VERSION ""

NS_ :

BS_:

BU_: OLDC EWP2 iBAU PSB EWP ESC EVP2 Dummy EVP1 SCU AAF eCALL H_U AEB IBOX LCA MCU SPAS CGW OBC TMU EPB SMK BCF MDPS CPD vDCM ACU vBDM AAF_2 CCM AAF_3 CLU ICSC LVR LDC CDM VCMS FCA IBU SCC PLC VCRM TCU EMS TPMS BMS NEMS LDW_LKA AAF_Tester DATC eCall VESS VCU ODS

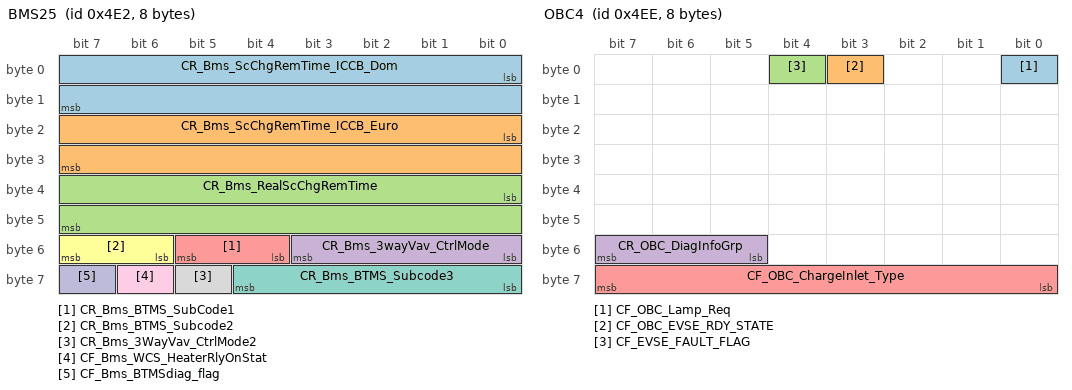
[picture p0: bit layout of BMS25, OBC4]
BO_ 1250 BMS25: 8 BMS
 SG_ CR_Bms_ScChgRemTime_ICCB_Dom : 0|16@1+ (1,0) [0|65535] "minute"  CGW,TMU
 SG_ CR_Bms_ScChgRemTime_ICCB_Euro : 16|16@1+ (1,0) [0|65535] "min"  CGW,TMU
 SG_ CR_Bms_RealScChgRemTime : 32|16@1+ (1,0) [0|65535] "minute"  CGW,TMU
 SG_ CR_Bms_3wayVav_CtrlMode : 48|4@1+ (1,0) [0|1] ""  TMU,vBDM
 SG_ CR_Bms_BTMS_SubCode1 : 52|2@1+ (1,0) [0|3] ""  TMU
 SG_ CR_Bms_BTMS_Subcode2 : 54|2@1+ (1,0) [0|3] ""  TMU
 SG_ CR_Bms_BTMS_Subcode3 : 56|5@1+ (1,0) [0|31] ""  TMU
 SG_ CR_Bms_3WayVav_CtrlMode2 : 61|1@1+ (1,0) [0|1] ""  TMU
 SG_ CF_Bms_WCS_HeaterRlyOnStat : 62|1@1+ (1,0) [0|1] ""  TMU
 SG_ CF_Bms_BTMSdiag_flag : 63|1@1+ (1,0) [0|1] "flag"  TMU

BO_ 1532 ODS13: 5 ODS
 SG_ CR_Ods_ID : 0|8@1+ (1,0) [0|255] ""  ACU
 SG_ ODS_Crc2Val : 8|8@1+ (1,0) [0|0] ""  ACU,Dummy
 SG_ ODS_AlvCnt2Val : 16|4@1+ (1,0) [0|15] ""  ACU,Dummy

BO_ 1262 OBC4: 8 OBC
 SG_ CF_OBC_Lamp_Req : 0|1@1+ (1,0) [0|1] ""  CGW,TMU,vBDM
 SG_ CF_OBC_EVSE_RDY_STATE : 3|1@1+ (1,0) [0|1] ""  BMS,TMU,VCU
 SG_ CF_EVSE_FAULT_FLAG : 4|1@1+ (1,0) [0|1] ""  CCM,CGW,TMU
 SG_ CR_OBC_DiagInfoGrp : 53|3@1+ (1,0) [0|7] ""  Dummy
 SG_ CF_OBC_ChargeInlet_Type : 56|8@1+ (1,0) [0|127] ""  CGW,TMU

BO_ 916 TCS13: 8 iBAU
 SG_ aBasis : 0|11@1+ (0.01,-10.23) [-10.23|10.24] "m/s^2"  Dummy
 SG_ BrakeLight : 11|1@1+ (1,0) [0|1] ""  Dummy
 SG_ DCEnable : 12|1@1+ (1,0) [0|1] ""  Dummy
 SG_ AliveCounterTCS : 13|3@1+ (1,0) [0|7] ""  CGW,vBDM
 SG_ Pre_TCS_CTL : 16|1@1+ (1,0) [0|1] ""  Dummy
 SG_ EBA_ACK : 17|1@1+ (1,0) [0|1] ""  AEB,SCC
 SG_ FCA_ACK : 18|1@1+ (1,0) [0|1] ""  Dummy
 SG_ DF_BF_STAT : 19|2@1+ (1,0) [0|3] ""  CGW
 SG_ SCCReqLim : 21|2@1+ (1,0) [0|3] ""  Dummy
 SG_ TQI_SCC : 23|9@1+ (0.390625,0) [0|199.609375] "%"  VCU
 SG_ ACCEL_REF_SCC : 32|11@1+ (0.01,-10.23) [-10.23|10.24] "m/s^2"  Dummy
 SG_ SCCEnable : 43|2@1+ (1,0) [0|3] ""  Dummy
 SG_ DriverOverride : 45|2@1+ (1,0) [0|3] ""  Dummy
 SG_ StandStill : 47|1@1+ (1,0) [0|1] ""  Dummy
 SG_ CheckSum_TCS3 : 48|4@1+ (1,0) [0|15] ""  Dummy
 SG_ SCC_EQUIP : 52|1@1+ (1,0) [0|1] ""  VCU
 SG_ PBRAKE_ACT : 53|1@1+ (1,0) [0|1] ""  CGW,H_U,TMU
 SG_ SCC_REQ : 54|1@1+ (1,0) [0|1] ""  VCU
 SG_ DriverBraking : 55|1@1+ (1,0) [0|1] ""  VESS
 SG_ DBS_ACK : 56|1@1+ (1,0) [0|1] ""  FCA,LDW_LKA
 SG_ CF_VSM_Avail : 57|2@1+ (1,0) [0|3] ""  Dummy
 SG_ FCA_CODED_STAT : 59|1@1+ (1,0) [0|0] ""  Dummy
 SG_ SCC_CODED_STAT : 60|1@1+ (1,0) [0|0] ""  VCU
 SG_ ESC_BcaRPlusSta : 61|2@1+ (1,0) [0|0] ""  Dummy
 SG_ FCA_EQUIP : 63|1@1+ (1,0) [0|1] ""  Dummy

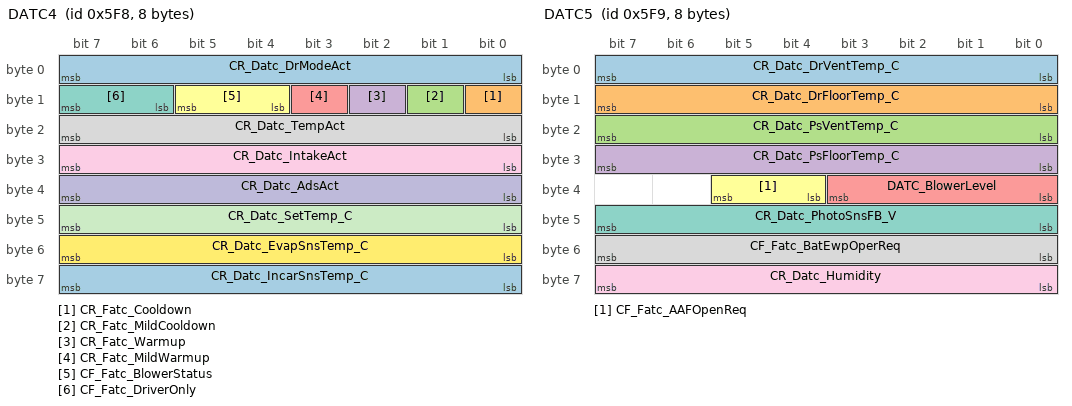
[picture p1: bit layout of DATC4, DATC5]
BO_ 1528 DATC4: 8 DATC
 SG_ CR_Datc_DrModeAct : 0|8@1+ (0.02,0) [0|5] "V"  VCU
 SG_ CR_Fatc_Cooldown : 8|1@1+ (1,0) [0|1] ""  LDC,VCU
 SG_ CR_Fatc_MildCooldown : 9|1@1+ (1,0) [0|1] ""  LDC,VCU
 SG_ CR_Fatc_Warmup : 10|1@1+ (1,0) [0|1] ""  LDC,VCU
 SG_ CR_Fatc_MildWarmup : 11|1@1+ (1,0) [0|1] ""  LDC,VCU
 SG_ CF_Fatc_BlowerStatus : 12|2@1+ (1,0) [0|3] ""  VCU
 SG_ CF_Fatc_DriverOnly : 14|2@1+ (1,0) [0|3] ""  CGW,VCU
 SG_ CR_Datc_TempAct : 16|8@1+ (0.02,0) [0|5] "V"  VCU
 SG_ CR_Datc_IntakeAct : 24|8@1+ (0.02,0) [0|5] "V"  VCU
 SG_ CR_Datc_AdsAct : 32|8@1+ (0.02,0) [0|5] "V"  VCU
 SG_ CR_Datc_SetTemp_C : 40|8@1+ (0.5,-40) [-40|60] "¡É"  TMU,VCU
 SG_ CR_Datc_EvapSnsTemp_C : 48|8@1+ (0.5,-40) [-40|60] "¡É"  VCU
 SG_ CR_Datc_IncarSnsTemp_C : 56|8@1+ (0.5,-40) [-40|60] "¡É"  BMS,TMU,VCU

BO_ 1529 DATC5: 8 DATC
 SG_ CR_Datc_DrVentTemp_C : 0|8@1+ (0.5,-40) [-40|60] "¡É"  CGW,VCU,vBDM
 SG_ CR_Datc_DrFloorTemp_C : 8|8@1+ (0.5,-40) [-40|60] "¡É"  VCU
 SG_ CR_Datc_PsVentTemp_C : 16|8@1+ (0.5,-40) [-40|60] "¡É"  VCU
 SG_ CR_Datc_PsFloorTemp_C : 24|8@1+ (0.5,-40) [-40|60] "¡É"  VCU
 SG_ DATC_BlowerLevel : 32|4@1+ (1,0) [0|15] "flag"  TMU,VCU
 SG_ CF_Fatc_AAFOpenReq : 36|2@1+ (1,0) [0|3] ""  AAF
 SG_ CR_Datc_PhotoSnsFB_V : 40|8@1+ (0.02,0) [0|5] "V"  VCU
 SG_ CF_Fatc_BatEwpOperReq : 48|8@1+ (30,0) [0|7620] "rpm"  BMS,MCU
 SG_ CR_Datc_Humidity : 56|8@1+ (0.5,0) [0|100] "%"  VCU

BO_ 2015 GST1: 8 CGW
 SG_ FRM_FORMAT : 0|8@1+ (1,0) [0|31] ""  AAF,ACU,BMS,DATC,EWP,LDC,MCU,ODS,VCU,VESS,iBAU
 SG_ SID : 8|8@1+ (1,0) [0|255] ""  AAF,ACU,BMS,DATC,EWP,LDC,MCU,ODS,VCU,VESS,iBAU
 SG_ REQ_RESPONSE : 16|8@1+ (1,0) [0|2] ""  AAF,ACU,BMS,DATC,EWP,LDC,MCU,ODS,VCU,VESS,iBAU

BO_ 1530 ODS11: 8 ODS
 SG_ ODS_Crc1Val : 0|8@1+ (1,0) [0|0] ""  ACU,Dummy
 SG_ ODS_AlvCnt1Val : 8|4@1+ (1,0) [0|15] ""  ACU,Dummy
 SG_ CR_Wcs_ErrStat : 32|8@1+ (1,0) [0|63] ""  ACU
 SG_ CR_Wcs_ClassStat : 40|8@1+ (1,0) [0|4] ""  ACU,CGW,H_U,TMU,VCU

BO_ 911 WHL_SPD13_FS: 5 iBAU
 SG_ CRC : 0|8@1+ (1,0) [0|0] ""  Dummy,ODS
 SG_ WHL_SPD13_AliveCounter : 8|4@1+ (1,0) [0|15] ""  Dummy,ODS
 SG_ WHL_SPD_RL : 12|14@1+ (0.03125,0) [0|511.96875] "km/h"  Dummy,ODS
 SG_ WHL_SPD_RR : 26|14@1+ (0.03125,0) [0|511.96875] "km/h"  Dummy,ODS

BO_ 1509 CCM1: 8 CCM
 SG_ CR_Ccm_MaxVolt_V : 0|16@1+ (0.1,0) [0|6553.5] "V"  BMS
 SG_ CR_Ccm_MaxCurr_A : 16|16@1+ (0.1,0) [0|6553.5] "A"  BMS,CGW,vBDM
 SG_ CR_Ccm_OutVolt : 32|16@1+ (0.1,0) [0|6553.5] "V"  BMS
 SG_ CR_Ccm_OutCurr : 48|16@1+ (0.1,0) [0|6553.5] "A"  BMS

BO_ 910 WHL_SPD12_FS: 5 iBAU
 SG_ CRC : 0|8@1+ (1,0) [0|0] ""  Dummy,ODS
 SG_ WHL_SPD12_AliveCounter : 8|4@1+ (1,0) [0|15] ""  Dummy,ODS
 SG_ WHL_SPD_FL : 12|14@1+ (0.03125,0) [0|511.96875] "km/h"  Dummy,ODS
 SG_ WHL_SPD_FR : 26|14@1+ (0.03125,0) [0|511.96875] "km/h"  Dummy,ODS

BO_ 1511 CCM3: 8 CCM
 SG_ CR_Ccm_EvseSAID : 0|16@1+ (1,0) [0|65535] ""  Dummy
 SG_ CR_Ccm_EvsePmaxID : 16|16@1+ (1,0) [0|65535] ""  Dummy
 SG_ CR_Ccm_EvsePmaxEntry : 32|16@1+ (1,0) [0|65535] ""  Dummy
 SG_ CR_Ccm_EvsePmax : 48|16@1+ (10,0) [0|655350] "W"  CGW,Dummy,vBDM

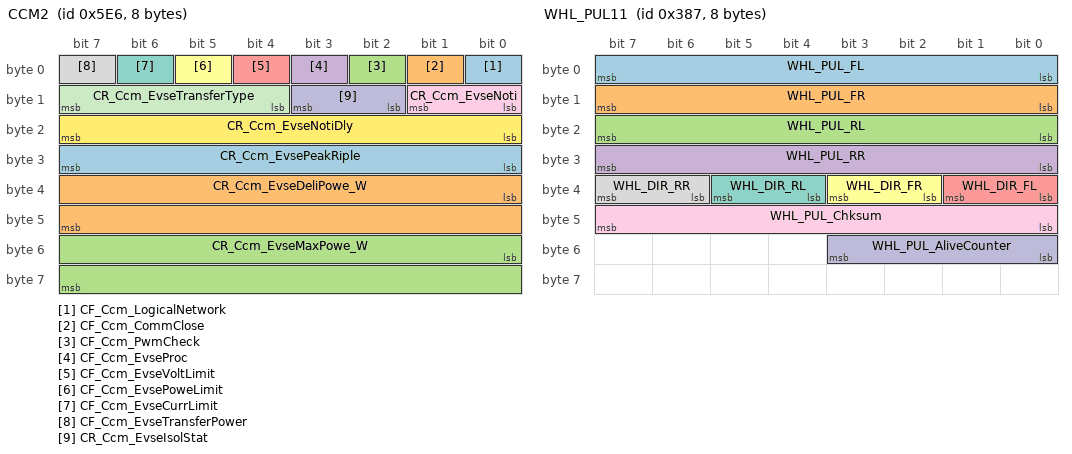
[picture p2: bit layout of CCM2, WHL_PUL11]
BO_ 1510 CCM2: 8 CCM
 SG_ CF_Ccm_LogicalNetwork : 0|1@1+ (1,0) [0|1] ""  BMS
 SG_ CF_Ccm_CommClose : 1|1@1+ (1,0) [0|1] ""  BMS
 SG_ CF_Ccm_PwmCheck : 2|1@1+ (1,0) [0|1] ""  BMS
 SG_ CF_Ccm_EvseProc : 3|1@1+ (1,0) [0|1] ""  BMS
 SG_ CF_Ccm_EvseVoltLimit : 4|1@1+ (1,0) [0|1] ""  BMS
 SG_ CF_Ccm_EvsePoweLimit : 5|1@1+ (1,0) [0|1] ""  BMS
 SG_ CF_Ccm_EvseCurrLimit : 6|1@1+ (1,0) [0|1] ""  BMS
 SG_ CF_Ccm_EvseTransferPower : 7|1@1+ (1,0) [0|1] ""  BMS
 SG_ CR_Ccm_EvseNoti : 8|2@1+ (1,0) [0|3] ""  BMS
 SG_ CR_Ccm_EvseIsolStat : 10|2@1+ (1,0) [0|3] ""  BMS,CGW,vBDM
 SG_ CR_Ccm_EvseTransferType : 12|4@1+ (1,0) [0|15] ""  BMS
 SG_ CR_Ccm_EvseNotiDly : 16|8@1+ (1,0) [0|255] "Sec"  BMS
 SG_ CR_Ccm_EvsePeakRiple : 24|8@1+ (1,0) [0|255] "A"  BMS
 SG_ CR_Ccm_EvseDeliPowe_W : 32|16@1+ (10,0) [0|655350] "Wh"  BMS
 SG_ CR_Ccm_EvseMaxPowe_W : 48|16@1+ (10,0) [0|655350] "W"  BMS

BO_ 1507 VESS1: 8 VESS
 SG_ CR_VCU_EcoLvl : 0|1@1+ (1,0) [0|1] ""  CGW,TMU,vBDM

BO_ 903 WHL_PUL11: 8 iBAU
 SG_ WHL_PUL_FL : 0|8@1+ (0.5,0) [0|127.5] "pulse count"  CGW,IBU,TMU,eCall
 SG_ WHL_PUL_FR : 8|8@1+ (0.5,0) [0|127.5] "pulse count"  CGW,IBU,TMU,eCall
 SG_ WHL_PUL_RL : 16|8@1+ (0.5,0) [0|127.5] "pulse count"  CGW,IBU,TMU,eCall
 SG_ WHL_PUL_RR : 24|8@1+ (0.5,0) [0|127.5] "pulse count"  CGW,IBU,TMU,eCall
 SG_ WHL_DIR_FL : 32|2@1+ (1,0) [0|3] ""  IBU,TMU
 SG_ WHL_DIR_FR : 34|2@1+ (1,0) [0|3] ""  IBU,TMU
 SG_ WHL_DIR_RL : 36|2@1+ (1,0) [0|3] ""  IBU,TMU
 SG_ WHL_DIR_RR : 38|2@1+ (1,0) [0|3] ""  IBU,TMU
 SG_ WHL_PUL_Chksum : 40|8@1+ (1,0) [0|255] ""  IBOX,IBU
 SG_ WHL_PUL_AliveCounter : 48|4@1+ (1,0) [0|14] ""  AEB,SCC

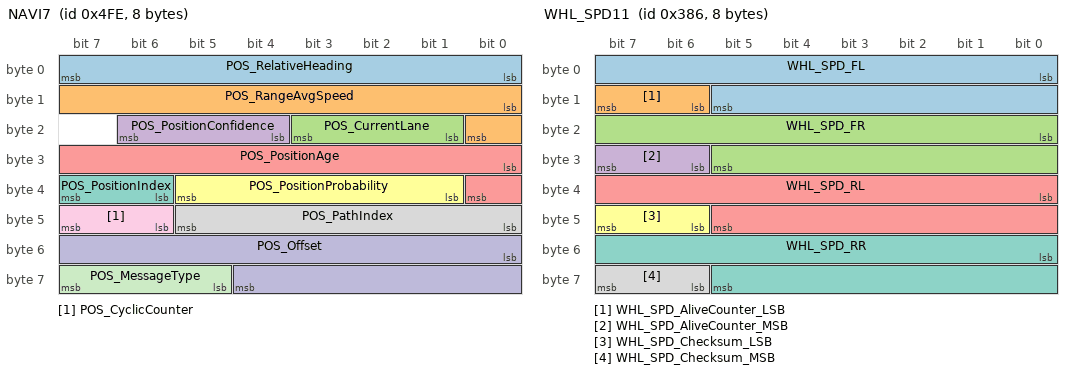
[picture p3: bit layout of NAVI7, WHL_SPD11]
BO_ 1278 NAVI7: 8 CGW
 SG_ POS_RelativeHeading : 0|8@1+ (1.417,0) [0|255] ""  VCU
 SG_ POS_RangeAvgSpeed : 8|9@1+ (1,0) [0|511] ""  VCU
 SG_ POS_CurrentLane : 17|3@1+ (1,0) [0|7] ""  VCU
 SG_ POS_PositionConfidence : 20|3@1+ (1,0) [0|7] ""  VCU
 SG_ POS_PositionAge : 24|9@1+ (5,0) [0|511] ""  VCU
 SG_ POS_PositionProbability : 33|5@1+ (3.333,0) [0|31] ""  VCU
 SG_ POS_PositionIndex : 38|2@1+ (1,0) [0|3] ""  VCU
 SG_ POS_PathIndex : 40|6@1+ (1,0) [0|63] ""  VCU
 SG_ POS_CyclicCounter : 46|2@1+ (1,0) [0|3] ""  VCU
 SG_ POS_Offset : 48|13@1+ (1,0) [0|8191] ""  VCU
 SG_ POS_MessageType : 61|3@1+ (1,0) [0|7] ""  VCU

BO_ 902 WHL_SPD11: 8 iBAU
 SG_ WHL_SPD_FL : 0|14@1+ (0.03125,0) [0|511.96875] "km/h"  ACU,CGW,DATC,EVP1,EVP2,IBU,MCU,ODS,VCU,VESS,vBDM
 SG_ WHL_SPD_AliveCounter_LSB : 14|2@1+ (1,0) [0|3] ""  CGW,ODS,TMU
 SG_ WHL_SPD_FR : 16|14@1+ (0.03125,0) [0|511.96875] "km/h"  ACU,DATC,EVP1,EVP2,IBU,MCU,ODS,VCU,VESS
 SG_ WHL_SPD_AliveCounter_MSB : 30|2@1+ (1,0) [0|3] ""  CGW,ODS,TMU
 SG_ WHL_SPD_RL : 32|14@1+ (0.03125,0) [0|511.96875] "km/h"  ACU,CDM,DATC,EVP1,EVP2,IBU,MCU,OBC,ODS,VCU,VESS
 SG_ WHL_SPD_Checksum_LSB : 46|2@1+ (1,0) [0|3] ""  CGW,ODS,TMU
 SG_ WHL_SPD_RR : 48|14@1+ (0.03125,0) [0|511.96875] "km/h"  ACU,CDM,DATC,EVP1,EVP2,IBU,MCU,OBC,ODS,VCU,VESS
 SG_ WHL_SPD_Checksum_MSB : 62|2@1+ (1,0) [0|3] ""  CGW,ODS,TMU

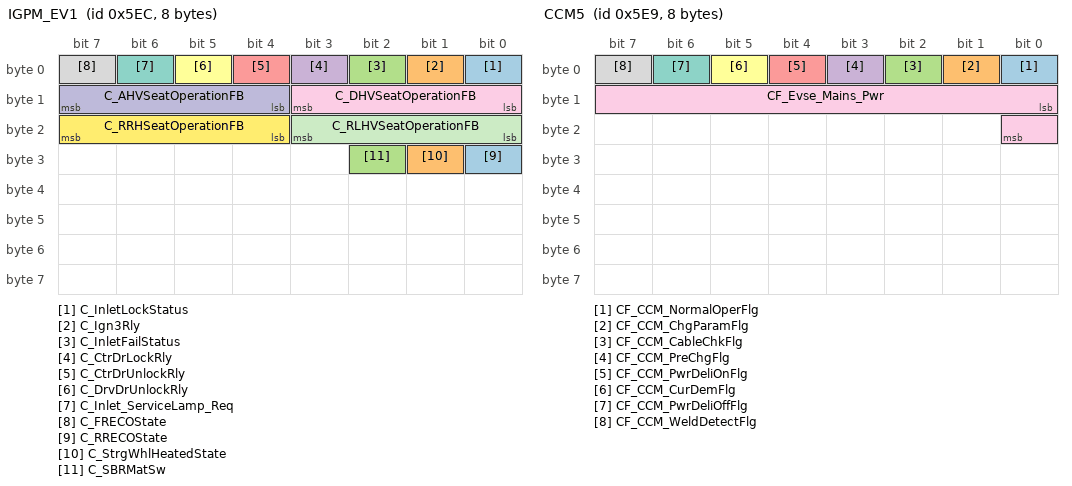
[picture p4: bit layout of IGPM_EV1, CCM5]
BO_ 1516 IGPM_EV1: 8 CGW
 SG_ C_InletLockStatus : 0|1@1+ (1,0) [0|1] ""  OBC
 SG_ C_Ign3Rly : 1|1@1+ (1,0) [0|1] ""  CDM,OBC
 SG_ C_InletFailStatus : 2|1@1+ (1,0) [0|1] ""  OBC
 SG_ C_CtrDrLockRly : 3|1@1+ (1,0) [0|0] ""  CDM,OBC
 SG_ C_CtrDrUnlockRly : 4|1@1+ (1,0) [0|0] ""  CDM,OBC
 SG_ C_DrvDrUnlockRly : 5|1@1+ (1,0) [0|0] ""  CDM,OBC
 SG_ C_Inlet_ServiceLamp_Req : 6|1@1+ (1,0) [0|0] ""  OBC
 SG_ C_FRECOState : 7|1@1+ (1,0) [0|1] ""  VCU
 SG_ C_DHVSeatOperationFB : 8|4@1+ (1,0) [0|15] ""  VCU
 SG_ C_AHVSeatOperationFB : 12|4@1+ (1,0) [0|15] ""  VCU
 SG_ C_RLHVSeatOperationFB : 16|4@1+ (1,0) [0|15] ""  VCU
 SG_ C_RRHSeatOperationFB : 20|4@1+ (1,0) [0|15] ""  VCU
 SG_ C_RRECOState : 24|1@1+ (1,0) [0|1] ""  VCU
 SG_ C_StrgWhlHeatedState : 25|1@1+ (1,0) [0|0] ""  VCU
 SG_ C_SBRMatSw : 26|1@1+ (1,0) [0|1] ""  VCU

BO_ 1276 AAF31: 8 AAF_3
 SG_ CF_Aaf31_ActFlapStatus : 0|2@1+ (1,0) [0|3] ""  AAF
 SG_ CF_Aaf31_ErrStatus : 6|10@1+ (1,0) [0|1023] ""  AAF
 SG_ CF_Aaf31_PStatus : 24|8@1+ (1,0) [0|100] "%"  AAF
 SG_ CF_Aaf31_PStatusSub : 32|8@1+ (1,0) [0|100] "%"  AAF

BO_ 1277 AAF21: 8 AAF_2
 SG_ CF_Aaf21_ActFlapStatus : 0|2@1+ (1,0) [0|3] ""  AAF
 SG_ CF_Aaf21_ErrStatus : 6|10@1+ (1,0) [0|1023] ""  AAF
 SG_ CF_Aaf21_PStatus : 24|8@1+ (1,0) [0|100] "%"  AAF
 SG_ CF_Aaf21_PStatusSub : 32|8@1+ (1,0) [0|100] "%"  AAF

BO_ 1513 CCM5: 8 CCM
 SG_ CF_CCM_NormalOperFlg : 0|1@1+ (1,0) [0|1] ""  BMS
 SG_ CF_CCM_ChgParamFlg : 1|1@1+ (1,0) [0|1] ""  BMS
 SG_ CF_CCM_CableChkFlg : 2|1@1+ (1,0) [0|1] ""  BMS,CGW,vBDM
 SG_ CF_CCM_PreChgFlg : 3|1@1+ (1,0) [0|1] ""  BMS
 SG_ CF_CCM_PwrDeliOnFlg : 4|1@1+ (1,0) [0|1] ""  BMS
 SG_ CF_CCM_CurDemFlg : 5|1@1+ (1,0) [0|1] ""  BMS
 SG_ CF_CCM_PwrDeliOffFlg : 6|1@1+ (1,0) [0|1] ""  BMS,OBC
 SG_ CF_CCM_WeldDetectFlg : 7|1@1+ (1,0) [0|1] ""  BMS
 SG_ CF_Evse_Mains_Pwr : 8|9@1+ (1,0) [0|400] "kW"  BMS,CGW,OBC

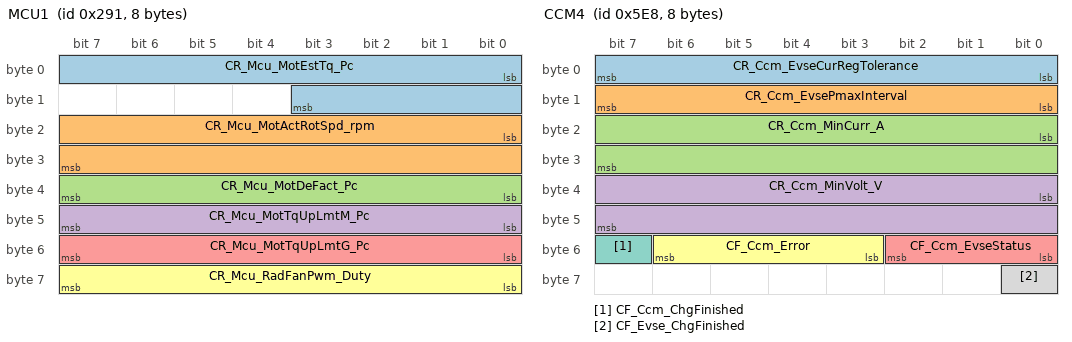
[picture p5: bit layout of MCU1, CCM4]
BO_ 657 MCU1: 8 MCU
 SG_ CR_Mcu_MotEstTq_Pc : 0|12@1- (0.048828125,0) [-100|99.951171875] "%"  BMS,CGW,LDC,NEMS,TMU,VCU,VESS,iBAU
 SG_ CR_Mcu_MotActRotSpd_rpm : 16|16@1- (1,0) [-32768|32767] "rpm"  AAF,ACU,BMS,CGW,LDC,NEMS,VCU,VESS,iBAU,vBDM
 SG_ CR_Mcu_MotDeFact_Pc : 32|8@1+ (0.3906,0) [0|99.61] "%"  VCU,iBAU
 SG_ CR_Mcu_MotTqUpLmtM_Pc : 40|8@1+ (0.3906,0) [0|99.61] "%"  VCU
 SG_ CR_Mcu_MotTqUpLmtG_Pc : 48|8@1+ (0.3906,0) [0|99.61] "%"  VCU
 SG_ CR_Mcu_RadFanPwm_Duty : 56|8@1+ (1,0) [0|100] "%"  AAF,BMS,VCU

BO_ 1512 CCM4: 8 CCM
 SG_ CR_Ccm_EvseCurRegTolerance : 0|8@1+ (1,0) [0|255] "A"  BMS
 SG_ CR_Ccm_EvsePmaxInterval : 8|8@1+ (1,0) [0|255] "Sec"  BMS
 SG_ CR_Ccm_MinCurr_A : 16|16@1+ (0.1,0) [0|6553.5] "A"  BMS
 SG_ CR_Ccm_MinVolt_V : 32|16@1+ (0.1,0) [0|6553.5] "V"  BMS
 SG_ CF_Ccm_EvseStatus : 48|3@1+ (1,0) [0|7] ""  BMS,OBC
 SG_ CF_Ccm_Error : 51|4@1+ (1,0) [0|15] ""  BMS
 SG_ CF_Ccm_ChgFinished : 55|1@1+ (1,0) [0|1] ""  BMS,CGW,OBC,vBDM
 SG_ CF_Evse_ChgFinished : 56|1@1+ (1,0) [0|1] ""  BMS,OBC

BO_ 1426 VCU5: 8 VCU
 SG_ CF_Vcu_DefrostCtr : 0|1@1+ (1,0) [0|1] ""  DATC,TMU
 SG_ CF_Vcu_LowSocLp : 1|1@1+ (1,0) [0|1] ""  CGW,TMU
 SG_ CF_Vcu_DteOff : 2|1@1+ (1,0) [0|1] ""  CGW,TMU
 SG_ CF_Vcu_SerLamp : 3|1@1+ (1,0) [0|1] ""  CGW,TMU
 SG_ CF_Vcu_EcoSco : 4|4@1+ (1,0) [0|15] ""  CGW,TMU
 SG_ CR_Vcu_ClimatePerm_W : 8|8@1+ (50,0) [0|12700] "W"  DATC,TMU
 SG_ CR_Vcu_FuelEco_KP100km : 16|8@1+ (0.5,0) [0|126.5] ""  CGW,TMU
 SG_ CR_Vcu_FatcCst : 24|8@1+ (10,0) [0|2550] "W"  CGW
 SG_ CF_Vcu_ChrgAlert : 32|1@1+ (1,0) [0|1] ""  CGW,TMU
 SG_ CF_Vcu_PwrDnMode : 33|1@1+ (1,0) [0|1] ""  CGW,TMU,vBDM
 SG_ CF_Vcu_CruOnLamp : 34|1@1+ (1,0) [0|1] ""  CGW,TMU
 SG_ CF_Vcu_CruSetLamp : 35|1@1+ (1,0) [0|1] ""  CGW,TMU
 SG_ CF_Vcu_ThiBatTir : 36|1@1+ (1,0) [0|1] ""  CGW,TMU
 SG_ CF_Vcu_LdcMod : 37|2@1+ (1,0) [0|2] ""  CGW,LDC,TMU
 SG_ CF_Vcu_ACnChr : 39|1@1+ (1,0) [0|1] ""  CGW,TMU
 SG_ CR_Vcu_TqMotClu_Pc : 40|8@1- (1,0) [-100|100] "%"  CGW,TMU
 SG_ CR_Vcu_FuelEco_KPK : 48|8@1+ (0.1,0) [0|25.5] "km/kWh"  CGW,LDC,TMU
 SG_ CF_Vcu_LdcInh : 56|1@1+ (1,0) [0|1] ""  CGW,LDC,TMU
 SG_ CF_Vcu_BrkLpReq : 57|1@1+ (1,0) [0|1] ""  CGW,TMU,iBAU
 SG_ CF_Vcu_EvMod : 58|4@1+ (1,0) [0|9] ""  CGW,DATC,NEMS,TMU,VESS,iBAU
 SG_ CF_Vcu_PgmRun5 : 62|2@1+ (1,0) [0|3] ""  CGW,TMU

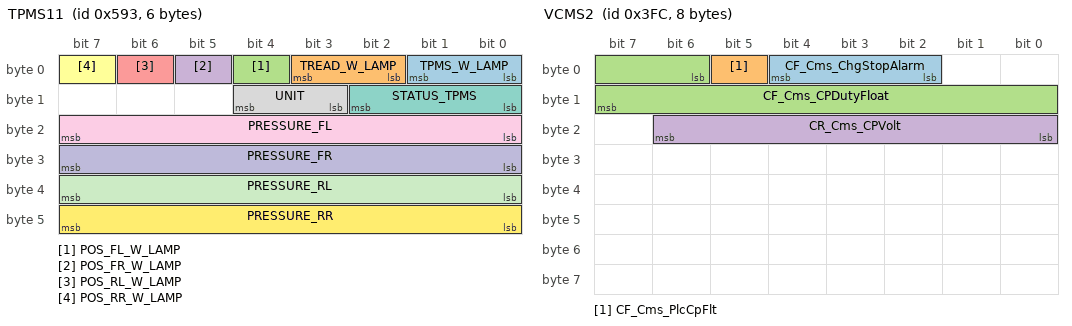
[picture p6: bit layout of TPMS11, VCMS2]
BO_ 1427 TPMS11: 6 IBU
 SG_ TPMS_W_LAMP : 0|2@1+ (1,0) [0|3] ""  CGW,H_U,TMU,vBDM
 SG_ TREAD_W_LAMP : 2|2@1+ (1,0) [0|3] ""  CGW,H_U,TMU
 SG_ POS_FL_W_LAMP : 4|1@1+ (1,0) [0|1] ""  CGW,H_U,TMU
 SG_ POS_FR_W_LAMP : 5|1@1+ (1,0) [0|1] ""  CGW,H_U,TMU
 SG_ POS_RL_W_LAMP : 6|1@1+ (1,0) [0|1] ""  CGW,H_U,TMU
 SG_ POS_RR_W_LAMP : 7|1@1+ (1,0) [0|1] ""  CGW,H_U,TMU
 SG_ STATUS_TPMS : 8|3@1+ (1,0) [0|0] ""  ESC,IBOX,ICSC,CGW
 SG_ UNIT : 11|2@1+ (1,0) [0|3] ""  IBOX,CGW
 SG_ PRESSURE_FL : 16|8@1+ (1,0) [0|255] "PSI"  IBOX,CGW
 SG_ PRESSURE_FR : 24|8@1+ (1,0) [0|255] "PSI"  IBOX,CGW
 SG_ PRESSURE_RL : 32|8@1+ (1,0) [0|255] "PSI"  IBOX,CGW
 SG_ PRESSURE_RR : 40|8@1+ (1,0) [0|255] "PSI"  IBOX,CGW

BO_ 1424 LDC1: 8 LDC
 SG_ CF_Ldc_Rdy : 0|1@1+ (1,0) [0|1] ""  TMU,VCU
 SG_ CF_Ldc_Controllable : 1|1@1+ (1,0) [0|1] ""  TMU,VCU
 SG_ CF_Ldc_12VCharge : 2|1@1+ (1,0) [0|1] ""  CGW,NEMS,TMU,VCU
 SG_ CF_Ldc_Pd_Stat : 3|1@1+ (1,0) [0|1] ""  CGW,MCU,NEMS,TMU,VCU
 SG_ CF_Ldc_AuxBatWrnLamp : 4|1@1+ (1,0) [0|1] ""  CGW,TMU
 SG_ CF_Ldc_AuxBatWrnAlarm : 5|1@1+ (1,0) [0|1] ""  CGW,TMU
 SG_ CF_Ldc_AuxBatCharge_Rqst : 6|1@1+ (1,0) [0|1] ""  TMU,VCU
 SG_ CF_Ldc_AuxBatCharge_Reset : 7|1@1+ (1,0) [0|1] ""  TMU,VCU
 SG_ CF_Ldc_Srvlamp_Rqst : 8|1@1+ (1,0) [0|1] ""  CGW,H_U,TMU,vBDM
 SG_ CF_Ldc_Flt : 9|1@1+ (1,0) [0|1] ""  AAF,BMS,CGW,H_U,MCU,NEMS,OBC,TMU,VCU
 SG_ CF_Ldc_AuxBatChg_State : 12|2@1+ (1,0) [0|3] ""  BMS,CGW
 SG_ CF_Ldc_RadFanCnt : 14|1@1+ (1,0) [0|1] ""  EMS,MCU,TMU
 SG_ CF_Ldc_Bat_dischrg : 15|1@1+ (1,0) [0|1] ""  CGW
 SG_ CR_Ldc_ActCur_LS_A : 16|8@1+ (1,0) [0|255] "A"  MCU,TMU
 SG_ CR_Ldc_RadFanReq_Duty : 24|8@1+ (1,0) [0|100] "%"  MCU,TMU,VCU
 SG_ CR_Ldc_ActVol_LS_V : 32|8@1+ (0.1,0) [0|25.5] "V"  CGW,MCU,OBC,TMU
 SG_ CR_Ldc_EWPRpmCnt : 40|8@1+ (20,0) [0|5000] "rpm"  MCU,TMU,VCU
 SG_ CR_Ldc_PwrMon_W : 48|8@1+ (10,0) [0|2550] "W"  CGW,TMU,VCU
 SG_ CR_Ldc_Tmp : 56|8@1+ (1,-100) [-100|155] "¡É"  AAF,TMU,VCU

BO_ 1019 VCMS1: 8 VCMS
 SG_ CF_Cms_PDStatus : 1|2@1+ (1,0) [0|3] ""  BMS,CCM,OBC
 SG_ CF_Cms_ChgFinished : 3|1@1+ (1,0) [0|1] "flag"  BMS,CCM,OBC
 SG_ CF_Cms_EvseRdyState : 4|1@1+ (1,0) [0|1] "flag"  BMS,CCM,OBC
 SG_ CF_Cms_Wrn : 5|1@1+ (1,0) [0|1] "flag"  BMS,CCM,OBC
 SG_ CF_Cms_Flt : 6|1@1+ (1,0) [0|1] ""  BMS,CCM,OBC
 SG_ CF_Cms_Rdy : 7|1@1+ (1,0) [0|1] ""  BMS,CCM,OBC
 SG_ CF_Cms_IG3DrvStat : 32|1@1+ (1,0) [0|1] "flag"  BMS,CCM,OBC
 SG_ CF_Cms_PlugConnect : 33|1@1+ (1,0) [0|1] "flag"  BMS,CCM,OBC
 SG_ CF_Cms_S2SWOnStat : 34|1@1+ (1,0) [0|1] "flag"  BMS,CCM,OBC
 SG_ CF_Cms_ForcedDischReq : 35|1@1+ (1,0) [0|1] "flag"  MCU
 SG_ CF_Cms_MILReq : 37|1@1+ (1,0) [0|1] "flag"  BMS,CCM,OBC
 SG_ CF_Cms_VCRM_Req : 38|2@1+ (1,0) [0|3] "flag"  CGW,H_U,vBDM
 SG_ CF_Cms_ServiceLampReq : 42|1@1+ (1,0) [0|1] "flag"  CGW,H_U
 SG_ CF_Cms_EvseFltStat : 44|1@1+ (1,0) [0|1] "flag"  CCM
 SG_ CF_Cms_DCChargingStat : 45|1@1+ (1,0) [0|1] "flag"  BMS,CCM,OBC
 SG_ CF_Cms_ACChargingStat : 46|1@1+ (1,0) [0|1] "flag"  BMS,CCM,OBC
 SG_ CF_Cms_ImmeChgSwState : 47|1@1+ (1,0) [0|1] "flag"  VCU
 SG_ CF_Cms_ChargeInit : 56|1@1+ (1,0) [0|1] "flag"  BMS,CCM,OBC
 SG_ CF_Cms_ChargingCycle : 57|1@1+ (1,0) [0|1] "flag"  BMS,CCM,OBC

BO_ 1020 VCMS2: 8 VCMS
 SG_ CF_Cms_ChgStopAlarm : 2|3@1+ (1,0) [0|7] "flag"  BMS,CCM,OBC
 SG_ CF_Cms_PlcCpFlt : 5|1@1+ (1,0) [0|1] "flag"  CCM,OBC
 SG_ CF_Cms_CPDutyFloat : 6|10@1+ (0.1,0) [0|102.3] ""  BMS,CCM,OBC
 SG_ CR_Cms_CPVolt : 16|7@1+ (0.1,0) [0|12.7] "V"  BMS,CCM,OBC

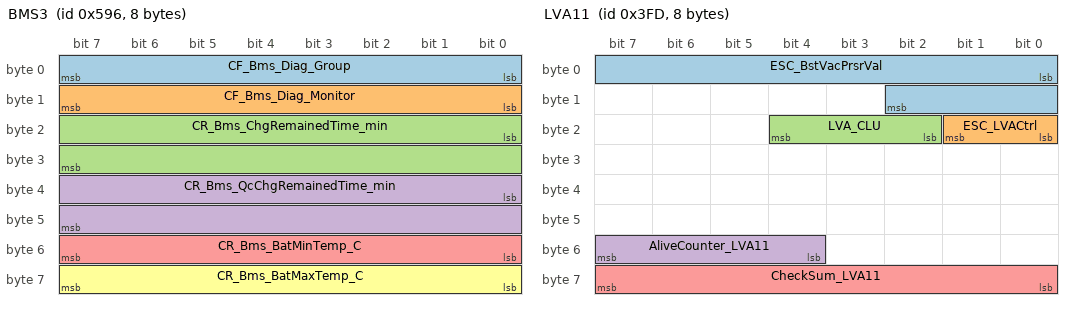
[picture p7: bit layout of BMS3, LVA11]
BO_ 1430 BMS3: 8 BMS
 SG_ CF_Bms_Diag_Group : 0|8@1+ (1,0) [0|255] ""  CGW,DATC,TMU,VCU,vBDM
 SG_ CF_Bms_Diag_Monitor : 8|8@1+ (1,0) [0|255] ""  CGW,TMU,VCU
 SG_ CR_Bms_ChgRemainedTime_min : 16|16@1+ (1,0) [0|65535] "min"  CGW,TMU
 SG_ CR_Bms_QcChgRemainedTime_min : 32|16@1+ (1,0) [0|65535] "min"  CGW,TMU
 SG_ CR_Bms_BatMinTemp_C : 48|8@1- (1,0) [-128|126] "¡É"  CGW,TMU,VCU
 SG_ CR_Bms_BatMaxTemp_C : 56|8@1- (1,0) [-128|126] "¡É"  AAF,CGW,TMU,VCU

BO_ 1021 LVA11: 8 iBAU
 SG_ ESC_BstVacPrsrVal : 0|11@1+ (1,0) [0|2046] "hPa"  EVP1,EVP2
 SG_ ESC_LVACtrl : 16|2@1+ (1,0) [0|3] ""  Dummy
 SG_ LVA_CLU : 18|3@1+ (1,0) [0|7] ""  CGW
 SG_ AliveCounter_LVA11 : 52|4@1+ (1,0) [0|15] ""  Dummy
 SG_ CheckSum_LVA11 : 56|8@1+ (1,0) [0|255] ""  Dummy

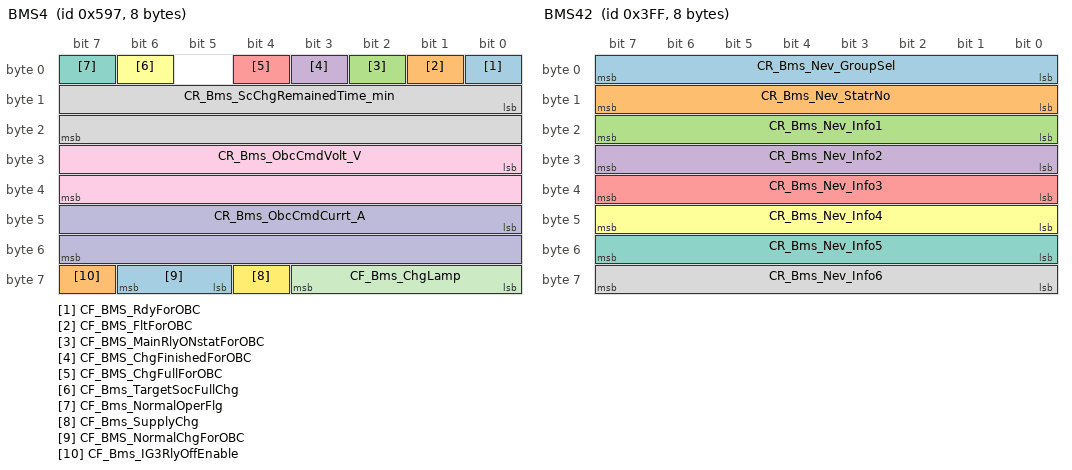
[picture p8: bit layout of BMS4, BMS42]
BO_ 1431 BMS4: 8 BMS
 SG_ CF_BMS_RdyForOBC : 0|1@1+ (1,0) [0|1] ""  OBC
 SG_ CF_BMS_FltForOBC : 1|1@1+ (1,0) [0|1] ""  OBC
 SG_ CF_BMS_MainRlyONstatForOBC : 2|1@1+ (1,0) [0|1] ""  OBC
 SG_ CF_BMS_ChgFinishedForOBC : 3|1@1+ (1,0) [0|1] ""  CGW,OBC,TMU,vBDM
 SG_ CF_BMS_ChgFullForOBC : 4|1@1+ (1,0) [0|1] ""  OBC
 SG_ CF_Bms_TargetSocFullChg : 6|1@1+ (1,0) [0|1] ""  OBC,VCU
 SG_ CF_Bms_NormalOperFlg : 7|1@1+ (1,0) [0|1] "flag"  CCM,OBC
 SG_ CR_Bms_ScChgRemainedTime_min : 8|16@1+ (1,0) [0|65535] "min"  CGW,TMU
 SG_ CR_Bms_ObcCmdVolt_V : 24|16@1+ (0.1,0) [0|1000] "V"  OBC
 SG_ CR_Bms_ObcCmdCurrt_A : 40|16@1+ (0.1,0) [0|150] "A"  OBC
 SG_ CF_Bms_ChgLamp : 56|4@1+ (1,0) [0|7] ""  CDM,Dummy
 SG_ CF_Bms_SupplyChg : 60|1@1+ (1,0) [0|1] ""  OBC
 SG_ CF_BMS_NormalChgForOBC : 61|2@1+ (1,0) [0|3] ""  CGW,OBC,TMU,VCU
 SG_ CF_Bms_IG3RlyOffEnable : 63|1@1+ (1,0) [0|1] "flag"  CDM,OBC

BO_ 1022 VCMS4: 8 VCMS
 SG_ CR_Cms_ObcCmdOutVolt : 0|16@1+ (0.1,0) [0|1000] "V"  OBC
 SG_ CR_Cms_ObcCmdOutCur : 16|16@1+ (0.1,0) [0|150] "A"  OBC
 SG_ CR_Cms_ObcCmdInCur : 32|16@1+ (0.1,0) [0|150] "A"  OBC
 SG_ CR_Cms_CpFltStat : 48|2@1+ (1,0) [0|3] ""  CCM,OBC

BO_ 1428 BMS1: 8 BMS
 SG_ CR_Bms_BatChaLmt_W : 0|16@1+ (10,0) [0|655350] "W"  CGW,MCU,TMU,VCU
 SG_ CR_Bms_BatDchLmt_W : 16|16@1+ (10,0) [0|655350] "W"  CGW,MCU,TMU,VCU
 SG_ CF_Bms_LowtempStatus : 32|1@1+ (1,0) [0|1] ""  CGW,TMU
 SG_ CF_Bms_ServiceLamp : 33|1@1+ (1,0) [0|1] ""  CGW,TMU,VCU
 SG_ CF_Bms_MainRlyOnStat : 34|1@1+ (1,0) [0|1] ""  CGW,DATC,LDC,MCU,TMU,VCU
 SG_ CF_Bms_Rly_Off_Req : 35|1@1+ (1,0) [0|1] ""  CGW,TMU,VCU
 SG_ CF_Bms_Flt : 36|1@1+ (1,0) [0|1] ""  CGW,DATC,LDC,MCU,TMU,VCU,iBAU
 SG_ CF_Bms_Wrn : 37|1@1+ (1,0) [0|1] ""  CGW,MCU,TMU,VCU,iBAU
 SG_ CF_Bms_Ctrb : 38|1@1+ (1,0) [0|1] ""  CGW,LDC,TMU,VCU
 SG_ CF_Bms_Rdy : 39|1@1+ (1,0) [0|1] ""  CGW,MCU,TMU,VCU
 SG_ CR_Bms_Soc_Pc : 40|8@1+ (0.5,0) [0|100] "%"  CGW,H_U,LDC,MCU,OBC,TMU,VCU,iBAU,vBDM
 SG_ CR_Bms_SocDec_Pc : 48|3@1+ (1,0) [0|4] "%"  CGW,TMU,VCU
 SG_ CF_Bms_SupplyChgStat : 51|2@1+ (1,0) [0|3] ""  CGW,TMU,VCU
 SG_ CR_Bms_WinterMode : 53|2@1+ (1,0) [0|0] ""  CGW,TMU,VCU
 SG_ CF_Bms_CshActFromAcu : 55|1@1+ (1,0) [0|1] ""  CGW,LDC,MCU,TMU,VCU
 SG_ CF_Bms_HighTempStatus : 56|1@1+ (1,0) [0|1] "flag"  CGW,TMU
 SG_ CF_Bms_HvIntlockReq : 58|1@1+ (1,0) [0|1] ""  CGW,DATC,LDC,MCU,OBC,TMU,VCU
 SG_ CF_Bms_RlyWeld : 59|1@1+ (1,0) [0|1] ""  CGW,LDC,MCU,TMU,VCU
 SG_ CF_Bms_ForcedDischgReq : 60|1@1+ (1,0) [0|0] ""  MCU
 SG_ CF_Bms_LdcInh : 61|1@1+ (1,0) [0|1] ""  CGW,LDC,TMU
 SG_ CF_Bms_FulChgSts : 62|1@1+ (1,0) [0|1] ""  CGW,TMU
 SG_ CF_Bms_ChgSts : 63|1@1+ (1,0) [0|1] ""  AAF,CGW,DATC,LDC,TMU,VCU

BO_ 1023 BMS42: 8 BMS
 SG_ CR_Bms_Nev_GroupSel : 0|8@1+ (1,0) [0|0] ""  CGW,NEMS
 SG_ CR_Bms_Nev_StatrNo : 8|8@1+ (1,0) [0|0] ""  CGW,NEMS
 SG_ CR_Bms_Nev_Info1 : 16|8@1+ (0.02,0) [0|0] ""  CGW,NEMS
 SG_ CR_Bms_Nev_Info2 : 24|8@1+ (0.02,0) [0|0] ""  CGW,NEMS
 SG_ CR_Bms_Nev_Info3 : 32|8@1+ (0.02,0) [0|0] ""  CGW,NEMS
 SG_ CR_Bms_Nev_Info4 : 40|8@1+ (0.02,0) [0|0] ""  CGW,NEMS
 SG_ CR_Bms_Nev_Info5 : 48|8@1+ (0.02,0) [0|0] ""  CGW,NEMS
 SG_ CR_Bms_Nev_Info6 : 56|8@1+ (0.02,0) [0|0] ""  CGW,NEMS

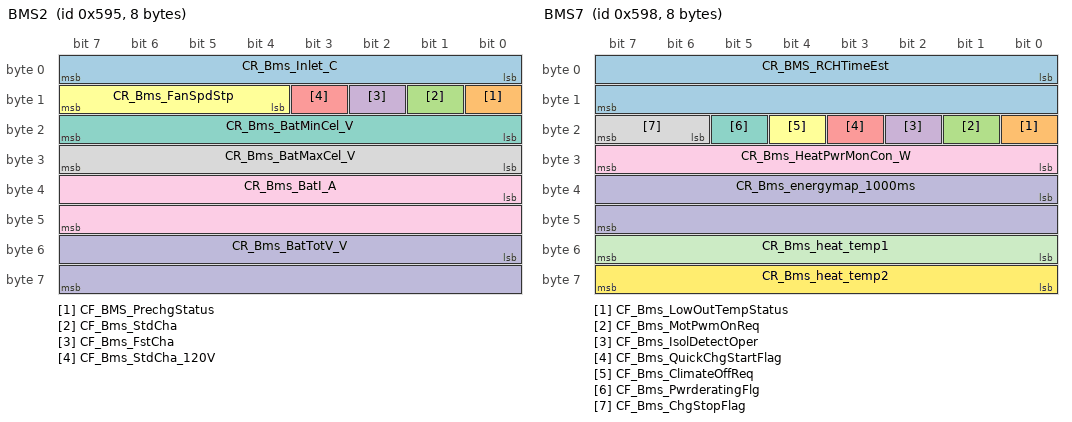
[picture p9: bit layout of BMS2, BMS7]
BO_ 1429 BMS2: 8 BMS
 SG_ CR_Bms_Inlet_C : 0|8@1- (1,0) [-128|127] "¡É"  CGW,TMU,VCU
 SG_ CF_BMS_PrechgStatus : 8|1@1+ (1,0) [0|1] ""  CGW,DATC,MCU,OBC,TMU,VCU
 SG_ CF_Bms_StdCha : 9|1@1+ (1,0) [0|1] ""  CDM,CGW,DATC,LDC,MCU,TMU,VCU
 SG_ CF_Bms_FstCha : 10|1@1+ (1,0) [0|1] ""  CDM,CGW,DATC,LDC,MCU,SMK,TMU,VCU
 SG_ CF_Bms_StdCha_120V : 11|1@1+ (1,0) [0|1] "flag"  CGW,TMU,VCU
 SG_ CR_Bms_FanSpdStp : 12|4@1+ (1,0) [0|9] "Step"  CGW,TMU,VCU
 SG_ CR_Bms_BatMinCel_V : 16|8@1+ (0.02,0) [0|5] "V"  CGW,TMU,VCU
 SG_ CR_Bms_BatMaxCel_V : 24|8@1+ (0.02,0) [0|5] "V"  CGW,TMU,VCU
 SG_ CR_Bms_BatI_A : 32|16@1- (0.1,0) [-500|500] "A"  CGW,TMU,VCU,vBDM
 SG_ CR_Bms_BatTotV_V : 48|16@1+ (0.1,0) [0|500] "V"  CGW,MCU,OBC,TMU,VCU

BO_ 1432 BMS7: 8 BMS
 SG_ CR_BMS_RCHTimeEst : 0|16@1+ (1,0) [0|65535] "min"  VCU
 SG_ CF_Bms_LowOutTempStatus : 16|1@1+ (1,0) [0|1] ""  CGW
 SG_ CF_Bms_MotPwmOnReq : 17|1@1+ (1,0) [0|1] "flag"  MCU
 SG_ CF_Bms_IsolDetectOper : 18|1@1+ (1,0) [0|1] "flag"  MCU,VCU
 SG_ CF_Bms_QuickChgStartFlag : 19|1@1+ (1,0) [0|1] ""  VCU
 SG_ CF_Bms_ClimateOffReq : 20|1@1+ (1,0) [0|1] ""  VCU
 SG_ CF_Bms_PwrderatingFlg : 21|1@1+ (1,0) [0|1] ""  VCU
 SG_ CF_Bms_ChgStopFlag : 22|2@1+ (1,0) [0|3] ""  CGW,OBC
 SG_ CR_Bms_HeatPwrMonCon_W : 24|8@1+ (10,0) [0|2550] "W"  CGW,TMU
 SG_ CR_Bms_energymap_1000ms : 32|16@1+ (2,0) [0|65535] "Wh"  CGW,TMU,VCU,vBDM
 SG_ CR_Bms_heat_temp1 : 48|8@1- (1,0) [-128|127] "¡É"  TMU,VCU
 SG_ CR_Bms_heat_temp2 : 56|8@1- (1,0) [-128|127] "¡É"  TMU,VCU

BO_ 1433 BMS9: 8 BMS
 SG_ cf_bms_chgrdy : 59|1@1+ (1,0) [0|1] "" Vector__XXX
 SG_ CF_Bms_EvReady : 0|1@1+ (1,0) [0|1] "flag"  CCM,OBC
 SG_ CF_Bms_CabinConditioning : 1|1@1+ (1,0) [0|1] "flag"  CCM
 SG_ CF_Bms_BatHeatStat : 2|1@1+ (1,0) [0|1] "flag"  CCM
 SG_ CF_Bms_NoError : 3|1@1+ (1,0) [0|1] "flag"  CCM
 SG_ CF_Bms_Fail_Temp : 4|1@1+ (1,0) [0|1] "flag"  CCM
 SG_ CF_Bms_FAILED_EVShiftPosition : 5|1@1+ (1,0) [0|1] "flag"  CCM
 SG_ CF_Bms_Fail_Conlock : 6|1@1+ (1,0) [0|1] "flag"  CCM
 SG_ CF_Bms_Fail_Evmalf : 7|1@1+ (1,0) [0|1] "flag"  CCM
 SG_ CF_Bms_Fail_CurrDiff : 8|1@1+ (1,0) [0|1] "flag"  CCM
 SG_ CF_Bms_Fail_VoltRange : 9|1@1+ (1,0) [0|1] "flag"  CCM
 SG_ CF_Bms_Fail_ChgSysIncom : 10|1@1+ (1,0) [0|1] "flag"  CCM
 SG_ CF_Bms_NoData : 11|1@1+ (1,0) [0|1] "flag"  CCM
 SG_ CF_Bms_ReadyToCharge : 12|1@1+ (1,0) [0|1] "flag"  CCM
 SG_ CF_Bms_BulkChgComplete : 13|1@1+ (1,0) [0|1] "flag"  CCM,OBC
 SG_ CF_Bms_ChgComplete : 14|1@1+ (1,0) [0|1] "flag"  CCM,OBC
 SG_ CF_Bms_ChgFinished : 15|1@1+ (1,0) [0|1] "flag"  CCM,CGW,OBC,vBDM
 SG_ CR_BMS_DisplaySOC : 16|8@1+ (0.5,0) [0|100] "%"  CCM
 SG_ CR_Bms_EVmaxCurrent : 24|16@1+ (0.1,0) [0|6553.5] "A"  CCM
 SG_ CR_Bms_EVmaxVolt : 40|16@1+ (0.1,0) [0|6553.5] "V"  CCM
 SG_ CF_Bms_PreparationStatusForPLC : 56|1@1+ (1,0) [0|1] "flag"  CCM,OBC
 SG_ CF_Bms_ReadyForCurDem : 57|1@1+ (1,0) [0|1] "flag"  CCM,OBC
 SG_ CF_Bms_RlyWeldDetectionReq : 58|1@1+ (1,0) [0|1] "flag"  CCM
 SG_ CF_Bms_ChgInfoCode : 60|4@1+ (1,0) [0|15] ""  Dummy,VCMS

BO_ 1438 BMS11: 8 BMS
 SG_ CR_Bms_FullSOCRemainedTime : 0|16@1+ (1,0) [0|65535] "Sec"  CCM,CGW,vBDM
 SG_ CF_Bms_BulkRemTime_ChgOnly : 16|16@1+ (1,0) [0|65535] "Sec"  CCM,CGW,vBDM
 SG_ CR_Bms_BatTotV_V : 32|16@1+ (0.1,0) [0|500] "V"  CCM
 SG_ CR_Bms_EVmaxPower : 48|16@1+ (10,0) [0|655350] "W"  CCM

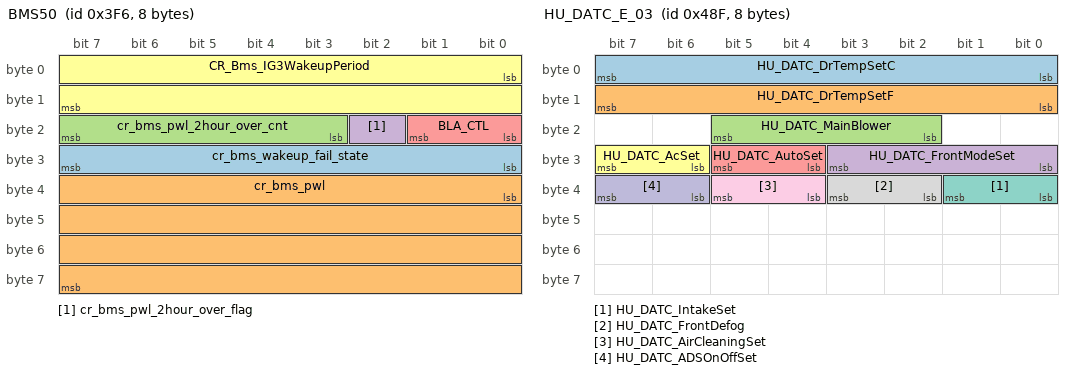
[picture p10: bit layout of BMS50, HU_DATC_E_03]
BO_ 1014 BMS50: 8 BMS
 SG_ cr_bms_wakeup_fail_state : 24|8@1+ (1,0) [0|255] "" Vector__XXX
 SG_ cr_bms_pwl : 32|32@1+ (1,0) [0|0] "" Vector__XXX
 SG_ cr_bms_pwl_2hour_over_cnt : 19|5@1+ (1,0) [0|31] "" Vector__XXX
 SG_ cr_bms_pwl_2hour_over_flag : 18|1@1+ (1,0) [0|0] "" Vector__XXX
 SG_ BLA_CTL : 16|2@1+ (1,0) [0|3] "" Vector__XXX
 SG_ CR_Bms_IG3WakeupPeriod : 0|16@1+ (1,0) [0|24] "Hr"  CGW,LDC,VCU

BO_ 1436 BMS10: 8 BMS
 SG_ CR_Bms_FullSOC : 0|8@1+ (0.5,0) [0|100] "%"  CCM
 SG_ CR_Bms_BulkSOC : 8|8@1+ (0.5,0) [0|100] "%"  CCM
 SG_ CR_Bms_EVTargetVolt : 16|16@1+ (0.1,0) [0|6553.5] "V"  CCM,OBC
 SG_ CR_Bms_EVTargetCurrent : 32|16@1+ (0.1,0) [0|6553.5] "A"  CCM,CGW,OBC,vBDM
 SG_ CR_Bms_EvEnergyCapa : 48|16@1+ (1,0) [0|65530] "Wh"  CCM,CGW

BO_ 1167 HU_DATC_E_03: 8 CGW
 SG_ HU_DATC_DrTempSetC : 0|8@1+ (0.5,14) [15|32] "¡É"  DATC
 SG_ HU_DATC_DrTempSetF : 8|8@1+ (1,56) [58|90] "¢µ"  DATC
 SG_ HU_DATC_MainBlower : 18|4@1+ (1,0) [0|0] ""  DATC
 SG_ HU_DATC_FrontModeSet : 24|4@1+ (1,0) [0|0] ""  DATC
 SG_ HU_DATC_AutoSet : 28|2@1+ (1,0) [0|0] ""  DATC
 SG_ HU_DATC_AcSet : 30|2@1+ (1,0) [0|0] ""  DATC
 SG_ HU_DATC_IntakeSet : 32|2@1+ (1,0) [0|0] ""  DATC
 SG_ HU_DATC_FrontDefog : 34|2@1+ (1,0) [0|0] ""  DATC
 SG_ HU_DATC_AirCleaningSet : 36|2@1+ (1,0) [0|0] ""  DATC
 SG_ HU_DATC_ADSOnOffSet : 38|2@1+ (1,0) [0|3] ""  DATC

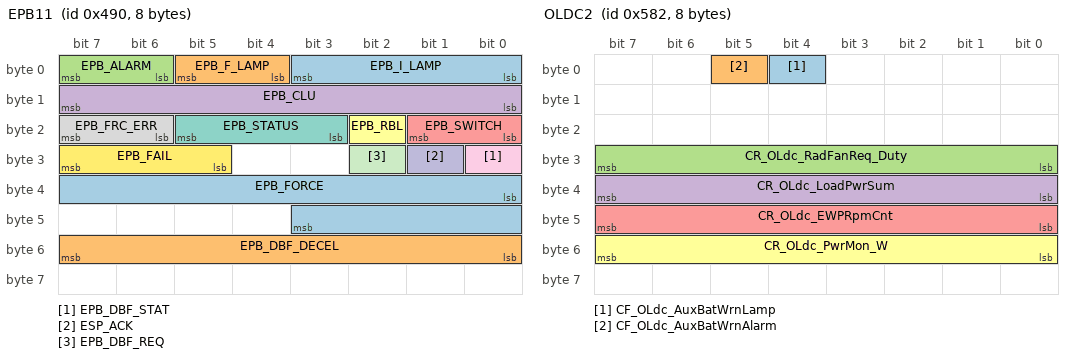
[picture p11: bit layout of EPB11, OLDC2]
BO_ 1168 EPB11: 8 CGW
 SG_ EPB_I_LAMP : 0|4@1+ (1,0) [0|15] ""  Dummy,H_U,TMU
 SG_ EPB_F_LAMP : 4|2@1+ (1,0) [0|3] ""  Dummy,H_U,TMU,vBDM
 SG_ EPB_ALARM : 6|2@1+ (1,0) [0|3] ""  Dummy
 SG_ EPB_CLU : 8|8@1+ (1,0) [0|255] ""  Dummy
 SG_ EPB_SWITCH : 16|2@1+ (1,0) [0|3] ""  Dummy
 SG_ EPB_RBL : 18|1@1+ (1,0) [0|1] ""  Dummy
 SG_ EPB_STATUS : 19|3@1+ (1,0) [0|7] ""  VCU
 SG_ EPB_FRC_ERR : 22|2@1+ (1,0) [0|3] ""  Dummy
 SG_ EPB_DBF_STAT : 24|1@1+ (1,0) [0|1] ""  Dummy
 SG_ ESP_ACK : 25|1@1+ (1,0) [0|1] ""  Dummy
 SG_ EPB_DBF_REQ : 26|1@1+ (1,0) [0|1] ""  Dummy
 SG_ EPB_FAIL : 29|3@1+ (1,0) [0|7] ""  Dummy
 SG_ EPB_FORCE : 32|12@1+ (1,-1000) [-1000|3000] ""  Dummy
 SG_ EPB_DBF_DECEL : 48|8@1+ (0.01,0) [0|2.54] "g"  Dummy

BO_ 1410 OLDC2: 8 OLDC
 SG_ CF_OLdc_AuxBatWrnLamp : 4|1@1+ (1,0) [0|1] ""  CGW,LDC,TMU
 SG_ CF_OLdc_AuxBatWrnAlarm : 5|1@1+ (1,0) [0|1] ""  CGW,LDC,TMU
 SG_ CR_OLdc_RadFanReq_Duty : 24|8@1+ (1,0) [0|100] "%"  MCU,TMU,VCU
 SG_ CR_OLdc_LoadPwrSum : 32|8@1+ (10,0) [0|2540] "Wh"  CGW,LDC
 SG_ CR_OLdc_EWPRpmCnt : 40|8@1+ (20,0) [0|5000] "rpm"  LDC,MCU,TMU
 SG_ CR_OLdc_PwrMon_W : 48|8@1+ (10,0) [0|2550] "W"  CGW,LDC,TMU,VCU

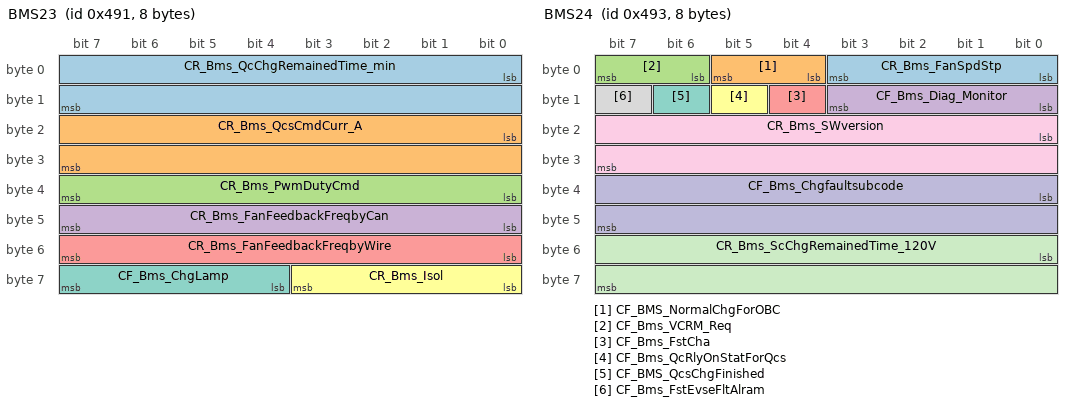
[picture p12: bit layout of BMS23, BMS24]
BO_ 1169 BMS23: 8 BMS
 SG_ CR_Bms_QcChgRemainedTime_min : 0|16@1+ (1,0) [0|65535] "min"  CGW,H_U,TMU,vBDM
 SG_ CR_Bms_QcsCmdCurr_A : 16|16@1+ (0.1,0) [0|6553.5] "A"  TMU
 SG_ CR_Bms_PwmDutyCmd : 32|8@1+ (1,0) [0|100] "%"  TMU
 SG_ CR_Bms_FanFeedbackFreqbyCan : 40|8@1+ (1,0) [0|255] ""  TMU
 SG_ CR_Bms_FanFeedbackFreqbyWire : 48|8@1+ (1,0) [0|255] ""  TMU
 SG_ CR_Bms_Isol : 56|4@1+ (100,0) [0|1500] "k¥Ø"  TMU
 SG_ CF_Bms_ChgLamp : 60|4@1+ (1,0) [0|7] ""  TMU

BO_ 1409 OBC2: 8 OBC
 SG_ CR_OBC_Mains_Cur : 0|16@1+ (0.01,0) [0|150] "A"  BMS,TMU
 SG_ CR_OBC_Mains_Vol : 16|16@1+ (0.1,0) [0|500] "V"  BMS,CGW,TMU,vBDM
 SG_ CR_OBC_Out_Vol : 32|16@1+ (0.1,0) [0|1000] "V"  BMS,TMU
 SG_ CR_OBC_Out_Cur : 48|16@1+ (0.01,0) [0|150] "A"  BMS,TMU

BO_ 1171 BMS24: 8 BMS
 SG_ CR_Bms_FanSpdStp : 0|4@1+ (1,0) [0|9] "Step"  DATC,TMU
 SG_ CF_BMS_NormalChgForOBC : 4|2@1+ (1,0) [0|3] "flag"  CGW,H_U,TMU
 SG_ CF_Bms_VCRM_Req : 6|2@1+ (1,0) [0|3] ""  CGW,H_U,TMU,vBDM
 SG_ CF_Bms_Diag_Monitor : 8|4@1+ (1,0) [1|15] ""  TMU
 SG_ CF_Bms_FstCha : 12|1@1+ (1,0) [0|1] ""  CGW,H_U,TMU
 SG_ CF_Bms_QcRlyOnStatForQcs : 13|1@1+ (1,0) [0|1] ""  TMU
 SG_ CF_BMS_QcsChgFinished : 14|1@1+ (1,0) [0|1] ""  TMU
 SG_ CF_Bms_FstEvseFltAlram : 15|1@1+ (1,0) [0|1] "flag"  CGW,TMU
 SG_ CR_Bms_SWversion : 16|16@1+ (1,0) [0|7999] ""  TMU,VCU
 SG_ CF_Bms_Chgfaultsubcode : 32|16@1+ (1,0) [1|65535] ""  TMU
 SG_ CR_Bms_ScChgRemainedTime_120V : 48|16@1+ (1,0) [0|65535] "minute"  CGW,H_U,TMU

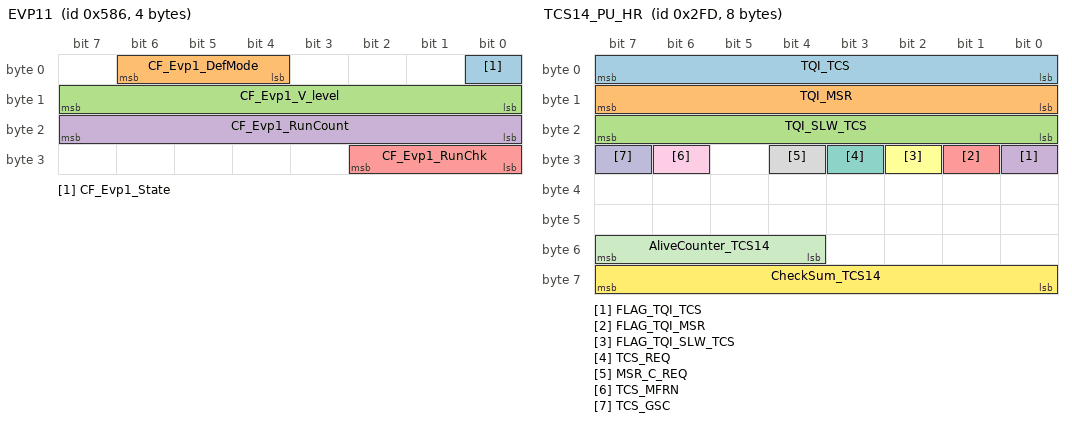
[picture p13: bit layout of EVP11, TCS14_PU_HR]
BO_ 1414 EVP11: 4 EVP1
 SG_ CF_Evp1_State : 0|1@1+ (1,0) [0|1] ""  CGW,EVP2,iBAU
 SG_ CF_Evp1_DefMode : 4|3@1+ (1,0) [0|7] ""  EVP2
 SG_ CF_Evp1_V_level : 8|8@1+ (10,0) [0|760] "mmHg"  EVP2
 SG_ CF_Evp1_RunCount : 16|8@1+ (100,0) [0|255] "ms"  EVP2
 SG_ CF_Evp1_RunChk : 24|3@1+ (1,0) [0|7] ""  EVP2,iBAU

BO_ 765 TCS14_PU_HR: 8 iBAU
 SG_ TQI_TCS : 0|8@1+ (0.390625,0) [0|99.609375] "%"  VCU
 SG_ TQI_MSR : 8|8@1+ (0.390625,0) [0|99.609375] "%"  VCU
 SG_ TQI_SLW_TCS : 16|8@1+ (0.390625,0) [0|99.609375] "%"  VCU
 SG_ FLAG_TQI_TCS : 24|1@1+ (1,0) [0|1] ""  VCU
 SG_ FLAG_TQI_MSR : 25|1@1+ (1,0) [0|1] ""  VCU
 SG_ FLAG_TQI_SLW_TCS : 26|1@1+ (1,0) [0|1] ""  VCU
 SG_ TCS_REQ : 27|1@1+ (1,0) [0|1] ""  VCU
 SG_ MSR_C_REQ : 28|1@1+ (1,0) [0|1] ""  VCU
 SG_ TCS_MFRN : 30|1@1+ (1,0) [0|1] ""  VCU
 SG_ TCS_GSC : 31|1@1+ (1,0) [0|1] ""  VCU
 SG_ AliveCounter_TCS14 : 52|4@1+ (1,0) [0|14] ""  VCU
 SG_ CheckSum_TCS14 : 56|8@1+ (1,0) [0|255] ""  VCU

BO_ 1412 AAF11: 8 AAF
 SG_ CF_Aaf_ActFlapStatus : 0|2@1+ (1,0) [0|3] ""  AAF_Tester,EMS,TMU
 SG_ CF_Aaf_ModeStatus : 2|3@1+ (1,0) [0|7] ""  AAF_Tester,TMU
 SG_ CF_Aaf_WrnLamp : 5|1@1+ (1,0) [0|1] ""  CGW,H_U,TMU,vBDM
 SG_ CF_Aaf_ErrStatus : 6|10@1+ (1,0) [0|1023] ""  AAF_Tester,EMS,TMU
 SG_ CF_Aaf_OpenRqSysAct : 16|8@1+ (1,0) [0|255] ""  AAF_Tester,TMU
 SG_ CF_Aaf_PStatus : 24|8@1+ (1,0) [0|100] "%"  AAF_Tester,TMU
 SG_ CF_Aaf_PStatusSub : 32|8@1+ (1,0) [0|100] "%"  AAF_Tester,TMU
 SG_ CF_Aaf_MilOnReq : 42|1@1+ (1,0) [0|1] ""  EMS,TMU
 SG_ CF_Aaf_ActFlapTarget : 43|1@1+ (1,0) [0|1] ""  AAF_2,AAF_3,AAF_Tester,TMU
 SG_ CF_Aaf_ActFlapTarget_2 : 48|2@1+ (1,0) [0|1] ""  AAF_2,AAF_3,AAF_Tester,TMU

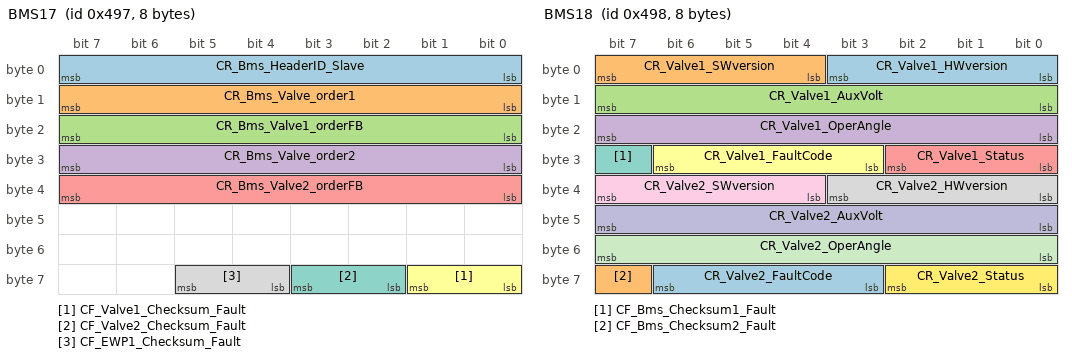
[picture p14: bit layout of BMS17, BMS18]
BO_ 1175 BMS17: 8 BMS
 SG_ CR_Bms_HeaderID_Slave : 0|8@1+ (1,0) [0|0] ""  Dummy
 SG_ CR_Bms_Valve_order1 : 8|8@1+ (1,0) [0|200] ""  CGW,Dummy,vBDM
 SG_ CR_Bms_Valve1_orderFB : 16|8@1+ (1,0) [0|200] ""  Dummy
 SG_ CR_Bms_Valve_order2 : 24|8@1+ (1,0) [0|200] ""  Dummy
 SG_ CR_Bms_Valve2_orderFB : 32|8@1+ (1,0) [0|200] ""  Dummy
 SG_ CF_Valve1_Checksum_Fault : 56|2@1+ (1,0) [0|0] ""  Dummy
 SG_ CF_Valve2_Checksum_Fault : 58|2@1+ (1,0) [0|0] ""  Dummy
 SG_ CF_EWP1_Checksum_Fault : 60|2@1+ (1,0) [0|0] ""  Dummy

BO_ 1176 BMS18: 8 BMS
 SG_ CR_Valve1_HWversion : 0|4@1+ (1,0) [0|0] ""  Dummy
 SG_ CR_Valve1_SWversion : 4|4@1+ (1,0) [0|0] ""  Dummy
 SG_ CR_Valve1_AuxVolt : 8|8@1+ (0.1,0) [0|25.3] "V"  Dummy
 SG_ CR_Valve1_OperAngle : 16|8@1+ (1,0) [0|200] "¢ª"  Dummy
 SG_ CR_Valve1_Status : 24|3@1+ (1,0) [0|0] ""  CGW,DATC,Dummy,vBDM
 SG_ CR_Valve1_FaultCode : 27|4@1+ (1,0) [0|0] ""  Dummy
 SG_ CF_Bms_Checksum1_Fault : 31|1@1+ (1,0) [0|0] ""  Dummy
 SG_ CR_Valve2_HWversion : 32|4@1+ (1,0) [0|0] ""  Dummy
 SG_ CR_Valve2_SWversion : 36|4@1+ (1,0) [0|0] ""  Dummy
 SG_ CR_Valve2_AuxVolt : 40|8@1+ (0.1,0) [0|25.3] "V"  Dummy
 SG_ CR_Valve2_OperAngle : 48|8@1+ (1,0) [0|200] "¢ª"  Dummy
 SG_ CR_Valve2_Status : 56|3@1+ (1,0) [0|0] ""  DATC,Dummy
 SG_ CR_Valve2_FaultCode : 59|4@1+ (1,0) [0|0] ""  Dummy
 SG_ CF_Bms_Checksum2_Fault : 63|1@1+ (1,0) [0|0] ""  Dummy

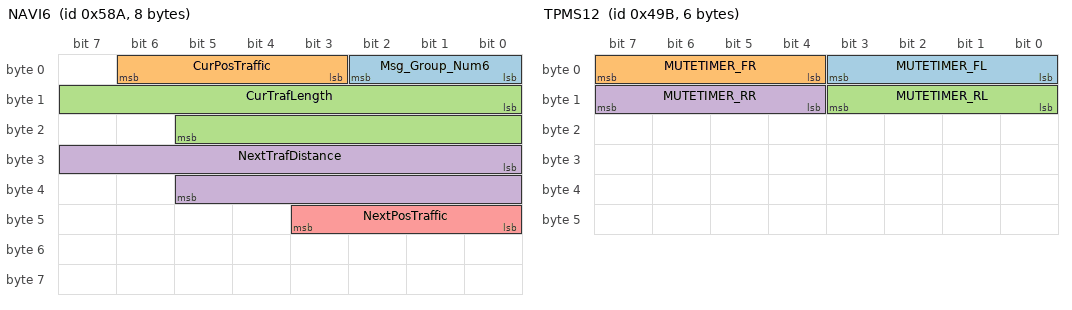
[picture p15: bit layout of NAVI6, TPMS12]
BO_ 1418 NAVI6: 8 CGW
 SG_ Msg_Group_Num6 : 0|3@1+ (1,0) [0|7] ""  VCU
 SG_ CurPosTraffic : 3|4@1+ (1,0) [0|3] ""  VCU
 SG_ CurTrafLength : 8|14@1+ (1,0) [0|5000] "m"  VCU
 SG_ NextTrafDistance : 24|14@1+ (1,0) [0|5000] "m"  VCU
 SG_ NextPosTraffic : 40|4@1+ (1,0) [0|3] ""  VCU

BO_ 1178 CGW9: 8 CGW
 SG_ Navi_AirConditionType : 50|6@1+ (1,0) [0|0] ""  DATC
 SG_ Navi_AirConditionWarning : 56|2@1+ (1,0) [0|0] ""  DATC

BO_ 1179 TPMS12: 6 IBU
 SG_ MUTETIMER_FL : 0|4@1+ (1,0) [0|0] "Min"  CGW
 SG_ MUTETIMER_FR : 4|4@1+ (1,0) [0|0] ""  CGW
 SG_ MUTETIMER_RL : 8|4@1+ (1,0) [0|0] ""  CGW
 SG_ MUTETIMER_RR : 12|4@1+ (1,0) [0|0] ""  CGW

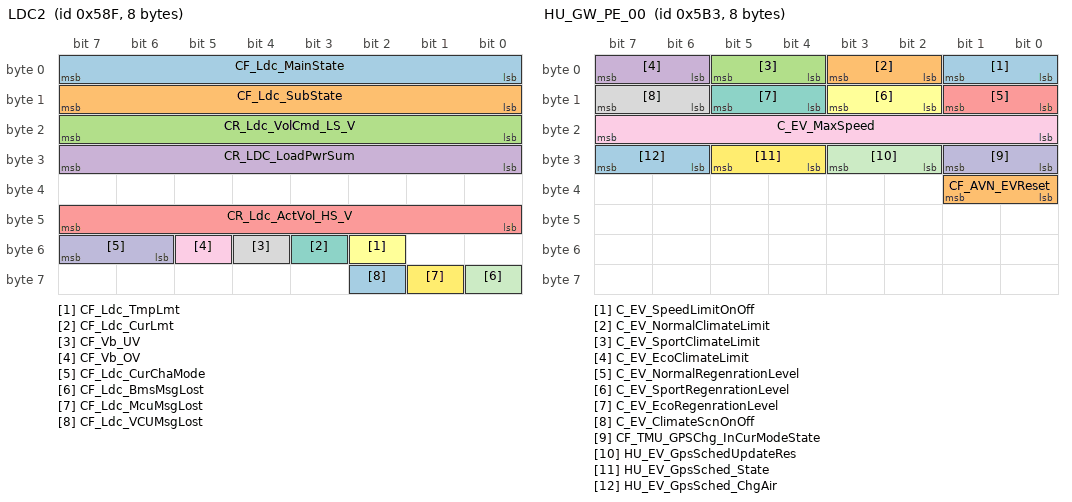
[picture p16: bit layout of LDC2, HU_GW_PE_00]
BO_ 1423 LDC2: 8 LDC
 SG_ CF_Ldc_MainState : 0|8@1+ (1,0) [0|255] ""  MCU
 SG_ CF_Ldc_SubState : 8|8@1+ (1,0) [0|255] ""  MCU
 SG_ CR_Ldc_VolCmd_LS_V : 16|8@1+ (0.1,0) [0|25.5] "V"  MCU
 SG_ CR_LDC_LoadPwrSum : 24|8@1+ (10,0) [0|2540] "Wh"  CGW
 SG_ CR_Ldc_ActVol_HS_V : 40|8@1+ (2,0) [0|510] "V"  MCU
 SG_ CF_Ldc_TmpLmt : 50|1@1+ (1,0) [0|1] ""  MCU
 SG_ CF_Ldc_CurLmt : 51|1@1+ (1,0) [0|1] ""  MCU
 SG_ CF_Vb_UV : 52|1@1+ (1,0) [0|1] ""  MCU
 SG_ CF_Vb_OV : 53|1@1+ (1,0) [0|1] ""  MCU
 SG_ CF_Ldc_CurChaMode : 54|2@1+ (1,0) [0|3] ""  MCU
 SG_ CF_Ldc_BmsMsgLost : 56|1@1+ (1,0) [0|1] ""  MCU
 SG_ CF_Ldc_McuMsgLost : 57|1@1+ (1,0) [0|1] ""  MCU
 SG_ CF_Ldc_VCUMsgLost : 58|1@1+ (1,0) [0|1] ""  MCU

BO_ 1422 OBC3: 8 OBC
 SG_ CF_OBC_InfoCode : 0|8@1+ (1,0) [0|255] ""  BMS,CGW,TMU,vBDM
 SG_ CF_OBC_SeqState : 8|8@1+ (1,0) [0|255] ""  BMS,TMU
 SG_ CR_OBC_PwrEst : 16|8@1+ (0.1,0) [0|25] "kW"  BMS
 SG_ CF_OBC_Asw_Num : 24|4@1+ (1,0) [0|15] ""  LDC
 SG_ CF_OBC_Asw_DevStep : 28|3@1+ (1,0) [0|7] ""  LDC
 SG_ CF_OBC_Asw_Mode : 31|1@1+ (1,0) [0|1] ""  LDC
 SG_ CF_OBC_InletMode : 32|3@1+ (1,0) [0|5] ""  LDC
 SG_ CF_OBC_InletPlugMode : 35|2@1+ (1,0) [0|2] ""  LDC
 SG_ CF_OBC_InletSwMode : 37|1@1+ (1,0) [0|1] ""  LDC
 SG_ CF_OBC_GPSChg_InCurMode : 38|2@1+ (1,0) [0|0] ""  CGW
 SG_ CF_OBC_EVSE_InCurMode : 40|2@1+ (1,0) [0|0] ""  CGW
 SG_ CF_OBC_ICCB_InCurMode : 42|2@1+ (1,0) [0|0] ""  CGW
 SG_ CF_OBC_Plug_Type : 44|2@1+ (1,0) [0|3] ""  CGW,LDC
 SG_ CR_OBC_CP_DutyFloat : 46|10@1+ (0.1,0) [0|102.3] ""  BMS,LDC
 SG_ CF_OBC_InletUnlock_Inh : 56|1@1+ (1,0) [0|1] ""  CGW,TMU
 SG_ CF_OBC_InletLock_Req : 57|2@1+ (1,0) [0|3] ""  CGW,TMU
 SG_ CF_OBC_ChgLampOffReqForBMS : 59|1@1+ (1,0) [0|1] ""  BMS
 SG_ CF_OBC_PLC_CP_FAULT : 60|1@1+ (1,0) [0|1] ""  BMS
 SG_ CF_OBC_IG3RlyMd : 61|3@1+ (1,0) [0|7] ""  CDM,TMU

BO_ 1182 CDM1: 8 CDM
 SG_ CF_CDM_ChgDrSwFrt : 0|2@1+ (1,0) [0|3] ""  OBC,VCU
 SG_ CF_CDM_ImmeChgSw : 2|2@1+ (1,0) [0|3] ""  OBC,VCU

BO_ 1459 HU_GW_PE_00: 8 CGW
 SG_ C_EV_SpeedLimitOnOff : 0|2@1+ (1,0) [0|3] ""  VCU
 SG_ C_EV_NormalClimateLimit : 2|2@1+ (1,0) [0|3] ""  DATC,VCU
 SG_ C_EV_SportClimateLimit : 4|2@1+ (1,0) [0|3] ""  DATC,VCU
 SG_ C_EV_EcoClimateLimit : 6|2@1+ (1,0) [0|3] ""  DATC,VCU
 SG_ C_EV_NormalRegenrationLevel : 8|2@1+ (1,0) [0|3] ""  VCU
 SG_ C_EV_SportRegenrationLevel : 10|2@1+ (1,0) [0|3] ""  VCU
 SG_ C_EV_EcoRegenrationLevel : 12|2@1+ (1,0) [0|3] ""  VCU
 SG_ C_EV_ClimateScnOnOff : 14|2@1+ (1,0) [0|3] ""  VCU
 SG_ C_EV_MaxSpeed : 16|8@1+ (1,0) [0|255] "km/h"  VCU
 SG_ CF_TMU_GPSChg_InCurModeState : 24|2@1+ (1,0) [0|0] ""  OBC
 SG_ HU_EV_GpsSchedUpdateRes : 26|2@1+ (1,0) [0|3] ""  BMS,OBC,VCU
 SG_ HU_EV_GpsSched_State : 28|2@1+ (1,0) [0|3] ""  BMS,OBC,VCU
 SG_ HU_EV_GpsSched_ChgAir : 30|2@1+ (1,0) [0|3] ""  VCU
 SG_ CF_AVN_EVReset : 32|2@1+ (1,0) [0|0] ""  VCU

BO_ 1460 HU_GW_PE_01: 8 CGW
 SG_ HU_TempUnit : 34|2@1+ (1,0) [0|0] ""  DATC
 SG_ CF_AVN_ProfileIDRValue : 44|4@1+ (1,0) [0|0] ""  DATC

BO_ 1190 CLU19: 8 CGW
 SG_ CF_AVN_CluUSMReset : 3|1@1+ (1,0) [0|1] ""  OBC

BO_ 1462 CGW11: 8 CGW
 SG_ CF_Gway_RrLftSeatBeltSw : 4|2@1+ (1,0) [0|3] ""  eCALL
 SG_ CF_Gway_RrCtrSeatBeltSw : 6|2@1+ (1,0) [0|3] ""  eCALL
 SG_ CF_Gway_RrRtSeatBeltSw : 8|2@1+ (1,0) [0|3] ""  eCALL

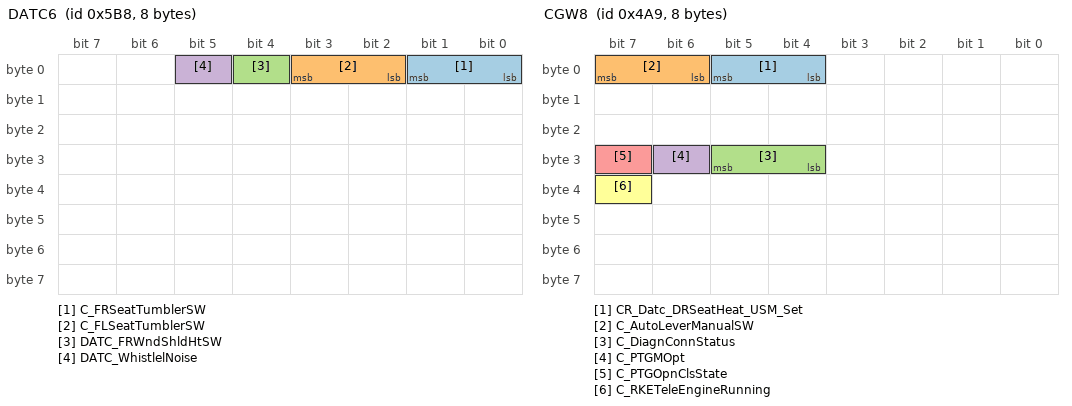
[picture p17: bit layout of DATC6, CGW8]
BO_ 1464 DATC6: 8 DATC
 SG_ C_FRSeatTumblerSW : 0|2@1+ (1,0) [0|3] ""  CGW,IBU
 SG_ C_FLSeatTumblerSW : 2|2@1+ (1,0) [0|3] ""  CGW,IBU
 SG_ DATC_FRWndShldHtSW : 4|1@1+ (1,0) [0|0] ""  CGW
 SG_ DATC_WhistlelNoise : 5|1@1+ (1,0) [0|0] ""  CGW

BO_ 1193 CGW8: 8 CGW
 SG_ CR_Datc_DRSeatHeat_USM_Set : 4|2@1+ (1,0) [0|3] ""  DATC
 SG_ C_AutoLeverManualSW : 6|2@1+ (1,0) [0|1] ""  TCU
 SG_ C_DiagnConnStatus : 28|2@1+ (1,0) [0|3] ""  Dummy,VCU
 SG_ C_PTGMOpt : 30|1@1+ (1,0) [0|0] ""  DATC
 SG_ C_PTGOpnClsState : 31|1@1+ (1,0) [0|0] ""  DATC
 SG_ C_RKETeleEngineRunning : 39|1@1+ (1,0) [0|1] ""  DATC

BO_ 1466 HU_USM_E_09: 8 CGW
 SG_ CF_AVN_AuxBatChargeNValueSet : 10|2@1+ (1,0) [0|3] ""  VCU
 SG_ CF_AVN_SmartRegenNValueSet : 12|2@1+ (1,0) [0|3] ""  VCU
 SG_ CF_AVN_RestModeNValueSet : 44|2@1+ (1,0) [0|3] ""  VCU

BO_ 1467 DATC11_E: 8 DATC
 SG_ DATC_Beep1Mode : 0|2@1+ (1,0) [0|3] ""  CGW,IBU

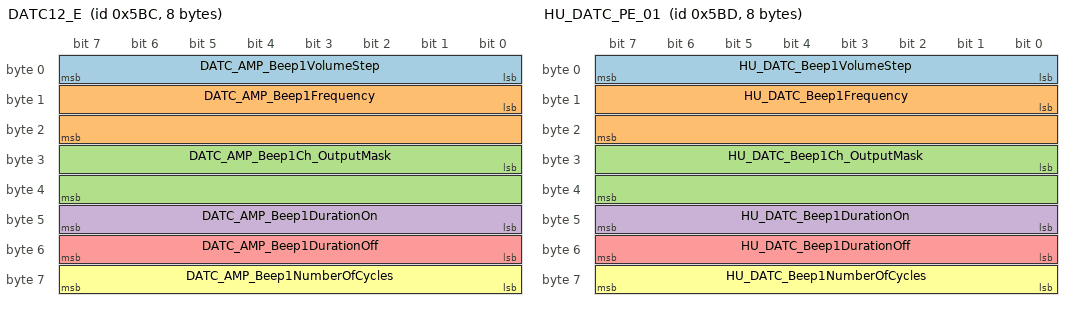
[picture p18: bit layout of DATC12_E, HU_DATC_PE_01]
BO_ 1468 DATC12_E: 8 DATC
 SG_ DATC_AMP_Beep1VolumeStep : 0|8@1+ (1,0) [0|0] ""  CGW,IBU
 SG_ DATC_AMP_Beep1Frequency : 8|16@1+ (1,0) [0|0] ""  CGW,IBU
 SG_ DATC_AMP_Beep1Ch_OutputMask : 24|16@1+ (1,0) [0|0] ""  CGW,IBU
 SG_ DATC_AMP_Beep1DurationOn : 40|8@1+ (1,0) [0|0] ""  CGW,IBU
 SG_ DATC_AMP_Beep1DurationOff : 48|8@1+ (1,0) [0|0] ""  CGW,IBU
 SG_ DATC_AMP_Beep1NumberOfCycles : 56|8@1+ (1,0) [0|0] ""  CGW,IBU

BO_ 1469 HU_DATC_PE_01: 8 CGW
 SG_ HU_DATC_Beep1VolumeStep : 0|8@1+ (1,0) [0|0] ""  DATC
 SG_ HU_DATC_Beep1Frequency : 8|16@1+ (1,0) [0|0] ""  DATC
 SG_ HU_DATC_Beep1Ch_OutputMask : 24|16@1+ (1,0) [0|0] ""  DATC
 SG_ HU_DATC_Beep1DurationOn : 40|8@1+ (1,0) [0|0] ""  DATC
 SG_ HU_DATC_Beep1DurationOff : 48|8@1+ (1,0) [0|0] ""  DATC
 SG_ HU_DATC_Beep1NumberOfCycles : 56|8@1+ (1,0) [0|0] ""  DATC

BO_ 1202 HU_USM_E_01: 8 CGW
 SG_ CF_AVN_FCANValueSet : 0|3@1+ (1,0) [0|7] ""  Dummy
 SG_ CF_AVN_PasSpkrLvNValueSet : 5|3@1+ (1,0) [0|7] ""  Dummy
 SG_ CF_AVN_SCCDrvModeNValueSet : 8|3@1+ (1,0) [0|7] ""  Dummy
 SG_ CF_AVN_DAWModeNValueSet : 11|3@1+ (1,0) [0|7] ""  Dummy
 SG_ CF_AVN_HDA_LFANValueSet : 14|2@1+ (1,0) [0|3] ""  Dummy
 SG_ CF_AVN_BCWNValueSet : 16|2@1+ (1,0) [0|3] ""  Dummy
 SG_ CF_AVN_SEANValueSet : 18|2@1+ (1,0) [0|3] ""  Dummy
 SG_ CF_AVN_NSCCCamNValueSet : 20|2@1+ (1,0) [0|3] ""  Dummy
 SG_ CF_AVN_BCANValueSet : 24|3@1+ (1,0) [0|7] ""  Dummy
 SG_ CF_AVN_ISLWNValueSet : 27|2@1+ (1,0) [0|3] ""  Dummy
 SG_ CF_AVN_WarningTimingNValueSet : 29|3@1+ (1,0) [0|7] ""  Dummy
 SG_ CF_AVN_NCC_USM_set : 32|2@1+ (1,0) [0|3] ""  Dummy
 SG_ CF_AVN_TirePressUnitNValueSet : 34|3@1+ (1,0) [0|7] ""  IBU
 SG_ CF_AVN_RCCANValueSet : 37|3@1+ (1,0) [0|7] ""  Dummy
 SG_ CF_AVN_NSCCCrvNValueSet : 42|2@1+ (1,0) [0|3] ""  Dummy
 SG_ CF_AVN_BCWSndWanNValueSet : 44|2@1+ (1,0) [0|3] ""  Dummy
 SG_ CF_AVN_RCCWNValueSet : 46|2@1+ (1,0) [0|3] ""  Dummy
 SG_ CF_AVN_LkaModeNValueSet : 49|3@1+ (1,0) [0|7] ""  Dummy

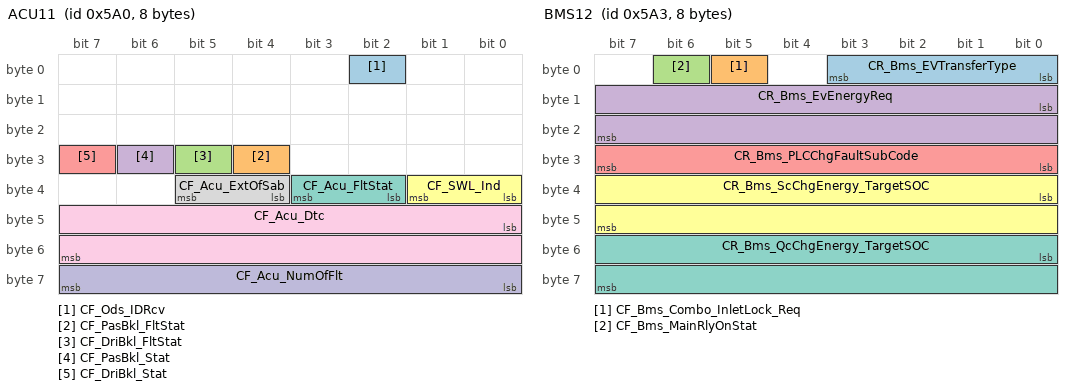
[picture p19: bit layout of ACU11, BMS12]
BO_ 1440 ACU11: 8 ACU
 SG_ CF_Ods_IDRcv : 2|1@1+ (1,0) [0|1] ""  BMS,ODS
 SG_ CF_PasBkl_FltStat : 28|1@1+ (1,0) [0|1] ""  CGW,ODS,PSB
 SG_ CF_DriBkl_FltStat : 29|1@1+ (1,0) [0|1] ""  CGW,ODS,PSB
 SG_ CF_PasBkl_Stat : 30|1@1+ (1,0) [0|1] ""  BMS,CGW,H_U,ODS,TMU,VCU
 SG_ CF_DriBkl_Stat : 31|1@1+ (1,0) [0|1] ""  CGW,H_U,IBOX,ODS,PSB,vDCM
 SG_ CF_SWL_Ind : 32|2@1+ (1,0) [0|3] ""  BMS,CGW,H_U,TMU,eCall,iBAU,vBDM
 SG_ CF_Acu_FltStat : 34|2@1+ (1,0) [0|3] ""  BMS,CGW,H_U,TMU,eCall
 SG_ CF_Acu_ExtOfSab : 36|2@1+ (1,0) [0|3] ""  CGW
 SG_ CF_Acu_Dtc : 40|16@1+ (1,0) [0|65535] ""  BMS,CGW,H_U,TMU,eCall,iBAU
 SG_ CF_Acu_NumOfFlt : 56|8@1+ (1,0) [0|255] ""  BMS,CGW,H_U,TMU,eCall,iBAU

BO_ 1443 BMS12: 8 BMS
 SG_ CR_Bms_EVTransferType : 0|4@1+ (1,0) [0|15] ""  CCM,CGW,vBDM
 SG_ CF_Bms_Combo_InletLock_Req : 5|1@1+ (1,0) [0|1] "flag"  OBC
 SG_ CF_Bms_MainRlyOnStat : 6|1@1+ (1,0) [0|1] ""  CCM
 SG_ CR_Bms_EvEnergyReq : 8|16@1+ (1,0) [0|65535] "Wh"  CCM
 SG_ CR_Bms_PLCChgFaultSubCode : 24|8@1+ (1,0) [1|255] ""  CCM,OBC
 SG_ CR_Bms_ScChgEnergy_TargetSOC : 32|16@1+ (2,0) [0|65535] "Wh"  VCU
 SG_ CR_Bms_QcChgEnergy_TargetSOC : 48|16@1+ (2,0) [0|65535] "Wh"  VCU

BO_ 1205 HU_USM_E_04: 8 CGW
 SG_ CF_AVN_CluUSMReset : 56|2@1+ (1,0) [0|0] ""  DATC,IBU,VCU
 SG_ CF_AVN_UnitReset : 62|2@1+ (1,0) [0|0] ""  DATC,IBU

BO_TX_BU_ 1427 : IBU,TPMS;
CM_ BO_ 1250 "[P] Periodic";
CM_ SG_ 1250 CR_Bms_ScChgRemTime_ICCB_Dom "-";
CM_ SG_ 1250 CR_Bms_RealScChgRemTime "-";
CM_ BO_ 1532 "[P] Periodic";
CM_ SG_ 1532 CR_Ods_ID "Output period : 1000 ms until ODS_ID_Received_Flag is set to 1 in ACU1 message";
CM_ BO_ 1262 "[P] Periodic";
CM_ BO_ 916 "[P] Periodic";
CM_ BO_ 1528 "[P] Periodic";
CM_ SG_ 1528 CR_Datc_DrModeAct "This signal is available until proto event. DATC will not send this signal after pilot event";
CM_ SG_ 1528 CR_Datc_TempAct "This signal is available until proto event. DATC will not send this signal after pilot event";
CM_ SG_ 1528 CR_Datc_IntakeAct "This signal is available until proto event. DATC will not send this signal after pilot event";
CM_ SG_ 1528 CR_Datc_AdsAct "This signal is available until proto event. DATC will not send this signal after pilot event";
CM_ SG_ 1528 CR_Datc_SetTemp_C "This signal is available until proto event. DATC will not send this signal after pilot event";
CM_ SG_ 1528 CR_Datc_EvapSnsTemp_C "This signal is available until proto event. DATC will not send this signal after pilot event";
CM_ SG_ 1528 CR_Datc_IncarSnsTemp_C "This signal is available until proto event. DATC will not send this signal after pilot event";
CM_ BO_ 1529 "[P] Periodic";
CM_ SG_ 1529 CR_Datc_DrVentTemp_C "This signal is available until proto event. DATC will not send this signal after pilot event";
CM_ SG_ 1529 CR_Datc_DrFloorTemp_C "This signal is available until proto event. DATC will not send this signal after pilot event";
CM_ SG_ 1529 CR_Datc_PsVentTemp_C "This signal is available until proto event. DATC will not send this signal after pilot event";
CM_ SG_ 1529 CR_Datc_PsFloorTemp_C "This signal is available until proto event. DATC will not send this signal after pilot event";
CM_ SG_ 1529 DATC_BlowerLevel "This signal is for ¡°Gateway¡± applied vehicles only.";
CM_ SG_ 1529 CR_Datc_PhotoSnsFB_V "This signal is available until proto event. DATC will not send this signal after pilot event";
CM_ SG_ 1529 CR_Datc_Humidity "This signal is available until proto event. DATC will not send this signal after pilot event";
CM_ BO_ 2015 "[E] On Event";
CM_ SG_ 2015 FRM_FORMAT "If the value of this signal is not 2H, this signal can be ignored.*)
*) If an ECU has diagnostic communication on CAN service functionallty and communicate with an tester via CAN then must consider other message format. (DO NOT IGNORE OTHER CASES!)";
CM_ BO_ 1530 "[P] Periodic";
CM_ BO_ 911 "[P] Periodic";
CM_ SG_ 911 WHL_SPD13_AliveCounter "After IGN status is changed from ON to OFF, It is necessary to maintain transmitting this message for 3 minutes.";
CM_ SG_ 911 WHL_SPD_RL "After IGN status is changed from ON to OFF, It is necessary to maintain transmitting this message for 3 minutes.";
CM_ SG_ 911 WHL_SPD_RR "After IGN status is changed from ON to OFF, It is necessary to maintain transmitting this message for 3 minutes.";
CM_ BO_ 1509 "[P] Periodic";
CM_ BO_ 910 "[P] Periodic";
CM_ SG_ 910 WHL_SPD12_AliveCounter "After IGN status is changed from ON to OFF, It is necessary to maintain transmitting this message for 3 minutes.";
CM_ SG_ 910 WHL_SPD_FL "After IGN status is changed from ON to OFF, It is necessary to maintain transmitting this message for 3 minutes.";
CM_ SG_ 910 WHL_SPD_FR "After IGN status is changed from ON to OFF, It is necessary to maintain transmitting this message for 3 minutes.";
CM_ BO_ 1511 "[P] Periodic";
CM_ BO_ 1510 "[P] Periodic";
CM_ BO_ 1507 "[PE] Periodic and On Event";
CM_ BO_ 903 "[P] Periodic";
CM_ SG_ 903 WHL_PUL_FL "After IGN status is changed from ON to OFF, It is necessary to maintain transmitting this message for 3 minutes.";
CM_ SG_ 903 WHL_PUL_FR "After IGN status is changed from ON to OFF, It is necessary to maintain transmitting this message for 3 minutes.";
CM_ SG_ 903 WHL_PUL_RL "After IGN status is changed from ON to OFF, It is necessary to maintain transmitting this message for 3 minutes.";
CM_ SG_ 903 WHL_PUL_RR "After IGN status is changed from ON to OFF, It is necessary to maintain transmitting this message for 3 minutes.";
CM_ SG_ 903 WHL_DIR_FL "After IGN status is changed from ON to OFF, It is necessary to maintain transmitting this message for 3 minutes.";
CM_ SG_ 903 WHL_DIR_FR "After IGN status is changed from ON to OFF, It is necessary to maintain transmitting this message for 3 minutes.";
CM_ SG_ 903 WHL_DIR_RL "After IGN status is changed from ON to OFF, It is necessary to maintain transmitting this message for 3 minutes.";
CM_ SG_ 903 WHL_DIR_RR "After IGN status is changed from ON to OFF, It is necessary to maintain transmitting this message for 3 minutes.";
CM_ SG_ 903 WHL_PUL_Chksum "After IGN status is changed from ON to OFF, It is necessary to maintain transmitting this message for 3 minutes.";
CM_ BO_ 1278 "[P] Periodic";
CM_ BO_ 902 "[P] Periodic";
CM_ BO_ 1516 "[PE] Periodic and On Event";
CM_ BO_ 1276 "[P] Periodic";
CM_ SG_ 1276 CF_Aaf31_ActFlapStatus "Unknown : When the potentiometer or other parts are in faulty status, AAF_3 actuator cannot recognize the position of air flaps. In this case, AAF_3 actuator should set the value of CF_Aaf31_ActFlapStatus to ¡°Unknown¡±.";
CM_ BO_ 1277 "[P] Periodic";
CM_ SG_ 1277 CF_Aaf21_ActFlapStatus "Unknown : When the potentiometer or other parts are in faulty status, AAF_2 actuator cannot recognize the position of air flaps. In this case, AAF_2 actuator should set the value of CF_Aaf21_ActFlapStatus to ¡°Unknown¡±.";
CM_ BO_ 1513 "[P] Periodic";
CM_ SG_ 1513 CF_Evse_Mains_Pwr "Fast Charge Input Power from EVSE";
CM_ BO_ 657 "[P] Periodic";
CM_ BO_ 1512 "[P] Periodic";
CM_ BO_ 1426 "[P] Periodic";
CM_ BO_ 1427 "[P] Periodic";
CM_ BO_ 1424 "[P] Periodic";
CM_ SG_ 1424 CF_Ldc_Bat_dischrg "The signal indicates the status of the 'batt discharge notification flag'.";
CM_ BO_ 1019 "[P] Periodic";
CM_ BO_ 1020 "[P] Periodic";
CM_ BO_ 1430 "[P] Periodic";
CM_ BO_ 1021 "[P] Periodic";
CM_ BO_ 1431 "[P] Periodic";
CM_ BO_ 1022 "[P] Periodic";
CM_ BO_ 1428 "[P] Periodic";
CM_ BO_ 1023 "[P] Periodic";
CM_ BO_ 1429 "[P] Periodic";
CM_ BO_ 1432 "[P] Periodic";
CM_ BO_ 1433 "[P] Periodic";
CM_ BO_ 1438 "[P] Periodic";
CM_ BO_ 1014 "[P] Periodic";
CM_ BO_ 1436 "[P] Periodic";
CM_ BO_ 1167 "[E] On Event";
CM_ BO_ 1168 "[P] Periodic";
CM_ BO_ 1410 "[P] Periodic";
CM_ BO_ 1169 "[P] Periodic";
CM_ BO_ 1409 "[P] Periodic";
CM_ SG_ 1409 CR_OBC_Out_Cur "Output period : 1000 ms until ODS_ID_Received_Flag is set to 1 in ACU1 message";
CM_ BO_ 1171 "[P] Periodic";
CM_ BO_ 1414 "[P] Periodic";
CM_ SG_ 1414 CF_Evp1_State "this signal is only for case which the warning lamp is illuminated when the EVP is defective";
CM_ SG_ 1414 CF_Evp1_DefMode "Information regarding the EVP 'defective' State Mode";
CM_ SG_ 1414 CF_Evp1_V_level "Vacuum level";
CM_ SG_ 1414 CF_Evp1_RunCount "This signal indicates Vacuum Pump Running Time information.";
CM_ SG_ 1414 CF_Evp1_RunChk "This signal indicates Vacuum Pump Running Command information.";
CM_ BO_ 765 "[P] Periodic";
CM_ BO_ 1412 "[P] Periodic";
CM_ SG_ 1412 CF_Aaf_ActFlapStatus "Unknown : When the potentiometer or other parts are in faulty status, AAF actuator cannot recognize the position of air flaps. In this case, AAF actuator should set the value of CF_Aaf_ActFlapStatus to ¡°Unknown¡±.";
CM_ SG_ 1412 CF_Aaf_ModeStatus "Fail Safety Mode is indicated when the flap is opened by Fail Safety Mode";
CM_ BO_ 1175 "[P] Periodic";
CM_ BO_ 1176 "[P] Periodic";
CM_ BO_ 1418 "[P] Periodic";
CM_ BO_ 1178 "[PE] Periodic and On Event";
CM_ BO_ 1179 "[P] Periodic";
CM_ BO_ 1423 "[P] Periodic";
CM_ SG_ 1423 CF_Ldc_MainState "Information of the Main State";
CM_ SG_ 1423 CF_Ldc_SubState "Information of the Sub State";
CM_ BO_ 1422 "[P] Periodic";
CM_ BO_ 1182 "[P] Periodic";
CM_ BO_ 1459 "[P] Periodic";
CM_ BO_ 1460 "[PE] Periodic and On Event";
CM_ BO_ 1190 "[E] On Event";
CM_ BO_ 1462 "[PE] Periodic and On Event";
CM_ BO_ 1464 "[PE] Periodic and On Event";
CM_ BO_ 1193 "[PE] Periodic and On Event";
CM_ BO_ 1466 "[E] On Event";
CM_ BO_ 1467 "[E] On Event";
CM_ BO_ 1468 "[E] On Event";
CM_ BO_ 1469 "[PE] Periodic and On Event";
CM_ BO_ 1202 "[E] On Event";
CM_ BO_ 1440 "[P] Periodic";
CM_ BO_ 1443 "[P] Periodic";
CM_ BO_ 1205 "[E] On Event";
BA_DEF_ SG_  "GenSigEnvVarType" ENUM  "Int","Float","Undef";
BA_DEF_ SG_  "GenSigEVName" STRING ;
BA_DEF_ SG_  "GenSigInactiveValue" INT 0 65535;
BA_DEF_ SG_  "GenSigSendType" ENUM  "Cyclic","OnWrite","OnWriteWithRepetition","OnChange","OnChangeWithRepetition","IfActive","IfActiveWithRepetition","NoSigSendType";
BA_DEF_ SG_  "GenSigStartValue" INT 0 1215752192;
BA_DEF_ SG_  "GwSigLatencyTime" INT 0 65535;
BA_DEF_ SG_  "GwSigMissingSourceType" ENUM  "Undef","OldValue","DefaultValue","InitialValue";
BA_DEF_ SG_  "SignalCategory" HEX 10 15;
BA_DEF_ BO_  "GenMsgCycleTime" INT 0 2000;
BA_DEF_ BO_  "GenMsgCycleTimeFast" INT 0 500;
BA_DEF_ BO_  "GenMsgDelayTime" INT 0 20;
BA_DEF_ BO_  "GenMsgILSupport" ENUM  "No","Yes";
BA_DEF_ BO_  "GenMsgNrOfRepetition" INT 0 3;
BA_DEF_ BO_  "GenMsgSendType" ENUM  "Cyclic","not_used","not_used","not_used","not_used","not_used","not_used","not_used","NoMsgSendType";
BA_DEF_ BO_  "GenMsgStartDelayTime" INT 0 2000;
BA_DEF_REL_ BU_SG_REL_  "GenSigTimeoutTime" INT 0 7000;
BA_DEF_DEF_  "GenSigEnvVarType" "Undef";
BA_DEF_DEF_  "GenSigEVName" "@Signame";
BA_DEF_DEF_  "GenSigInactiveValue" 0;
BA_DEF_DEF_  "GenSigSendType" "NoSigSendType";
BA_DEF_DEF_  "GenSigStartValue" 0;
BA_DEF_DEF_  "GwSigLatencyTime" 40;
BA_DEF_DEF_  "GwSigMissingSourceType" "Undef";
BA_DEF_DEF_  "SignalCategory" 12;
BA_DEF_DEF_  "GenMsgCycleTime" 10;
BA_DEF_DEF_  "GenMsgCycleTimeFast" 40;
BA_DEF_DEF_  "GenMsgDelayTime" 20;
BA_DEF_DEF_  "GenMsgILSupport" "Yes";
BA_DEF_DEF_  "GenMsgNrOfRepetition" 0;
BA_DEF_DEF_  "GenMsgSendType" "Cyclic";
BA_DEF_DEF_  "GenMsgStartDelayTime" 0;
BA_DEF_DEF_REL_ "GenSigTimeoutTime" 500;
BA_ "GenMsgCycleTime" BO_ 1250 100;
BA_ "GenMsgCycleTime" BO_ 1532 1000;
BA_ "GenMsgCycleTime" BO_ 1262 100;
BA_ "GenMsgCycleTime" BO_ 916 20;
BA_ "GenMsgCycleTime" BO_ 1528 100;
BA_ "GenMsgCycleTime" BO_ 1529 100;
BA_ "GenMsgNrOfRepetition" BO_ 2015 3;
BA_ "GenMsgCycleTime" BO_ 2015 0;
BA_ "GenMsgSendType" BO_ 2015 8;
BA_ "GenMsgCycleTime" BO_ 1530 1000;
BA_ "GenMsgCycleTime" BO_ 911 20;
BA_ "GenMsgCycleTime" BO_ 1509 100;
BA_ "GenMsgCycleTime" BO_ 910 20;
BA_ "GenMsgCycleTime" BO_ 1511 100;
BA_ "GenMsgCycleTime" BO_ 1510 100;
BA_ "GenMsgNrOfRepetition" BO_ 1507 3;
BA_ "GenMsgCycleTime" BO_ 1507 1000;
BA_ "GenMsgCycleTime" BO_ 903 20;
BA_ "GenMsgCycleTime" BO_ 1278 200;
BA_ "GenMsgCycleTime" BO_ 902 20;
BA_ "GenMsgNrOfRepetition" BO_ 1516 3;
BA_ "GenMsgCycleTime" BO_ 1516 100;
BA_ "GenMsgCycleTime" BO_ 1276 100;
BA_ "GenMsgCycleTime" BO_ 1277 100;
BA_ "GenMsgCycleTime" BO_ 1513 100;
BA_ "GenMsgCycleTime" BO_ 1512 100;
BA_ "GenMsgCycleTime" BO_ 1426 100;
BA_ "GenMsgCycleTime" BO_ 1427 200;
BA_ "GenMsgCycleTime" BO_ 1424 100;
BA_ "GenMsgCycleTime" BO_ 1019 100;
BA_ "GenMsgCycleTime" BO_ 1020 100;
BA_ "GenMsgCycleTime" BO_ 1430 100;
BA_ "GenMsgCycleTime" BO_ 1021 200;
BA_ "GenMsgCycleTime" BO_ 1431 100;
BA_ "GenMsgCycleTime" BO_ 1022 100;
BA_ "GenMsgCycleTime" BO_ 1428 100;
BA_ "GenMsgCycleTime" BO_ 1023 50;
BA_ "GenMsgCycleTime" BO_ 1429 100;
BA_ "GenMsgCycleTime" BO_ 1432 100;
BA_ "GenMsgCycleTime" BO_ 1433 100;
BA_ "GenMsgCycleTime" BO_ 1438 100;
BA_ "GenMsgCycleTime" BO_ 1014 1000;
BA_ "GenMsgCycleTime" BO_ 1436 100;
BA_ "GenMsgNrOfRepetition" BO_ 1167 3;
BA_ "GenMsgCycleTime" BO_ 1167 0;
BA_ "GenMsgSendType" BO_ 1167 8;
BA_ "GenMsgCycleTime" BO_ 1168 50;
BA_ "GenMsgCycleTime" BO_ 1410 100;
BA_ "GenMsgCycleTime" BO_ 1169 100;
BA_ "GenMsgCycleTime" BO_ 1409 100;
BA_ "GenMsgCycleTime" BO_ 1171 100;
BA_ "GenMsgCycleTime" BO_ 1414 100;
BA_ "GenMsgCycleTime" BO_ 1412 100;
BA_ "GenMsgCycleTime" BO_ 1175 1000;
BA_ "GenMsgCycleTime" BO_ 1176 1000;
BA_ "GenMsgCycleTime" BO_ 1418 200;
BA_ "GenMsgNrOfRepetition" BO_ 1178 3;
BA_ "GenMsgCycleTime" BO_ 1178 200;
BA_ "GenMsgCycleTime" BO_ 1179 200;
BA_ "GenMsgCycleTime" BO_ 1423 100;
BA_ "GenMsgCycleTime" BO_ 1422 100;
BA_ "GenMsgCycleTime" BO_ 1182 100;
BA_ "GenMsgCycleTime" BO_ 1459 200;
BA_ "GenMsgNrOfRepetition" BO_ 1460 3;
BA_ "GenMsgCycleTime" BO_ 1460 200;
BA_ "GenMsgNrOfRepetition" BO_ 1190 3;
BA_ "GenMsgCycleTime" BO_ 1190 0;
BA_ "GenMsgSendType" BO_ 1190 8;
BA_ "GenMsgNrOfRepetition" BO_ 1462 3;
BA_ "GenMsgCycleTime" BO_ 1462 200;
BA_ "GenMsgNrOfRepetition" BO_ 1464 3;
BA_ "GenMsgCycleTime" BO_ 1464 200;
BA_ "GenMsgNrOfRepetition" BO_ 1193 3;
BA_ "GenMsgCycleTime" BO_ 1193 200;
BA_ "GenMsgNrOfRepetition" BO_ 1466 3;
BA_ "GenMsgCycleTime" BO_ 1466 0;
BA_ "GenMsgSendType" BO_ 1466 8;
BA_ "GenMsgNrOfRepetition" BO_ 1467 3;
BA_ "GenMsgCycleTime" BO_ 1467 0;
BA_ "GenMsgSendType" BO_ 1467 8;
BA_ "GenMsgNrOfRepetition" BO_ 1468 3;
BA_ "GenMsgCycleTime" BO_ 1468 0;
BA_ "GenMsgSendType" BO_ 1468 8;
BA_ "GenMsgNrOfRepetition" BO_ 1469 3;
BA_ "GenMsgCycleTime" BO_ 1469 1000;
BA_ "GenMsgNrOfRepetition" BO_ 1202 3;
BA_ "GenMsgCycleTime" BO_ 1202 0;
BA_ "GenMsgSendType" BO_ 1202 8;
BA_ "GenMsgCycleTime" BO_ 1440 1000;
BA_ "GenMsgCycleTime" BO_ 1443 100;
BA_ "GenMsgNrOfRepetition" BO_ 1205 3;
BA_ "GenMsgCycleTime" BO_ 1205 0;
BA_ "GenMsgSendType" BO_ 1205 8;
BA_ "GenSigStartValue" SG_ 1528 CF_Fatc_BlowerStatus 3;
BA_ "GenSigStartValue" SG_ 1528 CF_Fatc_DriverOnly 3;
BA_ "GenSigStartValue" SG_ 1529 DATC_BlowerLevel 15;
BA_ "GenSigSendType" SG_ 2015 FRM_FORMAT 4;
BA_ "GenSigSendType" SG_ 2015 SID 4;
BA_ "GenSigSendType" SG_ 2015 REQ_RESPONSE 4;
BA_ "GenSigStartValue" SG_ 1530 CR_Wcs_ClassStat 4;
BA_ "GenSigStartValue" SG_ 911 CRC 255;
BA_ "GenSigStartValue" SG_ 910 CRC 255;
BA_ "GenSigStartValue" SG_ 1510 CR_Ccm_EvseTransferType 15;
BA_ "GenSigSendType" SG_ 1507 CR_VCU_EcoLvl 4;
BA_ "GenSigStartValue" SG_ 1278 POS_RelativeHeading 255;
BA_ "GenSigStartValue" SG_ 1278 POS_RangeAvgSpeed 255;
BA_ "GenSigStartValue" SG_ 1278 POS_CurrentLane 7;
BA_ "GenSigStartValue" SG_ 1278 POS_PositionConfidence 7;
BA_ "GenSigStartValue" SG_ 1278 POS_PositionAge 511;
BA_ "GenSigStartValue" SG_ 1278 POS_PositionProbability 31;
BA_ "GenSigStartValue" SG_ 1278 POS_PositionIndex 3;
BA_ "GenSigStartValue" SG_ 1278 POS_Offset 8191;
BA_ "GenSigStartValue" SG_ 1278 POS_MessageType 7;
BA_ "GenSigSendType" SG_ 1516 C_InletLockStatus 4;
BA_ "GenSigSendType" SG_ 1516 C_Ign3Rly 4;
BA_ "GenSigSendType" SG_ 1516 C_InletFailStatus 4;
BA_ "SignalCategory" SG_ 1516 C_CtrDrLockRly 10;
BA_ "GenSigSendType" SG_ 1516 C_CtrDrLockRly 4;
BA_ "SignalCategory" SG_ 1516 C_CtrDrUnlockRly 10;
BA_ "GenSigSendType" SG_ 1516 C_CtrDrUnlockRly 4;
BA_ "SignalCategory" SG_ 1516 C_DrvDrUnlockRly 10;
BA_ "GenSigSendType" SG_ 1516 C_DrvDrUnlockRly 4;
BA_ "GenSigSendType" SG_ 1516 C_Inlet_ServiceLamp_Req 4;
BA_ "GenSigSendType" SG_ 1516 C_FRECOState 4;
BA_ "GenSigStartValue" SG_ 1516 C_DHVSeatOperationFB 1;
BA_ "GenSigSendType" SG_ 1516 C_DHVSeatOperationFB 4;
BA_ "GenSigStartValue" SG_ 1516 C_AHVSeatOperationFB 1;
BA_ "GenSigSendType" SG_ 1516 C_AHVSeatOperationFB 4;
BA_ "GenSigStartValue" SG_ 1516 C_RLHVSeatOperationFB 1;
BA_ "GenSigSendType" SG_ 1516 C_RLHVSeatOperationFB 4;
BA_ "GenSigStartValue" SG_ 1516 C_RRHSeatOperationFB 1;
BA_ "GenSigSendType" SG_ 1516 C_RRHSeatOperationFB 4;
BA_ "GenSigSendType" SG_ 1516 C_RRECOState 4;
BA_ "SignalCategory" SG_ 1516 C_StrgWhlHeatedState 10;
BA_ "GenSigSendType" SG_ 1516 C_StrgWhlHeatedState 4;
BA_ "SignalCategory" SG_ 1516 C_SBRMatSw 10;
BA_ "GenSigSendType" SG_ 1516 C_SBRMatSw 4;
BA_ "GenSigStartValue" SG_ 1276 CF_Aaf31_ActFlapStatus 1;
BA_ "GenSigStartValue" SG_ 1277 CF_Aaf21_ActFlapStatus 1;
BA_ "GenSigStartValue" SG_ 1426 CF_Vcu_LdcInh 1;
BA_ "GenSigStartValue" SG_ 1428 CR_Bms_Soc_Pc 60;
BA_ "GenSigStartValue" SG_ 1429 CR_Bms_BatMinCel_V 3;
BA_ "GenSigStartValue" SG_ 1429 CR_Bms_BatMaxCel_V 3;
BA_ "GenSigStartValue" SG_ 1167 HU_DATC_DrTempSetC 255;
BA_ "GenSigSendType" SG_ 1167 HU_DATC_DrTempSetC 4;
BA_ "GenSigStartValue" SG_ 1167 HU_DATC_DrTempSetF 255;
BA_ "GenSigSendType" SG_ 1167 HU_DATC_DrTempSetF 4;
BA_ "GenSigStartValue" SG_ 1167 HU_DATC_MainBlower 15;
BA_ "GenSigSendType" SG_ 1167 HU_DATC_MainBlower 4;
BA_ "GenSigStartValue" SG_ 1167 HU_DATC_FrontModeSet 15;
BA_ "GenSigSendType" SG_ 1167 HU_DATC_FrontModeSet 4;
BA_ "GenSigStartValue" SG_ 1167 HU_DATC_AutoSet 3;
BA_ "GenSigSendType" SG_ 1167 HU_DATC_AutoSet 4;
BA_ "GenSigStartValue" SG_ 1167 HU_DATC_AcSet 3;
BA_ "GenSigSendType" SG_ 1167 HU_DATC_AcSet 4;
BA_ "GenSigStartValue" SG_ 1167 HU_DATC_IntakeSet 3;
BA_ "GenSigSendType" SG_ 1167 HU_DATC_IntakeSet 4;
BA_ "GenSigStartValue" SG_ 1167 HU_DATC_FrontDefog 3;
BA_ "GenSigSendType" SG_ 1167 HU_DATC_FrontDefog 4;
BA_ "GenSigStartValue" SG_ 1167 HU_DATC_AirCleaningSet 3;
BA_ "GenSigSendType" SG_ 1167 HU_DATC_AirCleaningSet 4;
BA_ "GenSigStartValue" SG_ 1167 HU_DATC_ADSOnOffSet 3;
BA_ "GenSigSendType" SG_ 1167 HU_DATC_ADSOnOffSet 4;
BA_ "GenSigStartValue" SG_ 1168 EPB_FAIL 2;
BA_ "GenSigStartValue" SG_ 1168 EPB_FORCE 1000;
BA_ "GenSigStartValue" SG_ 1412 CF_Aaf_ActFlapStatus 1;
BA_ "GenSigStartValue" SG_ 1178 Navi_AirConditionType 63;
BA_ "GenSigSendType" SG_ 1178 Navi_AirConditionType 4;
BA_ "GenSigStartValue" SG_ 1178 Navi_AirConditionWarning 3;
BA_ "GenSigSendType" SG_ 1178 Navi_AirConditionWarning 4;
BA_ "GenSigStartValue" SG_ 1422 CF_OBC_Plug_Type 3;
BA_ "GenSigStartValue" SG_ 1459 C_EV_SpeedLimitOnOff 3;
BA_ "GenSigStartValue" SG_ 1459 C_EV_NormalClimateLimit 3;
BA_ "GenSigStartValue" SG_ 1459 C_EV_SportClimateLimit 3;
BA_ "GenSigStartValue" SG_ 1459 C_EV_EcoClimateLimit 3;
BA_ "GenSigStartValue" SG_ 1459 C_EV_NormalRegenrationLevel 3;
BA_ "GenSigStartValue" SG_ 1459 C_EV_SportRegenrationLevel 3;
BA_ "GenSigStartValue" SG_ 1459 C_EV_EcoRegenrationLevel 3;
BA_ "GenSigStartValue" SG_ 1459 C_EV_ClimateScnOnOff 3;
BA_ "GenSigStartValue" SG_ 1459 C_EV_MaxSpeed 255;
BA_ "GenSigStartValue" SG_ 1459 HU_EV_GpsSchedUpdateRes 3;
BA_ "GenSigStartValue" SG_ 1459 HU_EV_GpsSched_State 3;
BA_ "GenSigStartValue" SG_ 1459 HU_EV_GpsSched_ChgAir 3;
BA_ "GenSigStartValue" SG_ 1460 HU_TempUnit 3;
BA_ "GenSigSendType" SG_ 1460 HU_TempUnit 4;
BA_ "GenSigStartValue" SG_ 1460 CF_AVN_ProfileIDRValue 15;
BA_ "GenSigSendType" SG_ 1460 CF_AVN_ProfileIDRValue 4;
BA_ "GenSigSendType" SG_ 1190 CF_AVN_CluUSMReset 4;
BA_ "GenSigSendType" SG_ 1462 CF_Gway_RrLftSeatBeltSw 4;
BA_ "GenSigSendType" SG_ 1462 CF_Gway_RrCtrSeatBeltSw 4;
BA_ "GenSigSendType" SG_ 1462 CF_Gway_RrRtSeatBeltSw 4;
BA_ "GenSigSendType" SG_ 1464 C_FRSeatTumblerSW 4;
BA_ "GenSigSendType" SG_ 1464 C_FLSeatTumblerSW 4;
BA_ "GenSigSendType" SG_ 1464 DATC_FRWndShldHtSW 4;
BA_ "GenSigSendType" SG_ 1464 DATC_WhistlelNoise 4;
BA_ "GenSigSendType" SG_ 1193 CR_Datc_DRSeatHeat_USM_Set 4;
BA_ "GenSigSendType" SG_ 1193 C_AutoLeverManualSW 4;
BA_ "GenSigSendType" SG_ 1193 C_DiagnConnStatus 4;
BA_ "GenSigSendType" SG_ 1193 C_PTGMOpt 4;
BA_ "GenSigSendType" SG_ 1193 C_PTGOpnClsState 4;
BA_ "GenSigSendType" SG_ 1193 C_RKETeleEngineRunning 4;
BA_ "GenSigSendType" SG_ 1466 CF_AVN_AuxBatChargeNValueSet 4;
BA_ "GenSigSendType" SG_ 1466 CF_AVN_SmartRegenNValueSet 4;
BA_ "GenSigSendType" SG_ 1466 CF_AVN_RestModeNValueSet 4;
BA_ "GenSigStartValue" SG_ 1467 DATC_Beep1Mode 3;
BA_ "GenSigSendType" SG_ 1467 DATC_Beep1Mode 4;
BA_ "GenSigStartValue" SG_ 1468 DATC_AMP_Beep1VolumeStep 255;
BA_ "GenSigSendType" SG_ 1468 DATC_AMP_Beep1VolumeStep 4;
BA_ "GenSigStartValue" SG_ 1468 DATC_AMP_Beep1Frequency 65535;
BA_ "GenSigSendType" SG_ 1468 DATC_AMP_Beep1Frequency 4;
BA_ "GenSigStartValue" SG_ 1468 DATC_AMP_Beep1Ch_OutputMask 65535;
BA_ "GenSigSendType" SG_ 1468 DATC_AMP_Beep1Ch_OutputMask 4;
BA_ "GenSigStartValue" SG_ 1468 DATC_AMP_Beep1DurationOn 255;
BA_ "GenSigSendType" SG_ 1468 DATC_AMP_Beep1DurationOn 4;
BA_ "GenSigStartValue" SG_ 1468 DATC_AMP_Beep1DurationOff 255;
BA_ "GenSigSendType" SG_ 1468 DATC_AMP_Beep1DurationOff 4;
BA_ "GenSigStartValue" SG_ 1468 DATC_AMP_Beep1NumberOfCycles 255;
BA_ "GenSigSendType" SG_ 1468 DATC_AMP_Beep1NumberOfCycles 4;
BA_ "GenSigStartValue" SG_ 1469 HU_DATC_Beep1VolumeStep 255;
BA_ "GenSigSendType" SG_ 1469 HU_DATC_Beep1VolumeStep 4;
BA_ "GenSigStartValue" SG_ 1469 HU_DATC_Beep1Frequency 65535;
BA_ "GenSigSendType" SG_ 1469 HU_DATC_Beep1Frequency 4;
BA_ "GenSigStartValue" SG_ 1469 HU_DATC_Beep1Ch_OutputMask 65535;
BA_ "GenSigSendType" SG_ 1469 HU_DATC_Beep1Ch_OutputMask 4;
BA_ "GenSigStartValue" SG_ 1469 HU_DATC_Beep1DurationOn 255;
BA_ "GenSigSendType" SG_ 1469 HU_DATC_Beep1DurationOn 4;
BA_ "GenSigStartValue" SG_ 1469 HU_DATC_Beep1DurationOff 255;
BA_ "GenSigSendType" SG_ 1469 HU_DATC_Beep1DurationOff 4;
BA_ "GenSigStartValue" SG_ 1469 HU_DATC_Beep1NumberOfCycles 255;
BA_ "GenSigSendType" SG_ 1469 HU_DATC_Beep1NumberOfCycles 4;
BA_ "GenSigSendType" SG_ 1202 CF_AVN_FCANValueSet 4;
BA_ "GenSigSendType" SG_ 1202 CF_AVN_PasSpkrLvNValueSet 4;
BA_ "GenSigSendType" SG_ 1202 CF_AVN_SCCDrvModeNValueSet 4;
BA_ "GenSigSendType" SG_ 1202 CF_AVN_DAWModeNValueSet 4;
BA_ "GenSigSendType" SG_ 1202 CF_AVN_HDA_LFANValueSet 4;
BA_ "GenSigSendType" SG_ 1202 CF_AVN_BCWNValueSet 4;
BA_ "GenSigSendType" SG_ 1202 CF_AVN_SEANValueSet 4;
BA_ "GenSigSendType" SG_ 1202 CF_AVN_NSCCCamNValueSet 4;
BA_ "GenSigSendType" SG_ 1202 CF_AVN_BCANValueSet 4;
BA_ "GenSigSendType" SG_ 1202 CF_AVN_ISLWNValueSet 4;
BA_ "GenSigSendType" SG_ 1202 CF_AVN_WarningTimingNValueSet 4;
BA_ "GenSigSendType" SG_ 1202 CF_AVN_NCC_USM_set 4;
BA_ "GenSigSendType" SG_ 1202 CF_AVN_TirePressUnitNValueSet 4;
BA_ "GenSigSendType" SG_ 1202 CF_AVN_RCCANValueSet 4;
BA_ "GenSigSendType" SG_ 1202 CF_AVN_NSCCCrvNValueSet 4;
BA_ "GenSigSendType" SG_ 1202 CF_AVN_BCWSndWanNValueSet 4;
BA_ "GenSigSendType" SG_ 1202 CF_AVN_RCCWNValueSet 4;
BA_ "GenSigSendType" SG_ 1202 CF_AVN_LkaModeNValueSet 4;
BA_ "GenSigStartValue" SG_ 1440 CF_PasBkl_Stat 1;
BA_ "GenSigStartValue" SG_ 1440 CF_DriBkl_Stat 1;
BA_ "GenSigStartValue" SG_ 1440 CF_Acu_FltStat 2;
BA_ "GenSigSendType" SG_ 1205 CF_AVN_CluUSMReset 4;
BA_ "GenSigSendType" SG_ 1205 CF_AVN_UnitReset 4;
BA_REL_ "GenSigTimeoutTime" BU_SG_REL_ CGW SG_ 1250 CR_Bms_ScChgRemTime_ICCB_Dom 2000;
BA_REL_ "GenSigTimeoutTime" BU_SG_REL_ TMU SG_ 1250 CR_Bms_ScChgRemTime_ICCB_Dom 2000;
BA_REL_ "GenSigTimeoutTime" BU_SG_REL_ CGW SG_ 1250 CR_Bms_ScChgRemTime_ICCB_Euro 2000;
BA_REL_ "GenSigTimeoutTime" BU_SG_REL_ TMU SG_ 1250 CR_Bms_ScChgRemTime_ICCB_Euro 2000;
BA_REL_ "GenSigTimeoutTime" BU_SG_REL_ CGW SG_ 1250 CR_Bms_RealScChgRemTime 2000;
BA_REL_ "GenSigTimeoutTime" BU_SG_REL_ TMU SG_ 1250 CR_Bms_RealScChgRemTime 2000;
BA_REL_ "GenSigTimeoutTime" BU_SG_REL_ TMU SG_ 1250 CR_Bms_3wayVav_CtrlMode 2000;
BA_REL_ "GenSigTimeoutTime" BU_SG_REL_ vBDM SG_ 1250 CR_Bms_3wayVav_CtrlMode 2000;
BA_REL_ "GenSigTimeoutTime" BU_SG_REL_ TMU SG_ 1250 CR_Bms_BTMS_SubCode1 2000;
BA_REL_ "GenSigTimeoutTime" BU_SG_REL_ TMU SG_ 1250 CR_Bms_BTMS_Subcode2 2000;
BA_REL_ "GenSigTimeoutTime" BU_SG_REL_ TMU SG_ 1250 CR_Bms_BTMS_Subcode3 2000;
BA_REL_ "GenSigTimeoutTime" BU_SG_REL_ TMU SG_ 1250 CR_Bms_3WayVav_CtrlMode2 2000;
BA_REL_ "GenSigTimeoutTime" BU_SG_REL_ TMU SG_ 1250 CF_Bms_WCS_HeaterRlyOnStat 2000;
BA_REL_ "GenSigTimeoutTime" BU_SG_REL_ TMU SG_ 1250 CF_Bms_BTMSdiag_flag 2000;
BA_REL_ "GenSigTimeoutTime" BU_SG_REL_ ACU SG_ 1532 CR_Ods_ID 5000;
BA_REL_ "GenSigTimeoutTime" BU_SG_REL_ ACU SG_ 1532 ODS_Crc2Val 5000;
BA_REL_ "GenSigTimeoutTime" BU_SG_REL_ Dummy SG_ 1532 ODS_Crc2Val 5000;
BA_REL_ "GenSigTimeoutTime" BU_SG_REL_ ACU SG_ 1532 ODS_AlvCnt2Val 5000;
BA_REL_ "GenSigTimeoutTime" BU_SG_REL_ Dummy SG_ 1532 ODS_AlvCnt2Val 5000;
BA_REL_ "GenSigTimeoutTime" BU_SG_REL_ CGW SG_ 1262 CF_OBC_Lamp_Req 2000;
BA_REL_ "GenSigTimeoutTime" BU_SG_REL_ TMU SG_ 1262 CF_OBC_Lamp_Req 2000;
BA_REL_ "GenSigTimeoutTime" BU_SG_REL_ vBDM SG_ 1262 CF_OBC_Lamp_Req 2000;
BA_REL_ "GenSigTimeoutTime" BU_SG_REL_ BMS SG_ 1262 CF_OBC_EVSE_RDY_STATE 2000;
BA_REL_ "GenSigTimeoutTime" BU_SG_REL_ TMU SG_ 1262 CF_OBC_EVSE_RDY_STATE 2000;
BA_REL_ "GenSigTimeoutTime" BU_SG_REL_ VCU SG_ 1262 CF_OBC_EVSE_RDY_STATE 2000;
BA_REL_ "GenSigTimeoutTime" BU_SG_REL_ CCM SG_ 1262 CF_EVSE_FAULT_FLAG 2000;
BA_REL_ "GenSigTimeoutTime" BU_SG_REL_ CGW SG_ 1262 CF_EVSE_FAULT_FLAG 2000;
BA_REL_ "GenSigTimeoutTime" BU_SG_REL_ TMU SG_ 1262 CF_EVSE_FAULT_FLAG 2000;
BA_REL_ "GenSigTimeoutTime" BU_SG_REL_ Dummy SG_ 1262 CR_OBC_DiagInfoGrp 20000;
BA_REL_ "GenSigTimeoutTime" BU_SG_REL_ CGW SG_ 1262 CF_OBC_ChargeInlet_Type 2000;
BA_REL_ "GenSigTimeoutTime" BU_SG_REL_ TMU SG_ 1262 CF_OBC_ChargeInlet_Type 2000;
BA_REL_ "GenSigTimeoutTime" BU_SG_REL_ CGW SG_ 916 DF_BF_STAT 0;
BA_REL_ "GenSigTimeoutTime" BU_SG_REL_ Dummy SG_ 916 FCA_CODED_STAT 0;
BA_REL_ "GenSigTimeoutTime" BU_SG_REL_ VCU SG_ 916 SCC_CODED_STAT 0;
BA_REL_ "GenSigTimeoutTime" BU_SG_REL_ Dummy SG_ 916 ESC_BcaRPlusSta 0;
BA_REL_ "GenSigTimeoutTime" BU_SG_REL_ VCU SG_ 1528 CR_Datc_DrModeAct 2000;
BA_REL_ "GenSigTimeoutTime" BU_SG_REL_ LDC SG_ 1528 CR_Fatc_Cooldown 2000;
BA_REL_ "GenSigTimeoutTime" BU_SG_REL_ VCU SG_ 1528 CR_Fatc_Cooldown 2000;
BA_REL_ "GenSigTimeoutTime" BU_SG_REL_ LDC SG_ 1528 CR_Fatc_MildCooldown 2000;
BA_REL_ "GenSigTimeoutTime" BU_SG_REL_ VCU SG_ 1528 CR_Fatc_MildCooldown 2000;
BA_REL_ "GenSigTimeoutTime" BU_SG_REL_ LDC SG_ 1528 CR_Fatc_Warmup 2000;
BA_REL_ "GenSigTimeoutTime" BU_SG_REL_ VCU SG_ 1528 CR_Fatc_Warmup 2000;
BA_REL_ "GenSigTimeoutTime" BU_SG_REL_ LDC SG_ 1528 CR_Fatc_MildWarmup 2000;
BA_REL_ "GenSigTimeoutTime" BU_SG_REL_ VCU SG_ 1528 CR_Fatc_MildWarmup 2000;
BA_REL_ "GenSigTimeoutTime" BU_SG_REL_ VCU SG_ 1528 CF_Fatc_BlowerStatus 2000;
BA_REL_ "GenSigTimeoutTime" BU_SG_REL_ CGW SG_ 1528 CF_Fatc_DriverOnly 2000;
BA_REL_ "GenSigTimeoutTime" BU_SG_REL_ VCU SG_ 1528 CF_Fatc_DriverOnly 2000;
BA_REL_ "GenSigTimeoutTime" BU_SG_REL_ VCU SG_ 1528 CR_Datc_TempAct 2000;
BA_REL_ "GenSigTimeoutTime" BU_SG_REL_ VCU SG_ 1528 CR_Datc_IntakeAct 2000;
BA_REL_ "GenSigTimeoutTime" BU_SG_REL_ VCU SG_ 1528 CR_Datc_AdsAct 2000;
BA_REL_ "GenSigTimeoutTime" BU_SG_REL_ TMU SG_ 1528 CR_Datc_SetTemp_C 2000;
BA_REL_ "GenSigTimeoutTime" BU_SG_REL_ VCU SG_ 1528 CR_Datc_SetTemp_C 2000;
BA_REL_ "GenSigTimeoutTime" BU_SG_REL_ VCU SG_ 1528 CR_Datc_EvapSnsTemp_C 2000;
BA_REL_ "GenSigTimeoutTime" BU_SG_REL_ BMS SG_ 1528 CR_Datc_IncarSnsTemp_C 2000;
BA_REL_ "GenSigTimeoutTime" BU_SG_REL_ TMU SG_ 1528 CR_Datc_IncarSnsTemp_C 2000;
BA_REL_ "GenSigTimeoutTime" BU_SG_REL_ VCU SG_ 1528 CR_Datc_IncarSnsTemp_C 2000;
BA_REL_ "GenSigTimeoutTime" BU_SG_REL_ CGW SG_ 1529 CR_Datc_DrVentTemp_C 2000;
BA_REL_ "GenSigTimeoutTime" BU_SG_REL_ VCU SG_ 1529 CR_Datc_DrVentTemp_C 2000;
BA_REL_ "GenSigTimeoutTime" BU_SG_REL_ vBDM SG_ 1529 CR_Datc_DrVentTemp_C 2000;
BA_REL_ "GenSigTimeoutTime" BU_SG_REL_ VCU SG_ 1529 CR_Datc_DrFloorTemp_C 2000;
BA_REL_ "GenSigTimeoutTime" BU_SG_REL_ VCU SG_ 1529 CR_Datc_PsVentTemp_C 2000;
BA_REL_ "GenSigTimeoutTime" BU_SG_REL_ VCU SG_ 1529 CR_Datc_PsFloorTemp_C 2000;
BA_REL_ "GenSigTimeoutTime" BU_SG_REL_ TMU SG_ 1529 DATC_BlowerLevel 2000;
BA_REL_ "GenSigTimeoutTime" BU_SG_REL_ VCU SG_ 1529 DATC_BlowerLevel 2000;
BA_REL_ "GenSigTimeoutTime" BU_SG_REL_ AAF SG_ 1529 CF_Fatc_AAFOpenReq 2000;
BA_REL_ "GenSigTimeoutTime" BU_SG_REL_ VCU SG_ 1529 CR_Datc_PhotoSnsFB_V 2000;
BA_REL_ "GenSigTimeoutTime" BU_SG_REL_ BMS SG_ 1529 CF_Fatc_BatEwpOperReq 2000;
BA_REL_ "GenSigTimeoutTime" BU_SG_REL_ MCU SG_ 1529 CF_Fatc_BatEwpOperReq 2000;
BA_REL_ "GenSigTimeoutTime" BU_SG_REL_ VCU SG_ 1529 CR_Datc_Humidity 2000;
BA_REL_ "GenSigTimeoutTime" BU_SG_REL_ AAF SG_ 2015 FRM_FORMAT 0;
BA_REL_ "GenSigTimeoutTime" BU_SG_REL_ ACU SG_ 2015 FRM_FORMAT 0;
BA_REL_ "GenSigTimeoutTime" BU_SG_REL_ BMS SG_ 2015 FRM_FORMAT 0;
BA_REL_ "GenSigTimeoutTime" BU_SG_REL_ DATC SG_ 2015 FRM_FORMAT 0;
BA_REL_ "GenSigTimeoutTime" BU_SG_REL_ EWP SG_ 2015 FRM_FORMAT 0;
BA_REL_ "GenSigTimeoutTime" BU_SG_REL_ LDC SG_ 2015 FRM_FORMAT 0;
BA_REL_ "GenSigTimeoutTime" BU_SG_REL_ MCU SG_ 2015 FRM_FORMAT 0;
BA_REL_ "GenSigTimeoutTime" BU_SG_REL_ ODS SG_ 2015 FRM_FORMAT 0;
BA_REL_ "GenSigTimeoutTime" BU_SG_REL_ VCU SG_ 2015 FRM_FORMAT 0;
BA_REL_ "GenSigTimeoutTime" BU_SG_REL_ VESS SG_ 2015 FRM_FORMAT 0;
BA_REL_ "GenSigTimeoutTime" BU_SG_REL_ iBAU SG_ 2015 FRM_FORMAT 0;
BA_REL_ "GenSigTimeoutTime" BU_SG_REL_ AAF SG_ 2015 SID 0;
BA_REL_ "GenSigTimeoutTime" BU_SG_REL_ ACU SG_ 2015 SID 0;
BA_REL_ "GenSigTimeoutTime" BU_SG_REL_ BMS SG_ 2015 SID 0;
BA_REL_ "GenSigTimeoutTime" BU_SG_REL_ DATC SG_ 2015 SID 0;
BA_REL_ "GenSigTimeoutTime" BU_SG_REL_ EWP SG_ 2015 SID 0;
BA_REL_ "GenSigTimeoutTime" BU_SG_REL_ LDC SG_ 2015 SID 0;
BA_REL_ "GenSigTimeoutTime" BU_SG_REL_ MCU SG_ 2015 SID 0;
BA_REL_ "GenSigTimeoutTime" BU_SG_REL_ ODS SG_ 2015 SID 0;
BA_REL_ "GenSigTimeoutTime" BU_SG_REL_ VCU SG_ 2015 SID 0;
BA_REL_ "GenSigTimeoutTime" BU_SG_REL_ VESS SG_ 2015 SID 0;
BA_REL_ "GenSigTimeoutTime" BU_SG_REL_ iBAU SG_ 2015 SID 0;
BA_REL_ "GenSigTimeoutTime" BU_SG_REL_ AAF SG_ 2015 REQ_RESPONSE 0;
BA_REL_ "GenSigTimeoutTime" BU_SG_REL_ ACU SG_ 2015 REQ_RESPONSE 0;
BA_REL_ "GenSigTimeoutTime" BU_SG_REL_ BMS SG_ 2015 REQ_RESPONSE 0;
BA_REL_ "GenSigTimeoutTime" BU_SG_REL_ DATC SG_ 2015 REQ_RESPONSE 0;
BA_REL_ "GenSigTimeoutTime" BU_SG_REL_ EWP SG_ 2015 REQ_RESPONSE 0;
BA_REL_ "GenSigTimeoutTime" BU_SG_REL_ LDC SG_ 2015 REQ_RESPONSE 0;
BA_REL_ "GenSigTimeoutTime" BU_SG_REL_ MCU SG_ 2015 REQ_RESPONSE 0;
BA_REL_ "GenSigTimeoutTime" BU_SG_REL_ ODS SG_ 2015 REQ_RESPONSE 0;
BA_REL_ "GenSigTimeoutTime" BU_SG_REL_ VCU SG_ 2015 REQ_RESPONSE 0;
BA_REL_ "GenSigTimeoutTime" BU_SG_REL_ VESS SG_ 2015 REQ_RESPONSE 0;
BA_REL_ "GenSigTimeoutTime" BU_SG_REL_ iBAU SG_ 2015 REQ_RESPONSE 0;
BA_REL_ "GenSigTimeoutTime" BU_SG_REL_ ACU SG_ 1530 ODS_Crc1Val 5000;
BA_REL_ "GenSigTimeoutTime" BU_SG_REL_ Dummy SG_ 1530 ODS_Crc1Val 5000;
BA_REL_ "GenSigTimeoutTime" BU_SG_REL_ ACU SG_ 1530 ODS_AlvCnt1Val 5000;
BA_REL_ "GenSigTimeoutTime" BU_SG_REL_ Dummy SG_ 1530 ODS_AlvCnt1Val 5000;
BA_REL_ "GenSigTimeoutTime" BU_SG_REL_ ACU SG_ 1530 CR_Wcs_ErrStat 5000;
BA_REL_ "GenSigTimeoutTime" BU_SG_REL_ ACU SG_ 1530 CR_Wcs_ClassStat 5000;
BA_REL_ "GenSigTimeoutTime" BU_SG_REL_ CGW SG_ 1530 CR_Wcs_ClassStat 5000;
BA_REL_ "GenSigTimeoutTime" BU_SG_REL_ H_U SG_ 1530 CR_Wcs_ClassStat 5000;
BA_REL_ "GenSigTimeoutTime" BU_SG_REL_ TMU SG_ 1530 CR_Wcs_ClassStat 5000;
BA_REL_ "GenSigTimeoutTime" BU_SG_REL_ VCU SG_ 1530 CR_Wcs_ClassStat 5000;
BA_REL_ "GenSigTimeoutTime" BU_SG_REL_ BMS SG_ 1509 CR_Ccm_MaxVolt_V 2000;
BA_REL_ "GenSigTimeoutTime" BU_SG_REL_ BMS SG_ 1509 CR_Ccm_MaxCurr_A 2000;
BA_REL_ "GenSigTimeoutTime" BU_SG_REL_ CGW SG_ 1509 CR_Ccm_MaxCurr_A 2000;
BA_REL_ "GenSigTimeoutTime" BU_SG_REL_ vBDM SG_ 1509 CR_Ccm_MaxCurr_A 2000;
BA_REL_ "GenSigTimeoutTime" BU_SG_REL_ BMS SG_ 1509 CR_Ccm_OutVolt 2000;
BA_REL_ "GenSigTimeoutTime" BU_SG_REL_ BMS SG_ 1509 CR_Ccm_OutCurr 2000;
BA_REL_ "GenSigTimeoutTime" BU_SG_REL_ Dummy SG_ 1511 CR_Ccm_EvseSAID 2000;
BA_REL_ "GenSigTimeoutTime" BU_SG_REL_ Dummy SG_ 1511 CR_Ccm_EvsePmaxID 2000;
BA_REL_ "GenSigTimeoutTime" BU_SG_REL_ Dummy SG_ 1511 CR_Ccm_EvsePmaxEntry 2000;
BA_REL_ "GenSigTimeoutTime" BU_SG_REL_ CGW SG_ 1511 CR_Ccm_EvsePmax 2000;
BA_REL_ "GenSigTimeoutTime" BU_SG_REL_ Dummy SG_ 1511 CR_Ccm_EvsePmax 2000;
BA_REL_ "GenSigTimeoutTime" BU_SG_REL_ vBDM SG_ 1511 CR_Ccm_EvsePmax 2000;
BA_REL_ "GenSigTimeoutTime" BU_SG_REL_ BMS SG_ 1510 CF_Ccm_LogicalNetwork 2000;
BA_REL_ "GenSigTimeoutTime" BU_SG_REL_ BMS SG_ 1510 CF_Ccm_CommClose 2000;
BA_REL_ "GenSigTimeoutTime" BU_SG_REL_ BMS SG_ 1510 CF_Ccm_PwmCheck 2000;
BA_REL_ "GenSigTimeoutTime" BU_SG_REL_ BMS SG_ 1510 CF_Ccm_EvseProc 2000;
BA_REL_ "GenSigTimeoutTime" BU_SG_REL_ BMS SG_ 1510 CF_Ccm_EvseVoltLimit 2000;
BA_REL_ "GenSigTimeoutTime" BU_SG_REL_ BMS SG_ 1510 CF_Ccm_EvsePoweLimit 2000;
BA_REL_ "GenSigTimeoutTime" BU_SG_REL_ BMS SG_ 1510 CF_Ccm_EvseCurrLimit 2000;
BA_REL_ "GenSigTimeoutTime" BU_SG_REL_ BMS SG_ 1510 CF_Ccm_EvseTransferPower 2000;
BA_REL_ "GenSigTimeoutTime" BU_SG_REL_ BMS SG_ 1510 CR_Ccm_EvseNoti 2000;
BA_REL_ "GenSigTimeoutTime" BU_SG_REL_ BMS SG_ 1510 CR_Ccm_EvseIsolStat 2000;
BA_REL_ "GenSigTimeoutTime" BU_SG_REL_ CGW SG_ 1510 CR_Ccm_EvseIsolStat 2000;
BA_REL_ "GenSigTimeoutTime" BU_SG_REL_ vBDM SG_ 1510 CR_Ccm_EvseIsolStat 2000;
BA_REL_ "GenSigTimeoutTime" BU_SG_REL_ BMS SG_ 1510 CR_Ccm_EvseTransferType 2000;
BA_REL_ "GenSigTimeoutTime" BU_SG_REL_ BMS SG_ 1510 CR_Ccm_EvseNotiDly 2000;
BA_REL_ "GenSigTimeoutTime" BU_SG_REL_ BMS SG_ 1510 CR_Ccm_EvsePeakRiple 2000;
BA_REL_ "GenSigTimeoutTime" BU_SG_REL_ BMS SG_ 1510 CR_Ccm_EvseDeliPowe_W 2000;
BA_REL_ "GenSigTimeoutTime" BU_SG_REL_ BMS SG_ 1510 CR_Ccm_EvseMaxPowe_W 2000;
BA_REL_ "GenSigTimeoutTime" BU_SG_REL_ CGW SG_ 1507 CR_VCU_EcoLvl 5000;
BA_REL_ "GenSigTimeoutTime" BU_SG_REL_ TMU SG_ 1507 CR_VCU_EcoLvl 5000;
BA_REL_ "GenSigTimeoutTime" BU_SG_REL_ vBDM SG_ 1507 CR_VCU_EcoLvl 5000;
BA_REL_ "GenSigTimeoutTime" BU_SG_REL_ VCU SG_ 1278 POS_RelativeHeading 2000;
BA_REL_ "GenSigTimeoutTime" BU_SG_REL_ VCU SG_ 1278 POS_RangeAvgSpeed 2000;
BA_REL_ "GenSigTimeoutTime" BU_SG_REL_ VCU SG_ 1278 POS_CurrentLane 2000;
BA_REL_ "GenSigTimeoutTime" BU_SG_REL_ VCU SG_ 1278 POS_PositionConfidence 2000;
BA_REL_ "GenSigTimeoutTime" BU_SG_REL_ VCU SG_ 1278 POS_PositionAge 2000;
BA_REL_ "GenSigTimeoutTime" BU_SG_REL_ VCU SG_ 1278 POS_PositionProbability 2000;
BA_REL_ "GenSigTimeoutTime" BU_SG_REL_ VCU SG_ 1278 POS_PositionIndex 2000;
BA_REL_ "GenSigTimeoutTime" BU_SG_REL_ VCU SG_ 1278 POS_PathIndex 2000;
BA_REL_ "GenSigTimeoutTime" BU_SG_REL_ VCU SG_ 1278 POS_CyclicCounter 2000;
BA_REL_ "GenSigTimeoutTime" BU_SG_REL_ VCU SG_ 1278 POS_Offset 2000;
BA_REL_ "GenSigTimeoutTime" BU_SG_REL_ VCU SG_ 1278 POS_MessageType 2000;
BA_REL_ "GenSigTimeoutTime" BU_SG_REL_ CDM SG_ 1516 C_CtrDrLockRly 1500;
BA_REL_ "GenSigTimeoutTime" BU_SG_REL_ OBC SG_ 1516 C_CtrDrLockRly 1500;
BA_REL_ "GenSigTimeoutTime" BU_SG_REL_ CDM SG_ 1516 C_CtrDrUnlockRly 1500;
BA_REL_ "GenSigTimeoutTime" BU_SG_REL_ OBC SG_ 1516 C_CtrDrUnlockRly 1500;
BA_REL_ "GenSigTimeoutTime" BU_SG_REL_ CDM SG_ 1516 C_DrvDrUnlockRly 1500;
BA_REL_ "GenSigTimeoutTime" BU_SG_REL_ OBC SG_ 1516 C_DrvDrUnlockRly 1500;
BA_REL_ "GenSigTimeoutTime" BU_SG_REL_ OBC SG_ 1516 C_Inlet_ServiceLamp_Req 1500;
BA_REL_ "GenSigTimeoutTime" BU_SG_REL_ VCU SG_ 1516 C_FRECOState 1500;
BA_REL_ "GenSigTimeoutTime" BU_SG_REL_ VCU SG_ 1516 C_DHVSeatOperationFB 1500;
BA_REL_ "GenSigTimeoutTime" BU_SG_REL_ VCU SG_ 1516 C_AHVSeatOperationFB 1500;
BA_REL_ "GenSigTimeoutTime" BU_SG_REL_ VCU SG_ 1516 C_RLHVSeatOperationFB 1500;
BA_REL_ "GenSigTimeoutTime" BU_SG_REL_ VCU SG_ 1516 C_RRHSeatOperationFB 1500;
BA_REL_ "GenSigTimeoutTime" BU_SG_REL_ VCU SG_ 1516 C_RRECOState 1500;
BA_REL_ "GenSigTimeoutTime" BU_SG_REL_ VCU SG_ 1516 C_StrgWhlHeatedState 1500;
BA_REL_ "GenSigTimeoutTime" BU_SG_REL_ VCU SG_ 1516 C_SBRMatSw 1500;
BA_REL_ "GenSigTimeoutTime" BU_SG_REL_ AAF SG_ 1276 CF_Aaf31_ActFlapStatus 1000;
BA_REL_ "GenSigTimeoutTime" BU_SG_REL_ AAF SG_ 1276 CF_Aaf31_ErrStatus 1000;
BA_REL_ "GenSigTimeoutTime" BU_SG_REL_ AAF SG_ 1276 CF_Aaf31_PStatus 1000;
BA_REL_ "GenSigTimeoutTime" BU_SG_REL_ AAF SG_ 1276 CF_Aaf31_PStatusSub 1000;
BA_REL_ "GenSigTimeoutTime" BU_SG_REL_ AAF SG_ 1277 CF_Aaf21_ActFlapStatus 1000;
BA_REL_ "GenSigTimeoutTime" BU_SG_REL_ AAF SG_ 1277 CF_Aaf21_ErrStatus 1000;
BA_REL_ "GenSigTimeoutTime" BU_SG_REL_ AAF SG_ 1277 CF_Aaf21_PStatus 1000;
BA_REL_ "GenSigTimeoutTime" BU_SG_REL_ AAF SG_ 1277 CF_Aaf21_PStatusSub 1000;
BA_REL_ "GenSigTimeoutTime" BU_SG_REL_ BMS SG_ 1513 CF_CCM_NormalOperFlg 2000;
BA_REL_ "GenSigTimeoutTime" BU_SG_REL_ BMS SG_ 1513 CF_CCM_ChgParamFlg 2000;
BA_REL_ "GenSigTimeoutTime" BU_SG_REL_ BMS SG_ 1513 CF_CCM_CableChkFlg 2000;
BA_REL_ "GenSigTimeoutTime" BU_SG_REL_ CGW SG_ 1513 CF_CCM_CableChkFlg 2000;
BA_REL_ "GenSigTimeoutTime" BU_SG_REL_ vBDM SG_ 1513 CF_CCM_CableChkFlg 2000;
BA_REL_ "GenSigTimeoutTime" BU_SG_REL_ BMS SG_ 1513 CF_CCM_PreChgFlg 2000;
BA_REL_ "GenSigTimeoutTime" BU_SG_REL_ BMS SG_ 1513 CF_CCM_PwrDeliOnFlg 2000;
BA_REL_ "GenSigTimeoutTime" BU_SG_REL_ BMS SG_ 1513 CF_CCM_CurDemFlg 2000;
BA_REL_ "GenSigTimeoutTime" BU_SG_REL_ BMS SG_ 1513 CF_CCM_PwrDeliOffFlg 2000;
BA_REL_ "GenSigTimeoutTime" BU_SG_REL_ OBC SG_ 1513 CF_CCM_PwrDeliOffFlg 2000;
BA_REL_ "GenSigTimeoutTime" BU_SG_REL_ BMS SG_ 1513 CF_CCM_WeldDetectFlg 2000;
BA_REL_ "GenSigTimeoutTime" BU_SG_REL_ BMS SG_ 1513 CF_Evse_Mains_Pwr 1500;
BA_REL_ "GenSigTimeoutTime" BU_SG_REL_ CGW SG_ 1513 CF_Evse_Mains_Pwr 1500;
BA_REL_ "GenSigTimeoutTime" BU_SG_REL_ OBC SG_ 1513 CF_Evse_Mains_Pwr 1500;
BA_REL_ "GenSigTimeoutTime" BU_SG_REL_ BMS SG_ 1512 CR_Ccm_EvseCurRegTolerance 2000;
BA_REL_ "GenSigTimeoutTime" BU_SG_REL_ BMS SG_ 1512 CR_Ccm_EvsePmaxInterval 2000;
BA_REL_ "GenSigTimeoutTime" BU_SG_REL_ BMS SG_ 1512 CR_Ccm_MinCurr_A 2000;
BA_REL_ "GenSigTimeoutTime" BU_SG_REL_ BMS SG_ 1512 CR_Ccm_MinVolt_V 2000;
BA_REL_ "GenSigTimeoutTime" BU_SG_REL_ BMS SG_ 1512 CF_Ccm_EvseStatus 2000;
BA_REL_ "GenSigTimeoutTime" BU_SG_REL_ OBC SG_ 1512 CF_Ccm_EvseStatus 2000;
BA_REL_ "GenSigTimeoutTime" BU_SG_REL_ BMS SG_ 1512 CF_Ccm_Error 2000;
BA_REL_ "GenSigTimeoutTime" BU_SG_REL_ BMS SG_ 1512 CF_Ccm_ChgFinished 2000;
BA_REL_ "GenSigTimeoutTime" BU_SG_REL_ CGW SG_ 1512 CF_Ccm_ChgFinished 2000;
BA_REL_ "GenSigTimeoutTime" BU_SG_REL_ OBC SG_ 1512 CF_Ccm_ChgFinished 2000;
BA_REL_ "GenSigTimeoutTime" BU_SG_REL_ vBDM SG_ 1512 CF_Ccm_ChgFinished 2000;
BA_REL_ "GenSigTimeoutTime" BU_SG_REL_ BMS SG_ 1512 CF_Evse_ChgFinished 2000;
BA_REL_ "GenSigTimeoutTime" BU_SG_REL_ OBC SG_ 1512 CF_Evse_ChgFinished 2000;
BA_REL_ "GenSigTimeoutTime" BU_SG_REL_ DATC SG_ 1426 CF_Vcu_DefrostCtr 2000;
BA_REL_ "GenSigTimeoutTime" BU_SG_REL_ TMU SG_ 1426 CF_Vcu_DefrostCtr 2000;
BA_REL_ "GenSigTimeoutTime" BU_SG_REL_ CGW SG_ 1426 CF_Vcu_LowSocLp 2000;
BA_REL_ "GenSigTimeoutTime" BU_SG_REL_ TMU SG_ 1426 CF_Vcu_LowSocLp 2000;
BA_REL_ "GenSigTimeoutTime" BU_SG_REL_ CGW SG_ 1426 CF_Vcu_DteOff 2000;
BA_REL_ "GenSigTimeoutTime" BU_SG_REL_ TMU SG_ 1426 CF_Vcu_DteOff 2000;
BA_REL_ "GenSigTimeoutTime" BU_SG_REL_ CGW SG_ 1426 CF_Vcu_SerLamp 2000;
BA_REL_ "GenSigTimeoutTime" BU_SG_REL_ TMU SG_ 1426 CF_Vcu_SerLamp 2000;
BA_REL_ "GenSigTimeoutTime" BU_SG_REL_ CGW SG_ 1426 CF_Vcu_EcoSco 2000;
BA_REL_ "GenSigTimeoutTime" BU_SG_REL_ TMU SG_ 1426 CF_Vcu_EcoSco 2000;
BA_REL_ "GenSigTimeoutTime" BU_SG_REL_ DATC SG_ 1426 CR_Vcu_ClimatePerm_W 2000;
BA_REL_ "GenSigTimeoutTime" BU_SG_REL_ TMU SG_ 1426 CR_Vcu_ClimatePerm_W 2000;
BA_REL_ "GenSigTimeoutTime" BU_SG_REL_ CGW SG_ 1426 CR_Vcu_FuelEco_KP100km 2000;
BA_REL_ "GenSigTimeoutTime" BU_SG_REL_ TMU SG_ 1426 CR_Vcu_FuelEco_KP100km 2000;
BA_REL_ "GenSigTimeoutTime" BU_SG_REL_ CGW SG_ 1426 CR_Vcu_FatcCst 2000;
BA_REL_ "GenSigTimeoutTime" BU_SG_REL_ CGW SG_ 1426 CF_Vcu_ChrgAlert 2000;
BA_REL_ "GenSigTimeoutTime" BU_SG_REL_ TMU SG_ 1426 CF_Vcu_ChrgAlert 2000;
BA_REL_ "GenSigTimeoutTime" BU_SG_REL_ CGW SG_ 1426 CF_Vcu_PwrDnMode 2000;
BA_REL_ "GenSigTimeoutTime" BU_SG_REL_ TMU SG_ 1426 CF_Vcu_PwrDnMode 2000;
BA_REL_ "GenSigTimeoutTime" BU_SG_REL_ vBDM SG_ 1426 CF_Vcu_PwrDnMode 2000;
BA_REL_ "GenSigTimeoutTime" BU_SG_REL_ CGW SG_ 1426 CF_Vcu_CruOnLamp 2000;
BA_REL_ "GenSigTimeoutTime" BU_SG_REL_ TMU SG_ 1426 CF_Vcu_CruOnLamp 2000;
BA_REL_ "GenSigTimeoutTime" BU_SG_REL_ CGW SG_ 1426 CF_Vcu_CruSetLamp 2000;
BA_REL_ "GenSigTimeoutTime" BU_SG_REL_ TMU SG_ 1426 CF_Vcu_CruSetLamp 2000;
BA_REL_ "GenSigTimeoutTime" BU_SG_REL_ CGW SG_ 1426 CF_Vcu_ThiBatTir 2000;
BA_REL_ "GenSigTimeoutTime" BU_SG_REL_ TMU SG_ 1426 CF_Vcu_ThiBatTir 2000;
BA_REL_ "GenSigTimeoutTime" BU_SG_REL_ CGW SG_ 1426 CF_Vcu_LdcMod 2000;
BA_REL_ "GenSigTimeoutTime" BU_SG_REL_ LDC SG_ 1426 CF_Vcu_LdcMod 2000;
BA_REL_ "GenSigTimeoutTime" BU_SG_REL_ TMU SG_ 1426 CF_Vcu_LdcMod 2000;
BA_REL_ "GenSigTimeoutTime" BU_SG_REL_ CGW SG_ 1426 CF_Vcu_ACnChr 2000;
BA_REL_ "GenSigTimeoutTime" BU_SG_REL_ TMU SG_ 1426 CF_Vcu_ACnChr 2000;
BA_REL_ "GenSigTimeoutTime" BU_SG_REL_ CGW SG_ 1426 CR_Vcu_TqMotClu_Pc 2000;
BA_REL_ "GenSigTimeoutTime" BU_SG_REL_ TMU SG_ 1426 CR_Vcu_TqMotClu_Pc 2000;
BA_REL_ "GenSigTimeoutTime" BU_SG_REL_ CGW SG_ 1426 CR_Vcu_FuelEco_KPK 2000;
BA_REL_ "GenSigTimeoutTime" BU_SG_REL_ LDC SG_ 1426 CR_Vcu_FuelEco_KPK 2000;
BA_REL_ "GenSigTimeoutTime" BU_SG_REL_ TMU SG_ 1426 CR_Vcu_FuelEco_KPK 2000;
BA_REL_ "GenSigTimeoutTime" BU_SG_REL_ CGW SG_ 1426 CF_Vcu_LdcInh 2000;
BA_REL_ "GenSigTimeoutTime" BU_SG_REL_ LDC SG_ 1426 CF_Vcu_LdcInh 2000;
BA_REL_ "GenSigTimeoutTime" BU_SG_REL_ TMU SG_ 1426 CF_Vcu_LdcInh 2000;
BA_REL_ "GenSigTimeoutTime" BU_SG_REL_ CGW SG_ 1426 CF_Vcu_BrkLpReq 2000;
BA_REL_ "GenSigTimeoutTime" BU_SG_REL_ TMU SG_ 1426 CF_Vcu_BrkLpReq 2000;
BA_REL_ "GenSigTimeoutTime" BU_SG_REL_ iBAU SG_ 1426 CF_Vcu_BrkLpReq 2000;
BA_REL_ "GenSigTimeoutTime" BU_SG_REL_ CGW SG_ 1426 CF_Vcu_EvMod 2000;
BA_REL_ "GenSigTimeoutTime" BU_SG_REL_ DATC SG_ 1426 CF_Vcu_EvMod 2000;
BA_REL_ "GenSigTimeoutTime" BU_SG_REL_ NEMS SG_ 1426 CF_Vcu_EvMod 2000;
BA_REL_ "GenSigTimeoutTime" BU_SG_REL_ TMU SG_ 1426 CF_Vcu_EvMod 2000;
BA_REL_ "GenSigTimeoutTime" BU_SG_REL_ VESS SG_ 1426 CF_Vcu_EvMod 2000;
BA_REL_ "GenSigTimeoutTime" BU_SG_REL_ iBAU SG_ 1426 CF_Vcu_EvMod 2000;
BA_REL_ "GenSigTimeoutTime" BU_SG_REL_ CGW SG_ 1426 CF_Vcu_PgmRun5 2000;
BA_REL_ "GenSigTimeoutTime" BU_SG_REL_ TMU SG_ 1426 CF_Vcu_PgmRun5 2000;
BA_REL_ "GenSigTimeoutTime" BU_SG_REL_ CGW SG_ 1427 TPMS_W_LAMP 2000;
BA_REL_ "GenSigTimeoutTime" BU_SG_REL_ H_U SG_ 1427 TPMS_W_LAMP 2000;
BA_REL_ "GenSigTimeoutTime" BU_SG_REL_ TMU SG_ 1427 TPMS_W_LAMP 2000;
BA_REL_ "GenSigTimeoutTime" BU_SG_REL_ vBDM SG_ 1427 TPMS_W_LAMP 2000;
BA_REL_ "GenSigTimeoutTime" BU_SG_REL_ CGW SG_ 1427 TREAD_W_LAMP 2000;
BA_REL_ "GenSigTimeoutTime" BU_SG_REL_ H_U SG_ 1427 TREAD_W_LAMP 2000;
BA_REL_ "GenSigTimeoutTime" BU_SG_REL_ TMU SG_ 1427 TREAD_W_LAMP 2000;
BA_REL_ "GenSigTimeoutTime" BU_SG_REL_ CGW SG_ 1427 POS_FL_W_LAMP 2000;
BA_REL_ "GenSigTimeoutTime" BU_SG_REL_ H_U SG_ 1427 POS_FL_W_LAMP 2000;
BA_REL_ "GenSigTimeoutTime" BU_SG_REL_ TMU SG_ 1427 POS_FL_W_LAMP 2000;
BA_REL_ "GenSigTimeoutTime" BU_SG_REL_ CGW SG_ 1427 POS_FR_W_LAMP 2000;
BA_REL_ "GenSigTimeoutTime" BU_SG_REL_ H_U SG_ 1427 POS_FR_W_LAMP 2000;
BA_REL_ "GenSigTimeoutTime" BU_SG_REL_ TMU SG_ 1427 POS_FR_W_LAMP 2000;
BA_REL_ "GenSigTimeoutTime" BU_SG_REL_ CGW SG_ 1427 POS_RL_W_LAMP 2000;
BA_REL_ "GenSigTimeoutTime" BU_SG_REL_ H_U SG_ 1427 POS_RL_W_LAMP 2000;
BA_REL_ "GenSigTimeoutTime" BU_SG_REL_ TMU SG_ 1427 POS_RL_W_LAMP 2000;
BA_REL_ "GenSigTimeoutTime" BU_SG_REL_ CGW SG_ 1427 POS_RR_W_LAMP 2000;
BA_REL_ "GenSigTimeoutTime" BU_SG_REL_ H_U SG_ 1427 POS_RR_W_LAMP 2000;
BA_REL_ "GenSigTimeoutTime" BU_SG_REL_ TMU SG_ 1427 POS_RR_W_LAMP 2000;
BA_REL_ "GenSigTimeoutTime" BU_SG_REL_ ESC SG_ 1427 STATUS_TPMS 2000;
BA_REL_ "GenSigTimeoutTime" BU_SG_REL_ IBOX SG_ 1427 STATUS_TPMS 2000;
BA_REL_ "GenSigTimeoutTime" BU_SG_REL_ ICSC SG_ 1427 STATUS_TPMS 2000;
BA_REL_ "GenSigTimeoutTime" BU_SG_REL_ CGW SG_ 1427 STATUS_TPMS 2000;
BA_REL_ "GenSigTimeoutTime" BU_SG_REL_ IBOX SG_ 1427 UNIT 2000;
BA_REL_ "GenSigTimeoutTime" BU_SG_REL_ CGW SG_ 1427 UNIT 2000;
BA_REL_ "GenSigTimeoutTime" BU_SG_REL_ IBOX SG_ 1427 PRESSURE_FL 2000;
BA_REL_ "GenSigTimeoutTime" BU_SG_REL_ CGW SG_ 1427 PRESSURE_FL 2000;
BA_REL_ "GenSigTimeoutTime" BU_SG_REL_ IBOX SG_ 1427 PRESSURE_FR 2000;
BA_REL_ "GenSigTimeoutTime" BU_SG_REL_ CGW SG_ 1427 PRESSURE_FR 2000;
BA_REL_ "GenSigTimeoutTime" BU_SG_REL_ IBOX SG_ 1427 PRESSURE_RL 2000;
BA_REL_ "GenSigTimeoutTime" BU_SG_REL_ CGW SG_ 1427 PRESSURE_RL 2000;
BA_REL_ "GenSigTimeoutTime" BU_SG_REL_ IBOX SG_ 1427 PRESSURE_RR 2000;
BA_REL_ "GenSigTimeoutTime" BU_SG_REL_ CGW SG_ 1427 PRESSURE_RR 2000;
BA_REL_ "GenSigTimeoutTime" BU_SG_REL_ TMU SG_ 1424 CF_Ldc_Rdy 2000;
BA_REL_ "GenSigTimeoutTime" BU_SG_REL_ VCU SG_ 1424 CF_Ldc_Rdy 2000;
BA_REL_ "GenSigTimeoutTime" BU_SG_REL_ TMU SG_ 1424 CF_Ldc_Controllable 2000;
BA_REL_ "GenSigTimeoutTime" BU_SG_REL_ VCU SG_ 1424 CF_Ldc_Controllable 2000;
BA_REL_ "GenSigTimeoutTime" BU_SG_REL_ CGW SG_ 1424 CF_Ldc_12VCharge 2000;
BA_REL_ "GenSigTimeoutTime" BU_SG_REL_ NEMS SG_ 1424 CF_Ldc_12VCharge 2000;
BA_REL_ "GenSigTimeoutTime" BU_SG_REL_ TMU SG_ 1424 CF_Ldc_12VCharge 2000;
BA_REL_ "GenSigTimeoutTime" BU_SG_REL_ VCU SG_ 1424 CF_Ldc_12VCharge 2000;
BA_REL_ "GenSigTimeoutTime" BU_SG_REL_ CGW SG_ 1424 CF_Ldc_Pd_Stat 2000;
BA_REL_ "GenSigTimeoutTime" BU_SG_REL_ MCU SG_ 1424 CF_Ldc_Pd_Stat 2000;
BA_REL_ "GenSigTimeoutTime" BU_SG_REL_ NEMS SG_ 1424 CF_Ldc_Pd_Stat 2000;
BA_REL_ "GenSigTimeoutTime" BU_SG_REL_ TMU SG_ 1424 CF_Ldc_Pd_Stat 2000;
BA_REL_ "GenSigTimeoutTime" BU_SG_REL_ VCU SG_ 1424 CF_Ldc_Pd_Stat 2000;
BA_REL_ "GenSigTimeoutTime" BU_SG_REL_ CGW SG_ 1424 CF_Ldc_AuxBatWrnLamp 2000;
BA_REL_ "GenSigTimeoutTime" BU_SG_REL_ TMU SG_ 1424 CF_Ldc_AuxBatWrnLamp 2000;
BA_REL_ "GenSigTimeoutTime" BU_SG_REL_ CGW SG_ 1424 CF_Ldc_AuxBatWrnAlarm 2000;
BA_REL_ "GenSigTimeoutTime" BU_SG_REL_ TMU SG_ 1424 CF_Ldc_AuxBatWrnAlarm 2000;
BA_REL_ "GenSigTimeoutTime" BU_SG_REL_ TMU SG_ 1424 CF_Ldc_AuxBatCharge_Rqst 2000;
BA_REL_ "GenSigTimeoutTime" BU_SG_REL_ VCU SG_ 1424 CF_Ldc_AuxBatCharge_Rqst 2000;
BA_REL_ "GenSigTimeoutTime" BU_SG_REL_ TMU SG_ 1424 CF_Ldc_AuxBatCharge_Reset 2000;
BA_REL_ "GenSigTimeoutTime" BU_SG_REL_ VCU SG_ 1424 CF_Ldc_AuxBatCharge_Reset 2000;
BA_REL_ "GenSigTimeoutTime" BU_SG_REL_ CGW SG_ 1424 CF_Ldc_Srvlamp_Rqst 2000;
BA_REL_ "GenSigTimeoutTime" BU_SG_REL_ H_U SG_ 1424 CF_Ldc_Srvlamp_Rqst 2000;
BA_REL_ "GenSigTimeoutTime" BU_SG_REL_ TMU SG_ 1424 CF_Ldc_Srvlamp_Rqst 2000;
BA_REL_ "GenSigTimeoutTime" BU_SG_REL_ vBDM SG_ 1424 CF_Ldc_Srvlamp_Rqst 2000;
BA_REL_ "GenSigTimeoutTime" BU_SG_REL_ AAF SG_ 1424 CF_Ldc_Flt 2000;
BA_REL_ "GenSigTimeoutTime" BU_SG_REL_ BMS SG_ 1424 CF_Ldc_Flt 2000;
BA_REL_ "GenSigTimeoutTime" BU_SG_REL_ CGW SG_ 1424 CF_Ldc_Flt 2000;
BA_REL_ "GenSigTimeoutTime" BU_SG_REL_ H_U SG_ 1424 CF_Ldc_Flt 2000;
BA_REL_ "GenSigTimeoutTime" BU_SG_REL_ MCU SG_ 1424 CF_Ldc_Flt 2000;
BA_REL_ "GenSigTimeoutTime" BU_SG_REL_ NEMS SG_ 1424 CF_Ldc_Flt 2000;
BA_REL_ "GenSigTimeoutTime" BU_SG_REL_ OBC SG_ 1424 CF_Ldc_Flt 2000;
BA_REL_ "GenSigTimeoutTime" BU_SG_REL_ TMU SG_ 1424 CF_Ldc_Flt 2000;
BA_REL_ "GenSigTimeoutTime" BU_SG_REL_ VCU SG_ 1424 CF_Ldc_Flt 2000;
BA_REL_ "GenSigTimeoutTime" BU_SG_REL_ BMS SG_ 1424 CF_Ldc_AuxBatChg_State 2000;
BA_REL_ "GenSigTimeoutTime" BU_SG_REL_ CGW SG_ 1424 CF_Ldc_AuxBatChg_State 2000;
BA_REL_ "GenSigTimeoutTime" BU_SG_REL_ EMS SG_ 1424 CF_Ldc_RadFanCnt 2000;
BA_REL_ "GenSigTimeoutTime" BU_SG_REL_ MCU SG_ 1424 CF_Ldc_RadFanCnt 2000;
BA_REL_ "GenSigTimeoutTime" BU_SG_REL_ TMU SG_ 1424 CF_Ldc_RadFanCnt 2000;
BA_REL_ "GenSigTimeoutTime" BU_SG_REL_ CGW SG_ 1424 CF_Ldc_Bat_dischrg 2000;
BA_REL_ "GenSigTimeoutTime" BU_SG_REL_ MCU SG_ 1424 CR_Ldc_ActCur_LS_A 2000;
BA_REL_ "GenSigTimeoutTime" BU_SG_REL_ TMU SG_ 1424 CR_Ldc_ActCur_LS_A 2000;
BA_REL_ "GenSigTimeoutTime" BU_SG_REL_ MCU SG_ 1424 CR_Ldc_RadFanReq_Duty 2000;
BA_REL_ "GenSigTimeoutTime" BU_SG_REL_ TMU SG_ 1424 CR_Ldc_RadFanReq_Duty 2000;
BA_REL_ "GenSigTimeoutTime" BU_SG_REL_ VCU SG_ 1424 CR_Ldc_RadFanReq_Duty 2000;
BA_REL_ "GenSigTimeoutTime" BU_SG_REL_ CGW SG_ 1424 CR_Ldc_ActVol_LS_V 2000;
BA_REL_ "GenSigTimeoutTime" BU_SG_REL_ MCU SG_ 1424 CR_Ldc_ActVol_LS_V 2000;
BA_REL_ "GenSigTimeoutTime" BU_SG_REL_ OBC SG_ 1424 CR_Ldc_ActVol_LS_V 2000;
BA_REL_ "GenSigTimeoutTime" BU_SG_REL_ TMU SG_ 1424 CR_Ldc_ActVol_LS_V 2000;
BA_REL_ "GenSigTimeoutTime" BU_SG_REL_ MCU SG_ 1424 CR_Ldc_EWPRpmCnt 2000;
BA_REL_ "GenSigTimeoutTime" BU_SG_REL_ TMU SG_ 1424 CR_Ldc_EWPRpmCnt 2000;
BA_REL_ "GenSigTimeoutTime" BU_SG_REL_ VCU SG_ 1424 CR_Ldc_EWPRpmCnt 2000;
BA_REL_ "GenSigTimeoutTime" BU_SG_REL_ CGW SG_ 1424 CR_Ldc_PwrMon_W 2000;
BA_REL_ "GenSigTimeoutTime" BU_SG_REL_ TMU SG_ 1424 CR_Ldc_PwrMon_W 2000;
BA_REL_ "GenSigTimeoutTime" BU_SG_REL_ VCU SG_ 1424 CR_Ldc_PwrMon_W 2000;
BA_REL_ "GenSigTimeoutTime" BU_SG_REL_ AAF SG_ 1424 CR_Ldc_Tmp 2000;
BA_REL_ "GenSigTimeoutTime" BU_SG_REL_ TMU SG_ 1424 CR_Ldc_Tmp 2000;
BA_REL_ "GenSigTimeoutTime" BU_SG_REL_ VCU SG_ 1424 CR_Ldc_Tmp 2000;
BA_REL_ "GenSigTimeoutTime" BU_SG_REL_ BMS SG_ 1019 CF_Cms_PDStatus 2000;
BA_REL_ "GenSigTimeoutTime" BU_SG_REL_ CCM SG_ 1019 CF_Cms_PDStatus 2000;
BA_REL_ "GenSigTimeoutTime" BU_SG_REL_ OBC SG_ 1019 CF_Cms_PDStatus 2000;
BA_REL_ "GenSigTimeoutTime" BU_SG_REL_ BMS SG_ 1019 CF_Cms_ChgFinished 2000;
BA_REL_ "GenSigTimeoutTime" BU_SG_REL_ CCM SG_ 1019 CF_Cms_ChgFinished 2000;
BA_REL_ "GenSigTimeoutTime" BU_SG_REL_ OBC SG_ 1019 CF_Cms_ChgFinished 2000;
BA_REL_ "GenSigTimeoutTime" BU_SG_REL_ BMS SG_ 1019 CF_Cms_EvseRdyState 2000;
BA_REL_ "GenSigTimeoutTime" BU_SG_REL_ CCM SG_ 1019 CF_Cms_EvseRdyState 2000;
BA_REL_ "GenSigTimeoutTime" BU_SG_REL_ OBC SG_ 1019 CF_Cms_EvseRdyState 2000;
BA_REL_ "GenSigTimeoutTime" BU_SG_REL_ BMS SG_ 1019 CF_Cms_Wrn 2000;
BA_REL_ "GenSigTimeoutTime" BU_SG_REL_ CCM SG_ 1019 CF_Cms_Wrn 2000;
BA_REL_ "GenSigTimeoutTime" BU_SG_REL_ OBC SG_ 1019 CF_Cms_Wrn 2000;
BA_REL_ "GenSigTimeoutTime" BU_SG_REL_ BMS SG_ 1019 CF_Cms_Flt 2000;
BA_REL_ "GenSigTimeoutTime" BU_SG_REL_ CCM SG_ 1019 CF_Cms_Flt 2000;
BA_REL_ "GenSigTimeoutTime" BU_SG_REL_ OBC SG_ 1019 CF_Cms_Flt 2000;
BA_REL_ "GenSigTimeoutTime" BU_SG_REL_ BMS SG_ 1019 CF_Cms_Rdy 2000;
BA_REL_ "GenSigTimeoutTime" BU_SG_REL_ CCM SG_ 1019 CF_Cms_Rdy 2000;
BA_REL_ "GenSigTimeoutTime" BU_SG_REL_ OBC SG_ 1019 CF_Cms_Rdy 2000;
BA_REL_ "GenSigTimeoutTime" BU_SG_REL_ BMS SG_ 1019 CF_Cms_IG3DrvStat 2000;
BA_REL_ "GenSigTimeoutTime" BU_SG_REL_ CCM SG_ 1019 CF_Cms_IG3DrvStat 2000;
BA_REL_ "GenSigTimeoutTime" BU_SG_REL_ OBC SG_ 1019 CF_Cms_IG3DrvStat 2000;
BA_REL_ "GenSigTimeoutTime" BU_SG_REL_ BMS SG_ 1019 CF_Cms_PlugConnect 2000;
BA_REL_ "GenSigTimeoutTime" BU_SG_REL_ CCM SG_ 1019 CF_Cms_PlugConnect 2000;
BA_REL_ "GenSigTimeoutTime" BU_SG_REL_ OBC SG_ 1019 CF_Cms_PlugConnect 2000;
BA_REL_ "GenSigTimeoutTime" BU_SG_REL_ BMS SG_ 1019 CF_Cms_S2SWOnStat 2000;
BA_REL_ "GenSigTimeoutTime" BU_SG_REL_ CCM SG_ 1019 CF_Cms_S2SWOnStat 2000;
BA_REL_ "GenSigTimeoutTime" BU_SG_REL_ OBC SG_ 1019 CF_Cms_S2SWOnStat 2000;
BA_REL_ "GenSigTimeoutTime" BU_SG_REL_ MCU SG_ 1019 CF_Cms_ForcedDischReq 2000;
BA_REL_ "GenSigTimeoutTime" BU_SG_REL_ BMS SG_ 1019 CF_Cms_MILReq 2000;
BA_REL_ "GenSigTimeoutTime" BU_SG_REL_ CCM SG_ 1019 CF_Cms_MILReq 2000;
BA_REL_ "GenSigTimeoutTime" BU_SG_REL_ OBC SG_ 1019 CF_Cms_MILReq 2000;
BA_REL_ "GenSigTimeoutTime" BU_SG_REL_ CGW SG_ 1019 CF_Cms_VCRM_Req 2000;
BA_REL_ "GenSigTimeoutTime" BU_SG_REL_ H_U SG_ 1019 CF_Cms_VCRM_Req 2000;
BA_REL_ "GenSigTimeoutTime" BU_SG_REL_ vBDM SG_ 1019 CF_Cms_VCRM_Req 2000;
BA_REL_ "GenSigTimeoutTime" BU_SG_REL_ CGW SG_ 1019 CF_Cms_ServiceLampReq 2000;
BA_REL_ "GenSigTimeoutTime" BU_SG_REL_ H_U SG_ 1019 CF_Cms_ServiceLampReq 2000;
BA_REL_ "GenSigTimeoutTime" BU_SG_REL_ CCM SG_ 1019 CF_Cms_EvseFltStat 2000;
BA_REL_ "GenSigTimeoutTime" BU_SG_REL_ BMS SG_ 1019 CF_Cms_DCChargingStat 2000;
BA_REL_ "GenSigTimeoutTime" BU_SG_REL_ CCM SG_ 1019 CF_Cms_DCChargingStat 2000;
BA_REL_ "GenSigTimeoutTime" BU_SG_REL_ OBC SG_ 1019 CF_Cms_DCChargingStat 2000;
BA_REL_ "GenSigTimeoutTime" BU_SG_REL_ BMS SG_ 1019 CF_Cms_ACChargingStat 2000;
BA_REL_ "GenSigTimeoutTime" BU_SG_REL_ CCM SG_ 1019 CF_Cms_ACChargingStat 2000;
BA_REL_ "GenSigTimeoutTime" BU_SG_REL_ OBC SG_ 1019 CF_Cms_ACChargingStat 2000;
BA_REL_ "GenSigTimeoutTime" BU_SG_REL_ VCU SG_ 1019 CF_Cms_ImmeChgSwState 2000;
BA_REL_ "GenSigTimeoutTime" BU_SG_REL_ BMS SG_ 1019 CF_Cms_ChargeInit 2000;
BA_REL_ "GenSigTimeoutTime" BU_SG_REL_ CCM SG_ 1019 CF_Cms_ChargeInit 2000;
BA_REL_ "GenSigTimeoutTime" BU_SG_REL_ OBC SG_ 1019 CF_Cms_ChargeInit 2000;
BA_REL_ "GenSigTimeoutTime" BU_SG_REL_ BMS SG_ 1019 CF_Cms_ChargingCycle 2000;
BA_REL_ "GenSigTimeoutTime" BU_SG_REL_ CCM SG_ 1019 CF_Cms_ChargingCycle 2000;
BA_REL_ "GenSigTimeoutTime" BU_SG_REL_ OBC SG_ 1019 CF_Cms_ChargingCycle 2000;
BA_REL_ "GenSigTimeoutTime" BU_SG_REL_ BMS SG_ 1020 CF_Cms_ChgStopAlarm 2000;
BA_REL_ "GenSigTimeoutTime" BU_SG_REL_ CCM SG_ 1020 CF_Cms_ChgStopAlarm 2000;
BA_REL_ "GenSigTimeoutTime" BU_SG_REL_ OBC SG_ 1020 CF_Cms_ChgStopAlarm 2000;
BA_REL_ "GenSigTimeoutTime" BU_SG_REL_ CCM SG_ 1020 CF_Cms_PlcCpFlt 2000;
BA_REL_ "GenSigTimeoutTime" BU_SG_REL_ OBC SG_ 1020 CF_Cms_PlcCpFlt 2000;
BA_REL_ "GenSigTimeoutTime" BU_SG_REL_ BMS SG_ 1020 CF_Cms_CPDutyFloat 0;
BA_REL_ "GenSigTimeoutTime" BU_SG_REL_ CCM SG_ 1020 CF_Cms_CPDutyFloat 0;
BA_REL_ "GenSigTimeoutTime" BU_SG_REL_ OBC SG_ 1020 CF_Cms_CPDutyFloat 0;
BA_REL_ "GenSigTimeoutTime" BU_SG_REL_ BMS SG_ 1020 CR_Cms_CPVolt 2000;
BA_REL_ "GenSigTimeoutTime" BU_SG_REL_ CCM SG_ 1020 CR_Cms_CPVolt 2000;
BA_REL_ "GenSigTimeoutTime" BU_SG_REL_ OBC SG_ 1020 CR_Cms_CPVolt 2000;
BA_REL_ "GenSigTimeoutTime" BU_SG_REL_ CGW SG_ 1430 CF_Bms_Diag_Group 2000;
BA_REL_ "GenSigTimeoutTime" BU_SG_REL_ DATC SG_ 1430 CF_Bms_Diag_Group 2000;
BA_REL_ "GenSigTimeoutTime" BU_SG_REL_ TMU SG_ 1430 CF_Bms_Diag_Group 2000;
BA_REL_ "GenSigTimeoutTime" BU_SG_REL_ VCU SG_ 1430 CF_Bms_Diag_Group 2000;
BA_REL_ "GenSigTimeoutTime" BU_SG_REL_ vBDM SG_ 1430 CF_Bms_Diag_Group 2000;
BA_REL_ "GenSigTimeoutTime" BU_SG_REL_ CGW SG_ 1430 CF_Bms_Diag_Monitor 2000;
BA_REL_ "GenSigTimeoutTime" BU_SG_REL_ TMU SG_ 1430 CF_Bms_Diag_Monitor 2000;
BA_REL_ "GenSigTimeoutTime" BU_SG_REL_ VCU SG_ 1430 CF_Bms_Diag_Monitor 2000;
BA_REL_ "GenSigTimeoutTime" BU_SG_REL_ CGW SG_ 1430 CR_Bms_ChgRemainedTime_min 2000;
BA_REL_ "GenSigTimeoutTime" BU_SG_REL_ TMU SG_ 1430 CR_Bms_ChgRemainedTime_min 2000;
BA_REL_ "GenSigTimeoutTime" BU_SG_REL_ CGW SG_ 1430 CR_Bms_QcChgRemainedTime_min 2000;
BA_REL_ "GenSigTimeoutTime" BU_SG_REL_ TMU SG_ 1430 CR_Bms_QcChgRemainedTime_min 2000;
BA_REL_ "GenSigTimeoutTime" BU_SG_REL_ CGW SG_ 1430 CR_Bms_BatMinTemp_C 2000;
BA_REL_ "GenSigTimeoutTime" BU_SG_REL_ TMU SG_ 1430 CR_Bms_BatMinTemp_C 2000;
BA_REL_ "GenSigTimeoutTime" BU_SG_REL_ VCU SG_ 1430 CR_Bms_BatMinTemp_C 2000;
BA_REL_ "GenSigTimeoutTime" BU_SG_REL_ AAF SG_ 1430 CR_Bms_BatMaxTemp_C 2000;
BA_REL_ "GenSigTimeoutTime" BU_SG_REL_ CGW SG_ 1430 CR_Bms_BatMaxTemp_C 2000;
BA_REL_ "GenSigTimeoutTime" BU_SG_REL_ TMU SG_ 1430 CR_Bms_BatMaxTemp_C 2000;
BA_REL_ "GenSigTimeoutTime" BU_SG_REL_ VCU SG_ 1430 CR_Bms_BatMaxTemp_C 2000;
BA_REL_ "GenSigTimeoutTime" BU_SG_REL_ CGW SG_ 1021 LVA_CLU 0;
BA_REL_ "GenSigTimeoutTime" BU_SG_REL_ OBC SG_ 1431 CF_BMS_RdyForOBC 2000;
BA_REL_ "GenSigTimeoutTime" BU_SG_REL_ OBC SG_ 1431 CF_BMS_FltForOBC 2000;
BA_REL_ "GenSigTimeoutTime" BU_SG_REL_ OBC SG_ 1431 CF_BMS_MainRlyONstatForOBC 2000;
BA_REL_ "GenSigTimeoutTime" BU_SG_REL_ CGW SG_ 1431 CF_BMS_ChgFinishedForOBC 2000;
BA_REL_ "GenSigTimeoutTime" BU_SG_REL_ OBC SG_ 1431 CF_BMS_ChgFinishedForOBC 2000;
BA_REL_ "GenSigTimeoutTime" BU_SG_REL_ TMU SG_ 1431 CF_BMS_ChgFinishedForOBC 2000;
BA_REL_ "GenSigTimeoutTime" BU_SG_REL_ vBDM SG_ 1431 CF_BMS_ChgFinishedForOBC 2000;
BA_REL_ "GenSigTimeoutTime" BU_SG_REL_ OBC SG_ 1431 CF_BMS_ChgFullForOBC 2000;
BA_REL_ "GenSigTimeoutTime" BU_SG_REL_ OBC SG_ 1431 CF_Bms_TargetSocFullChg 2000;
BA_REL_ "GenSigTimeoutTime" BU_SG_REL_ VCU SG_ 1431 CF_Bms_TargetSocFullChg 2000;
BA_REL_ "GenSigTimeoutTime" BU_SG_REL_ CCM SG_ 1431 CF_Bms_NormalOperFlg 2000;
BA_REL_ "GenSigTimeoutTime" BU_SG_REL_ OBC SG_ 1431 CF_Bms_NormalOperFlg 2000;
BA_REL_ "GenSigTimeoutTime" BU_SG_REL_ CGW SG_ 1431 CR_Bms_ScChgRemainedTime_min 2000;
BA_REL_ "GenSigTimeoutTime" BU_SG_REL_ TMU SG_ 1431 CR_Bms_ScChgRemainedTime_min 2000;
BA_REL_ "GenSigTimeoutTime" BU_SG_REL_ OBC SG_ 1431 CR_Bms_ObcCmdVolt_V 2000;
BA_REL_ "GenSigTimeoutTime" BU_SG_REL_ OBC SG_ 1431 CR_Bms_ObcCmdCurrt_A 2000;
BA_REL_ "GenSigTimeoutTime" BU_SG_REL_ CDM SG_ 1431 CF_Bms_ChgLamp 2000;
BA_REL_ "GenSigTimeoutTime" BU_SG_REL_ Dummy SG_ 1431 CF_Bms_ChgLamp 2000;
BA_REL_ "GenSigTimeoutTime" BU_SG_REL_ OBC SG_ 1431 CF_Bms_SupplyChg 2000;
BA_REL_ "GenSigTimeoutTime" BU_SG_REL_ CGW SG_ 1431 CF_BMS_NormalChgForOBC 2000;
BA_REL_ "GenSigTimeoutTime" BU_SG_REL_ OBC SG_ 1431 CF_BMS_NormalChgForOBC 2000;
BA_REL_ "GenSigTimeoutTime" BU_SG_REL_ TMU SG_ 1431 CF_BMS_NormalChgForOBC 2000;
BA_REL_ "GenSigTimeoutTime" BU_SG_REL_ VCU SG_ 1431 CF_BMS_NormalChgForOBC 2000;
BA_REL_ "GenSigTimeoutTime" BU_SG_REL_ CDM SG_ 1431 CF_Bms_IG3RlyOffEnable 2000;
BA_REL_ "GenSigTimeoutTime" BU_SG_REL_ OBC SG_ 1431 CF_Bms_IG3RlyOffEnable 2000;
BA_REL_ "GenSigTimeoutTime" BU_SG_REL_ OBC SG_ 1022 CR_Cms_ObcCmdOutVolt 2000;
BA_REL_ "GenSigTimeoutTime" BU_SG_REL_ OBC SG_ 1022 CR_Cms_ObcCmdOutCur 2000;
BA_REL_ "GenSigTimeoutTime" BU_SG_REL_ OBC SG_ 1022 CR_Cms_ObcCmdInCur 2000;
BA_REL_ "GenSigTimeoutTime" BU_SG_REL_ CCM SG_ 1022 CR_Cms_CpFltStat 2000;
BA_REL_ "GenSigTimeoutTime" BU_SG_REL_ OBC SG_ 1022 CR_Cms_CpFltStat 2000;
BA_REL_ "GenSigTimeoutTime" BU_SG_REL_ CGW SG_ 1428 CR_Bms_BatChaLmt_W 2000;
BA_REL_ "GenSigTimeoutTime" BU_SG_REL_ MCU SG_ 1428 CR_Bms_BatChaLmt_W 2000;
BA_REL_ "GenSigTimeoutTime" BU_SG_REL_ TMU SG_ 1428 CR_Bms_BatChaLmt_W 2000;
BA_REL_ "GenSigTimeoutTime" BU_SG_REL_ VCU SG_ 1428 CR_Bms_BatChaLmt_W 2000;
BA_REL_ "GenSigTimeoutTime" BU_SG_REL_ CGW SG_ 1428 CR_Bms_BatDchLmt_W 2000;
BA_REL_ "GenSigTimeoutTime" BU_SG_REL_ MCU SG_ 1428 CR_Bms_BatDchLmt_W 2000;
BA_REL_ "GenSigTimeoutTime" BU_SG_REL_ TMU SG_ 1428 CR_Bms_BatDchLmt_W 2000;
BA_REL_ "GenSigTimeoutTime" BU_SG_REL_ VCU SG_ 1428 CR_Bms_BatDchLmt_W 2000;
BA_REL_ "GenSigTimeoutTime" BU_SG_REL_ CGW SG_ 1428 CF_Bms_LowtempStatus 2000;
BA_REL_ "GenSigTimeoutTime" BU_SG_REL_ TMU SG_ 1428 CF_Bms_LowtempStatus 2000;
BA_REL_ "GenSigTimeoutTime" BU_SG_REL_ CGW SG_ 1428 CF_Bms_ServiceLamp 2000;
BA_REL_ "GenSigTimeoutTime" BU_SG_REL_ TMU SG_ 1428 CF_Bms_ServiceLamp 2000;
BA_REL_ "GenSigTimeoutTime" BU_SG_REL_ VCU SG_ 1428 CF_Bms_ServiceLamp 2000;
BA_REL_ "GenSigTimeoutTime" BU_SG_REL_ CGW SG_ 1428 CF_Bms_MainRlyOnStat 2000;
BA_REL_ "GenSigTimeoutTime" BU_SG_REL_ DATC SG_ 1428 CF_Bms_MainRlyOnStat 2000;
BA_REL_ "GenSigTimeoutTime" BU_SG_REL_ LDC SG_ 1428 CF_Bms_MainRlyOnStat 2000;
BA_REL_ "GenSigTimeoutTime" BU_SG_REL_ MCU SG_ 1428 CF_Bms_MainRlyOnStat 2000;
BA_REL_ "GenSigTimeoutTime" BU_SG_REL_ TMU SG_ 1428 CF_Bms_MainRlyOnStat 2000;
BA_REL_ "GenSigTimeoutTime" BU_SG_REL_ VCU SG_ 1428 CF_Bms_MainRlyOnStat 2000;
BA_REL_ "GenSigTimeoutTime" BU_SG_REL_ CGW SG_ 1428 CF_Bms_Rly_Off_Req 2000;
BA_REL_ "GenSigTimeoutTime" BU_SG_REL_ TMU SG_ 1428 CF_Bms_Rly_Off_Req 2000;
BA_REL_ "GenSigTimeoutTime" BU_SG_REL_ VCU SG_ 1428 CF_Bms_Rly_Off_Req 2000;
BA_REL_ "GenSigTimeoutTime" BU_SG_REL_ CGW SG_ 1428 CF_Bms_Flt 2000;
BA_REL_ "GenSigTimeoutTime" BU_SG_REL_ DATC SG_ 1428 CF_Bms_Flt 2000;
BA_REL_ "GenSigTimeoutTime" BU_SG_REL_ LDC SG_ 1428 CF_Bms_Flt 2000;
BA_REL_ "GenSigTimeoutTime" BU_SG_REL_ MCU SG_ 1428 CF_Bms_Flt 2000;
BA_REL_ "GenSigTimeoutTime" BU_SG_REL_ TMU SG_ 1428 CF_Bms_Flt 2000;
BA_REL_ "GenSigTimeoutTime" BU_SG_REL_ VCU SG_ 1428 CF_Bms_Flt 2000;
BA_REL_ "GenSigTimeoutTime" BU_SG_REL_ iBAU SG_ 1428 CF_Bms_Flt 2000;
BA_REL_ "GenSigTimeoutTime" BU_SG_REL_ CGW SG_ 1428 CF_Bms_Wrn 2000;
BA_REL_ "GenSigTimeoutTime" BU_SG_REL_ MCU SG_ 1428 CF_Bms_Wrn 2000;
BA_REL_ "GenSigTimeoutTime" BU_SG_REL_ TMU SG_ 1428 CF_Bms_Wrn 2000;
BA_REL_ "GenSigTimeoutTime" BU_SG_REL_ VCU SG_ 1428 CF_Bms_Wrn 2000;
BA_REL_ "GenSigTimeoutTime" BU_SG_REL_ iBAU SG_ 1428 CF_Bms_Wrn 2000;
BA_REL_ "GenSigTimeoutTime" BU_SG_REL_ CGW SG_ 1428 CF_Bms_Ctrb 2000;
BA_REL_ "GenSigTimeoutTime" BU_SG_REL_ LDC SG_ 1428 CF_Bms_Ctrb 2000;
BA_REL_ "GenSigTimeoutTime" BU_SG_REL_ TMU SG_ 1428 CF_Bms_Ctrb 2000;
BA_REL_ "GenSigTimeoutTime" BU_SG_REL_ VCU SG_ 1428 CF_Bms_Ctrb 2000;
BA_REL_ "GenSigTimeoutTime" BU_SG_REL_ CGW SG_ 1428 CF_Bms_Rdy 2000;
BA_REL_ "GenSigTimeoutTime" BU_SG_REL_ MCU SG_ 1428 CF_Bms_Rdy 2000;
BA_REL_ "GenSigTimeoutTime" BU_SG_REL_ TMU SG_ 1428 CF_Bms_Rdy 2000;
BA_REL_ "GenSigTimeoutTime" BU_SG_REL_ VCU SG_ 1428 CF_Bms_Rdy 2000;
BA_REL_ "GenSigTimeoutTime" BU_SG_REL_ CGW SG_ 1428 CR_Bms_Soc_Pc 2000;
BA_REL_ "GenSigTimeoutTime" BU_SG_REL_ H_U SG_ 1428 CR_Bms_Soc_Pc 2000;
BA_REL_ "GenSigTimeoutTime" BU_SG_REL_ LDC SG_ 1428 CR_Bms_Soc_Pc 2000;
BA_REL_ "GenSigTimeoutTime" BU_SG_REL_ MCU SG_ 1428 CR_Bms_Soc_Pc 2000;
BA_REL_ "GenSigTimeoutTime" BU_SG_REL_ OBC SG_ 1428 CR_Bms_Soc_Pc 2000;
BA_REL_ "GenSigTimeoutTime" BU_SG_REL_ TMU SG_ 1428 CR_Bms_Soc_Pc 2000;
BA_REL_ "GenSigTimeoutTime" BU_SG_REL_ VCU SG_ 1428 CR_Bms_Soc_Pc 2000;
BA_REL_ "GenSigTimeoutTime" BU_SG_REL_ iBAU SG_ 1428 CR_Bms_Soc_Pc 2000;
BA_REL_ "GenSigTimeoutTime" BU_SG_REL_ vBDM SG_ 1428 CR_Bms_Soc_Pc 2000;
BA_REL_ "GenSigTimeoutTime" BU_SG_REL_ CGW SG_ 1428 CR_Bms_SocDec_Pc 2000;
BA_REL_ "GenSigTimeoutTime" BU_SG_REL_ TMU SG_ 1428 CR_Bms_SocDec_Pc 2000;
BA_REL_ "GenSigTimeoutTime" BU_SG_REL_ VCU SG_ 1428 CR_Bms_SocDec_Pc 2000;
BA_REL_ "GenSigTimeoutTime" BU_SG_REL_ CGW SG_ 1428 CF_Bms_SupplyChgStat 2000;
BA_REL_ "GenSigTimeoutTime" BU_SG_REL_ TMU SG_ 1428 CF_Bms_SupplyChgStat 2000;
BA_REL_ "GenSigTimeoutTime" BU_SG_REL_ VCU SG_ 1428 CF_Bms_SupplyChgStat 2000;
BA_REL_ "GenSigTimeoutTime" BU_SG_REL_ CGW SG_ 1428 CR_Bms_WinterMode 2000;
BA_REL_ "GenSigTimeoutTime" BU_SG_REL_ TMU SG_ 1428 CR_Bms_WinterMode 2000;
BA_REL_ "GenSigTimeoutTime" BU_SG_REL_ VCU SG_ 1428 CR_Bms_WinterMode 2000;
BA_REL_ "GenSigTimeoutTime" BU_SG_REL_ CGW SG_ 1428 CF_Bms_CshActFromAcu 2000;
BA_REL_ "GenSigTimeoutTime" BU_SG_REL_ LDC SG_ 1428 CF_Bms_CshActFromAcu 2000;
BA_REL_ "GenSigTimeoutTime" BU_SG_REL_ MCU SG_ 1428 CF_Bms_CshActFromAcu 2000;
BA_REL_ "GenSigTimeoutTime" BU_SG_REL_ TMU SG_ 1428 CF_Bms_CshActFromAcu 2000;
BA_REL_ "GenSigTimeoutTime" BU_SG_REL_ VCU SG_ 1428 CF_Bms_CshActFromAcu 2000;
BA_REL_ "GenSigTimeoutTime" BU_SG_REL_ CGW SG_ 1428 CF_Bms_HighTempStatus 2000;
BA_REL_ "GenSigTimeoutTime" BU_SG_REL_ TMU SG_ 1428 CF_Bms_HighTempStatus 2000;
BA_REL_ "GenSigTimeoutTime" BU_SG_REL_ CGW SG_ 1428 CF_Bms_HvIntlockReq 2000;
BA_REL_ "GenSigTimeoutTime" BU_SG_REL_ DATC SG_ 1428 CF_Bms_HvIntlockReq 2000;
BA_REL_ "GenSigTimeoutTime" BU_SG_REL_ LDC SG_ 1428 CF_Bms_HvIntlockReq 2000;
BA_REL_ "GenSigTimeoutTime" BU_SG_REL_ MCU SG_ 1428 CF_Bms_HvIntlockReq 2000;
BA_REL_ "GenSigTimeoutTime" BU_SG_REL_ OBC SG_ 1428 CF_Bms_HvIntlockReq 2000;
BA_REL_ "GenSigTimeoutTime" BU_SG_REL_ TMU SG_ 1428 CF_Bms_HvIntlockReq 2000;
BA_REL_ "GenSigTimeoutTime" BU_SG_REL_ VCU SG_ 1428 CF_Bms_HvIntlockReq 2000;
BA_REL_ "GenSigTimeoutTime" BU_SG_REL_ CGW SG_ 1428 CF_Bms_RlyWeld 2000;
BA_REL_ "GenSigTimeoutTime" BU_SG_REL_ LDC SG_ 1428 CF_Bms_RlyWeld 2000;
BA_REL_ "GenSigTimeoutTime" BU_SG_REL_ MCU SG_ 1428 CF_Bms_RlyWeld 2000;
BA_REL_ "GenSigTimeoutTime" BU_SG_REL_ TMU SG_ 1428 CF_Bms_RlyWeld 2000;
BA_REL_ "GenSigTimeoutTime" BU_SG_REL_ VCU SG_ 1428 CF_Bms_RlyWeld 2000;
BA_REL_ "GenSigTimeoutTime" BU_SG_REL_ MCU SG_ 1428 CF_Bms_ForcedDischgReq 2000;
BA_REL_ "GenSigTimeoutTime" BU_SG_REL_ CGW SG_ 1428 CF_Bms_LdcInh 2000;
BA_REL_ "GenSigTimeoutTime" BU_SG_REL_ LDC SG_ 1428 CF_Bms_LdcInh 2000;
BA_REL_ "GenSigTimeoutTime" BU_SG_REL_ TMU SG_ 1428 CF_Bms_LdcInh 2000;
BA_REL_ "GenSigTimeoutTime" BU_SG_REL_ CGW SG_ 1428 CF_Bms_FulChgSts 2000;
BA_REL_ "GenSigTimeoutTime" BU_SG_REL_ TMU SG_ 1428 CF_Bms_FulChgSts 2000;
BA_REL_ "GenSigTimeoutTime" BU_SG_REL_ AAF SG_ 1428 CF_Bms_ChgSts 2000;
BA_REL_ "GenSigTimeoutTime" BU_SG_REL_ CGW SG_ 1428 CF_Bms_ChgSts 2000;
BA_REL_ "GenSigTimeoutTime" BU_SG_REL_ DATC SG_ 1428 CF_Bms_ChgSts 2000;
BA_REL_ "GenSigTimeoutTime" BU_SG_REL_ LDC SG_ 1428 CF_Bms_ChgSts 2000;
BA_REL_ "GenSigTimeoutTime" BU_SG_REL_ TMU SG_ 1428 CF_Bms_ChgSts 2000;
BA_REL_ "GenSigTimeoutTime" BU_SG_REL_ VCU SG_ 1428 CF_Bms_ChgSts 2000;
BA_REL_ "GenSigTimeoutTime" BU_SG_REL_ CGW SG_ 1023 CR_Bms_Nev_GroupSel 2000;
BA_REL_ "GenSigTimeoutTime" BU_SG_REL_ NEMS SG_ 1023 CR_Bms_Nev_GroupSel 2000;
BA_REL_ "GenSigTimeoutTime" BU_SG_REL_ CGW SG_ 1023 CR_Bms_Nev_StatrNo 2000;
BA_REL_ "GenSigTimeoutTime" BU_SG_REL_ NEMS SG_ 1023 CR_Bms_Nev_StatrNo 2000;
BA_REL_ "GenSigTimeoutTime" BU_SG_REL_ CGW SG_ 1023 CR_Bms_Nev_Info1 2000;
BA_REL_ "GenSigTimeoutTime" BU_SG_REL_ NEMS SG_ 1023 CR_Bms_Nev_Info1 2000;
BA_REL_ "GenSigTimeoutTime" BU_SG_REL_ CGW SG_ 1023 CR_Bms_Nev_Info2 20000;
BA_REL_ "GenSigTimeoutTime" BU_SG_REL_ NEMS SG_ 1023 CR_Bms_Nev_Info2 20000;
BA_REL_ "GenSigTimeoutTime" BU_SG_REL_ CGW SG_ 1023 CR_Bms_Nev_Info3 2000;
BA_REL_ "GenSigTimeoutTime" BU_SG_REL_ NEMS SG_ 1023 CR_Bms_Nev_Info3 2000;
BA_REL_ "GenSigTimeoutTime" BU_SG_REL_ CGW SG_ 1023 CR_Bms_Nev_Info4 2000;
BA_REL_ "GenSigTimeoutTime" BU_SG_REL_ NEMS SG_ 1023 CR_Bms_Nev_Info4 2000;
BA_REL_ "GenSigTimeoutTime" BU_SG_REL_ CGW SG_ 1023 CR_Bms_Nev_Info5 2000;
BA_REL_ "GenSigTimeoutTime" BU_SG_REL_ NEMS SG_ 1023 CR_Bms_Nev_Info5 2000;
BA_REL_ "GenSigTimeoutTime" BU_SG_REL_ CGW SG_ 1023 CR_Bms_Nev_Info6 2000;
BA_REL_ "GenSigTimeoutTime" BU_SG_REL_ NEMS SG_ 1023 CR_Bms_Nev_Info6 2000;
BA_REL_ "GenSigTimeoutTime" BU_SG_REL_ CGW SG_ 1429 CR_Bms_Inlet_C 2000;
BA_REL_ "GenSigTimeoutTime" BU_SG_REL_ TMU SG_ 1429 CR_Bms_Inlet_C 2000;
BA_REL_ "GenSigTimeoutTime" BU_SG_REL_ VCU SG_ 1429 CR_Bms_Inlet_C 2000;
BA_REL_ "GenSigTimeoutTime" BU_SG_REL_ CGW SG_ 1429 CF_BMS_PrechgStatus 2000;
BA_REL_ "GenSigTimeoutTime" BU_SG_REL_ DATC SG_ 1429 CF_BMS_PrechgStatus 2000;
BA_REL_ "GenSigTimeoutTime" BU_SG_REL_ MCU SG_ 1429 CF_BMS_PrechgStatus 2000;
BA_REL_ "GenSigTimeoutTime" BU_SG_REL_ OBC SG_ 1429 CF_BMS_PrechgStatus 2000;
BA_REL_ "GenSigTimeoutTime" BU_SG_REL_ TMU SG_ 1429 CF_BMS_PrechgStatus 2000;
BA_REL_ "GenSigTimeoutTime" BU_SG_REL_ VCU SG_ 1429 CF_BMS_PrechgStatus 2000;
BA_REL_ "GenSigTimeoutTime" BU_SG_REL_ CDM SG_ 1429 CF_Bms_StdCha 2000;
BA_REL_ "GenSigTimeoutTime" BU_SG_REL_ CGW SG_ 1429 CF_Bms_StdCha 2000;
BA_REL_ "GenSigTimeoutTime" BU_SG_REL_ DATC SG_ 1429 CF_Bms_StdCha 2000;
BA_REL_ "GenSigTimeoutTime" BU_SG_REL_ LDC SG_ 1429 CF_Bms_StdCha 2000;
BA_REL_ "GenSigTimeoutTime" BU_SG_REL_ MCU SG_ 1429 CF_Bms_StdCha 2000;
BA_REL_ "GenSigTimeoutTime" BU_SG_REL_ TMU SG_ 1429 CF_Bms_StdCha 2000;
BA_REL_ "GenSigTimeoutTime" BU_SG_REL_ VCU SG_ 1429 CF_Bms_StdCha 2000;
BA_REL_ "GenSigTimeoutTime" BU_SG_REL_ CDM SG_ 1429 CF_Bms_FstCha 2000;
BA_REL_ "GenSigTimeoutTime" BU_SG_REL_ CGW SG_ 1429 CF_Bms_FstCha 2000;
BA_REL_ "GenSigTimeoutTime" BU_SG_REL_ DATC SG_ 1429 CF_Bms_FstCha 2000;
BA_REL_ "GenSigTimeoutTime" BU_SG_REL_ LDC SG_ 1429 CF_Bms_FstCha 2000;
BA_REL_ "GenSigTimeoutTime" BU_SG_REL_ MCU SG_ 1429 CF_Bms_FstCha 2000;
BA_REL_ "GenSigTimeoutTime" BU_SG_REL_ SMK SG_ 1429 CF_Bms_FstCha 2000;
BA_REL_ "GenSigTimeoutTime" BU_SG_REL_ TMU SG_ 1429 CF_Bms_FstCha 2000;
BA_REL_ "GenSigTimeoutTime" BU_SG_REL_ VCU SG_ 1429 CF_Bms_FstCha 2000;
BA_REL_ "GenSigTimeoutTime" BU_SG_REL_ CGW SG_ 1429 CF_Bms_StdCha_120V 2000;
BA_REL_ "GenSigTimeoutTime" BU_SG_REL_ TMU SG_ 1429 CF_Bms_StdCha_120V 2000;
BA_REL_ "GenSigTimeoutTime" BU_SG_REL_ VCU SG_ 1429 CF_Bms_StdCha_120V 2000;
BA_REL_ "GenSigTimeoutTime" BU_SG_REL_ CGW SG_ 1429 CR_Bms_FanSpdStp 2000;
BA_REL_ "GenSigTimeoutTime" BU_SG_REL_ TMU SG_ 1429 CR_Bms_FanSpdStp 2000;
BA_REL_ "GenSigTimeoutTime" BU_SG_REL_ VCU SG_ 1429 CR_Bms_FanSpdStp 2000;
BA_REL_ "GenSigTimeoutTime" BU_SG_REL_ CGW SG_ 1429 CR_Bms_BatMinCel_V 2000;
BA_REL_ "GenSigTimeoutTime" BU_SG_REL_ TMU SG_ 1429 CR_Bms_BatMinCel_V 2000;
BA_REL_ "GenSigTimeoutTime" BU_SG_REL_ VCU SG_ 1429 CR_Bms_BatMinCel_V 2000;
BA_REL_ "GenSigTimeoutTime" BU_SG_REL_ CGW SG_ 1429 CR_Bms_BatMaxCel_V 2000;
BA_REL_ "GenSigTimeoutTime" BU_SG_REL_ TMU SG_ 1429 CR_Bms_BatMaxCel_V 2000;
BA_REL_ "GenSigTimeoutTime" BU_SG_REL_ VCU SG_ 1429 CR_Bms_BatMaxCel_V 2000;
BA_REL_ "GenSigTimeoutTime" BU_SG_REL_ CGW SG_ 1429 CR_Bms_BatI_A 2000;
BA_REL_ "GenSigTimeoutTime" BU_SG_REL_ TMU SG_ 1429 CR_Bms_BatI_A 2000;
BA_REL_ "GenSigTimeoutTime" BU_SG_REL_ VCU SG_ 1429 CR_Bms_BatI_A 2000;
BA_REL_ "GenSigTimeoutTime" BU_SG_REL_ vBDM SG_ 1429 CR_Bms_BatI_A 2000;
BA_REL_ "GenSigTimeoutTime" BU_SG_REL_ CGW SG_ 1429 CR_Bms_BatTotV_V 2000;
BA_REL_ "GenSigTimeoutTime" BU_SG_REL_ MCU SG_ 1429 CR_Bms_BatTotV_V 2000;
BA_REL_ "GenSigTimeoutTime" BU_SG_REL_ OBC SG_ 1429 CR_Bms_BatTotV_V 2000;
BA_REL_ "GenSigTimeoutTime" BU_SG_REL_ TMU SG_ 1429 CR_Bms_BatTotV_V 2000;
BA_REL_ "GenSigTimeoutTime" BU_SG_REL_ VCU SG_ 1429 CR_Bms_BatTotV_V 2000;
BA_REL_ "GenSigTimeoutTime" BU_SG_REL_ VCU SG_ 1432 CR_BMS_RCHTimeEst 2000;
BA_REL_ "GenSigTimeoutTime" BU_SG_REL_ CGW SG_ 1432 CF_Bms_LowOutTempStatus 2000;
BA_REL_ "GenSigTimeoutTime" BU_SG_REL_ MCU SG_ 1432 CF_Bms_MotPwmOnReq 0;
BA_REL_ "GenSigTimeoutTime" BU_SG_REL_ MCU SG_ 1432 CF_Bms_IsolDetectOper 0;
BA_REL_ "GenSigTimeoutTime" BU_SG_REL_ VCU SG_ 1432 CF_Bms_IsolDetectOper 0;
BA_REL_ "GenSigTimeoutTime" BU_SG_REL_ VCU SG_ 1432 CF_Bms_QuickChgStartFlag 2000;
BA_REL_ "GenSigTimeoutTime" BU_SG_REL_ VCU SG_ 1432 CF_Bms_ClimateOffReq 2000;
BA_REL_ "GenSigTimeoutTime" BU_SG_REL_ VCU SG_ 1432 CF_Bms_PwrderatingFlg 2000;
BA_REL_ "GenSigTimeoutTime" BU_SG_REL_ CGW SG_ 1432 CF_Bms_ChgStopFlag 2000;
BA_REL_ "GenSigTimeoutTime" BU_SG_REL_ OBC SG_ 1432 CF_Bms_ChgStopFlag 2000;
BA_REL_ "GenSigTimeoutTime" BU_SG_REL_ CGW SG_ 1432 CR_Bms_HeatPwrMonCon_W 2000;
BA_REL_ "GenSigTimeoutTime" BU_SG_REL_ TMU SG_ 1432 CR_Bms_HeatPwrMonCon_W 2000;
BA_REL_ "GenSigTimeoutTime" BU_SG_REL_ CGW SG_ 1432 CR_Bms_energymap_1000ms 2000;
BA_REL_ "GenSigTimeoutTime" BU_SG_REL_ TMU SG_ 1432 CR_Bms_energymap_1000ms 2000;
BA_REL_ "GenSigTimeoutTime" BU_SG_REL_ VCU SG_ 1432 CR_Bms_energymap_1000ms 2000;
BA_REL_ "GenSigTimeoutTime" BU_SG_REL_ vBDM SG_ 1432 CR_Bms_energymap_1000ms 2000;
BA_REL_ "GenSigTimeoutTime" BU_SG_REL_ TMU SG_ 1432 CR_Bms_heat_temp1 2000;
BA_REL_ "GenSigTimeoutTime" BU_SG_REL_ VCU SG_ 1432 CR_Bms_heat_temp1 2000;
BA_REL_ "GenSigTimeoutTime" BU_SG_REL_ TMU SG_ 1432 CR_Bms_heat_temp2 2000;
BA_REL_ "GenSigTimeoutTime" BU_SG_REL_ VCU SG_ 1432 CR_Bms_heat_temp2 2000;
BA_REL_ "GenSigTimeoutTime" BU_SG_REL_ CCM SG_ 1433 CF_Bms_EvReady 2000;
BA_REL_ "GenSigTimeoutTime" BU_SG_REL_ OBC SG_ 1433 CF_Bms_EvReady 2000;
BA_REL_ "GenSigTimeoutTime" BU_SG_REL_ CCM SG_ 1433 CF_Bms_CabinConditioning 2000;
BA_REL_ "GenSigTimeoutTime" BU_SG_REL_ CCM SG_ 1433 CF_Bms_BatHeatStat 2000;
BA_REL_ "GenSigTimeoutTime" BU_SG_REL_ CCM SG_ 1433 CF_Bms_NoError 2000;
BA_REL_ "GenSigTimeoutTime" BU_SG_REL_ CCM SG_ 1433 CF_Bms_Fail_Temp 2000;
BA_REL_ "GenSigTimeoutTime" BU_SG_REL_ CCM SG_ 1433 CF_Bms_FAILED_EVShiftPosition 2000;
BA_REL_ "GenSigTimeoutTime" BU_SG_REL_ CCM SG_ 1433 CF_Bms_Fail_Conlock 2000;
BA_REL_ "GenSigTimeoutTime" BU_SG_REL_ CCM SG_ 1433 CF_Bms_Fail_Evmalf 2000;
BA_REL_ "GenSigTimeoutTime" BU_SG_REL_ CCM SG_ 1433 CF_Bms_Fail_CurrDiff 2000;
BA_REL_ "GenSigTimeoutTime" BU_SG_REL_ CCM SG_ 1433 CF_Bms_Fail_VoltRange 2000;
BA_REL_ "GenSigTimeoutTime" BU_SG_REL_ CCM SG_ 1433 CF_Bms_Fail_ChgSysIncom 2000;
BA_REL_ "GenSigTimeoutTime" BU_SG_REL_ CCM SG_ 1433 CF_Bms_NoData 2000;
BA_REL_ "GenSigTimeoutTime" BU_SG_REL_ CCM SG_ 1433 CF_Bms_ReadyToCharge 2000;
BA_REL_ "GenSigTimeoutTime" BU_SG_REL_ CCM SG_ 1433 CF_Bms_BulkChgComplete 2000;
BA_REL_ "GenSigTimeoutTime" BU_SG_REL_ OBC SG_ 1433 CF_Bms_BulkChgComplete 2000;
BA_REL_ "GenSigTimeoutTime" BU_SG_REL_ CCM SG_ 1433 CF_Bms_ChgComplete 2000;
BA_REL_ "GenSigTimeoutTime" BU_SG_REL_ OBC SG_ 1433 CF_Bms_ChgComplete 2000;
BA_REL_ "GenSigTimeoutTime" BU_SG_REL_ CCM SG_ 1433 CF_Bms_ChgFinished 2000;
BA_REL_ "GenSigTimeoutTime" BU_SG_REL_ CGW SG_ 1433 CF_Bms_ChgFinished 2000;
BA_REL_ "GenSigTimeoutTime" BU_SG_REL_ OBC SG_ 1433 CF_Bms_ChgFinished 2000;
BA_REL_ "GenSigTimeoutTime" BU_SG_REL_ vBDM SG_ 1433 CF_Bms_ChgFinished 2000;
BA_REL_ "GenSigTimeoutTime" BU_SG_REL_ CCM SG_ 1433 CR_BMS_DisplaySOC 2000;
BA_REL_ "GenSigTimeoutTime" BU_SG_REL_ CCM SG_ 1433 CR_Bms_EVmaxCurrent 2000;
BA_REL_ "GenSigTimeoutTime" BU_SG_REL_ CCM SG_ 1433 CR_Bms_EVmaxVolt 2000;
BA_REL_ "GenSigTimeoutTime" BU_SG_REL_ CCM SG_ 1433 CF_Bms_PreparationStatusForPLC 2000;
BA_REL_ "GenSigTimeoutTime" BU_SG_REL_ OBC SG_ 1433 CF_Bms_PreparationStatusForPLC 2000;
BA_REL_ "GenSigTimeoutTime" BU_SG_REL_ CCM SG_ 1433 CF_Bms_ReadyForCurDem 2000;
BA_REL_ "GenSigTimeoutTime" BU_SG_REL_ OBC SG_ 1433 CF_Bms_ReadyForCurDem 2000;
BA_REL_ "GenSigTimeoutTime" BU_SG_REL_ CCM SG_ 1433 CF_Bms_RlyWeldDetectionReq 2000;
BA_REL_ "GenSigTimeoutTime" BU_SG_REL_ Dummy SG_ 1433 CF_Bms_ChgInfoCode 2000;
BA_REL_ "GenSigTimeoutTime" BU_SG_REL_ VCMS SG_ 1433 CF_Bms_ChgInfoCode 2000;
BA_REL_ "GenSigTimeoutTime" BU_SG_REL_ CCM SG_ 1438 CR_Bms_FullSOCRemainedTime 2000;
BA_REL_ "GenSigTimeoutTime" BU_SG_REL_ CGW SG_ 1438 CR_Bms_FullSOCRemainedTime 2000;
BA_REL_ "GenSigTimeoutTime" BU_SG_REL_ vBDM SG_ 1438 CR_Bms_FullSOCRemainedTime 2000;
BA_REL_ "GenSigTimeoutTime" BU_SG_REL_ CCM SG_ 1438 CF_Bms_BulkRemTime_ChgOnly 2000;
BA_REL_ "GenSigTimeoutTime" BU_SG_REL_ CGW SG_ 1438 CF_Bms_BulkRemTime_ChgOnly 2000;
BA_REL_ "GenSigTimeoutTime" BU_SG_REL_ vBDM SG_ 1438 CF_Bms_BulkRemTime_ChgOnly 2000;
BA_REL_ "GenSigTimeoutTime" BU_SG_REL_ CCM SG_ 1438 CR_Bms_BatTotV_V 2000;
BA_REL_ "GenSigTimeoutTime" BU_SG_REL_ CCM SG_ 1438 CR_Bms_EVmaxPower 2000;
BA_REL_ "GenSigTimeoutTime" BU_SG_REL_ CGW SG_ 1014 CR_Bms_IG3WakeupPeriod 20000;
BA_REL_ "GenSigTimeoutTime" BU_SG_REL_ LDC SG_ 1014 CR_Bms_IG3WakeupPeriod 20000;
BA_REL_ "GenSigTimeoutTime" BU_SG_REL_ VCU SG_ 1014 CR_Bms_IG3WakeupPeriod 20000;
BA_REL_ "GenSigTimeoutTime" BU_SG_REL_ CCM SG_ 1436 CR_Bms_FullSOC 2000;
BA_REL_ "GenSigTimeoutTime" BU_SG_REL_ CCM SG_ 1436 CR_Bms_BulkSOC 2000;
BA_REL_ "GenSigTimeoutTime" BU_SG_REL_ CCM SG_ 1436 CR_Bms_EVTargetVolt 2000;
BA_REL_ "GenSigTimeoutTime" BU_SG_REL_ OBC SG_ 1436 CR_Bms_EVTargetVolt 2000;
BA_REL_ "GenSigTimeoutTime" BU_SG_REL_ CCM SG_ 1436 CR_Bms_EVTargetCurrent 2000;
BA_REL_ "GenSigTimeoutTime" BU_SG_REL_ CGW SG_ 1436 CR_Bms_EVTargetCurrent 2000;
BA_REL_ "GenSigTimeoutTime" BU_SG_REL_ OBC SG_ 1436 CR_Bms_EVTargetCurrent 2000;
BA_REL_ "GenSigTimeoutTime" BU_SG_REL_ vBDM SG_ 1436 CR_Bms_EVTargetCurrent 2000;
BA_REL_ "GenSigTimeoutTime" BU_SG_REL_ CCM SG_ 1436 CR_Bms_EvEnergyCapa 2000;
BA_REL_ "GenSigTimeoutTime" BU_SG_REL_ CGW SG_ 1436 CR_Bms_EvEnergyCapa 2000;
BA_REL_ "GenSigTimeoutTime" BU_SG_REL_ DATC SG_ 1167 HU_DATC_DrTempSetC 0;
BA_REL_ "GenSigTimeoutTime" BU_SG_REL_ DATC SG_ 1167 HU_DATC_DrTempSetF 0;
BA_REL_ "GenSigTimeoutTime" BU_SG_REL_ DATC SG_ 1167 HU_DATC_MainBlower 0;
BA_REL_ "GenSigTimeoutTime" BU_SG_REL_ DATC SG_ 1167 HU_DATC_FrontModeSet 0;
BA_REL_ "GenSigTimeoutTime" BU_SG_REL_ DATC SG_ 1167 HU_DATC_AutoSet 0;
BA_REL_ "GenSigTimeoutTime" BU_SG_REL_ DATC SG_ 1167 HU_DATC_AcSet 0;
BA_REL_ "GenSigTimeoutTime" BU_SG_REL_ DATC SG_ 1167 HU_DATC_IntakeSet 0;
BA_REL_ "GenSigTimeoutTime" BU_SG_REL_ DATC SG_ 1167 HU_DATC_FrontDefog 0;
BA_REL_ "GenSigTimeoutTime" BU_SG_REL_ DATC SG_ 1167 HU_DATC_AirCleaningSet 0;
BA_REL_ "GenSigTimeoutTime" BU_SG_REL_ DATC SG_ 1167 HU_DATC_ADSOnOffSet 0;
BA_REL_ "GenSigTimeoutTime" BU_SG_REL_ CGW SG_ 1410 CF_OLdc_AuxBatWrnLamp 2000;
BA_REL_ "GenSigTimeoutTime" BU_SG_REL_ LDC SG_ 1410 CF_OLdc_AuxBatWrnLamp 2000;
BA_REL_ "GenSigTimeoutTime" BU_SG_REL_ TMU SG_ 1410 CF_OLdc_AuxBatWrnLamp 2000;
BA_REL_ "GenSigTimeoutTime" BU_SG_REL_ CGW SG_ 1410 CF_OLdc_AuxBatWrnAlarm 2000;
BA_REL_ "GenSigTimeoutTime" BU_SG_REL_ LDC SG_ 1410 CF_OLdc_AuxBatWrnAlarm 2000;
BA_REL_ "GenSigTimeoutTime" BU_SG_REL_ TMU SG_ 1410 CF_OLdc_AuxBatWrnAlarm 2000;
BA_REL_ "GenSigTimeoutTime" BU_SG_REL_ MCU SG_ 1410 CR_OLdc_RadFanReq_Duty 2000;
BA_REL_ "GenSigTimeoutTime" BU_SG_REL_ TMU SG_ 1410 CR_OLdc_RadFanReq_Duty 2000;
BA_REL_ "GenSigTimeoutTime" BU_SG_REL_ VCU SG_ 1410 CR_OLdc_RadFanReq_Duty 2000;
BA_REL_ "GenSigTimeoutTime" BU_SG_REL_ CGW SG_ 1410 CR_OLdc_LoadPwrSum 2000;
BA_REL_ "GenSigTimeoutTime" BU_SG_REL_ LDC SG_ 1410 CR_OLdc_LoadPwrSum 2000;
BA_REL_ "GenSigTimeoutTime" BU_SG_REL_ LDC SG_ 1410 CR_OLdc_EWPRpmCnt 2000;
BA_REL_ "GenSigTimeoutTime" BU_SG_REL_ MCU SG_ 1410 CR_OLdc_EWPRpmCnt 2000;
BA_REL_ "GenSigTimeoutTime" BU_SG_REL_ TMU SG_ 1410 CR_OLdc_EWPRpmCnt 2000;
BA_REL_ "GenSigTimeoutTime" BU_SG_REL_ CGW SG_ 1410 CR_OLdc_PwrMon_W 2000;
BA_REL_ "GenSigTimeoutTime" BU_SG_REL_ LDC SG_ 1410 CR_OLdc_PwrMon_W 2000;
BA_REL_ "GenSigTimeoutTime" BU_SG_REL_ TMU SG_ 1410 CR_OLdc_PwrMon_W 2000;
BA_REL_ "GenSigTimeoutTime" BU_SG_REL_ VCU SG_ 1410 CR_OLdc_PwrMon_W 2000;
BA_REL_ "GenSigTimeoutTime" BU_SG_REL_ CGW SG_ 1169 CR_Bms_QcChgRemainedTime_min 2000;
BA_REL_ "GenSigTimeoutTime" BU_SG_REL_ H_U SG_ 1169 CR_Bms_QcChgRemainedTime_min 2000;
BA_REL_ "GenSigTimeoutTime" BU_SG_REL_ TMU SG_ 1169 CR_Bms_QcChgRemainedTime_min 2000;
BA_REL_ "GenSigTimeoutTime" BU_SG_REL_ vBDM SG_ 1169 CR_Bms_QcChgRemainedTime_min 2000;
BA_REL_ "GenSigTimeoutTime" BU_SG_REL_ TMU SG_ 1169 CR_Bms_QcsCmdCurr_A 2000;
BA_REL_ "GenSigTimeoutTime" BU_SG_REL_ TMU SG_ 1169 CR_Bms_PwmDutyCmd 2000;
BA_REL_ "GenSigTimeoutTime" BU_SG_REL_ TMU SG_ 1169 CR_Bms_FanFeedbackFreqbyCan 2000;
BA_REL_ "GenSigTimeoutTime" BU_SG_REL_ TMU SG_ 1169 CR_Bms_FanFeedbackFreqbyWire 2000;
BA_REL_ "GenSigTimeoutTime" BU_SG_REL_ TMU SG_ 1169 CR_Bms_Isol 2000;
BA_REL_ "GenSigTimeoutTime" BU_SG_REL_ TMU SG_ 1169 CF_Bms_ChgLamp 2000;
BA_REL_ "GenSigTimeoutTime" BU_SG_REL_ BMS SG_ 1409 CR_OBC_Mains_Cur 2000;
BA_REL_ "GenSigTimeoutTime" BU_SG_REL_ TMU SG_ 1409 CR_OBC_Mains_Cur 2000;
BA_REL_ "GenSigTimeoutTime" BU_SG_REL_ BMS SG_ 1409 CR_OBC_Mains_Vol 2000;
BA_REL_ "GenSigTimeoutTime" BU_SG_REL_ CGW SG_ 1409 CR_OBC_Mains_Vol 2000;
BA_REL_ "GenSigTimeoutTime" BU_SG_REL_ TMU SG_ 1409 CR_OBC_Mains_Vol 2000;
BA_REL_ "GenSigTimeoutTime" BU_SG_REL_ vBDM SG_ 1409 CR_OBC_Mains_Vol 2000;
BA_REL_ "GenSigTimeoutTime" BU_SG_REL_ BMS SG_ 1409 CR_OBC_Out_Vol 2000;
BA_REL_ "GenSigTimeoutTime" BU_SG_REL_ TMU SG_ 1409 CR_OBC_Out_Vol 2000;
BA_REL_ "GenSigTimeoutTime" BU_SG_REL_ BMS SG_ 1409 CR_OBC_Out_Cur 2000;
BA_REL_ "GenSigTimeoutTime" BU_SG_REL_ TMU SG_ 1409 CR_OBC_Out_Cur 2000;
BA_REL_ "GenSigTimeoutTime" BU_SG_REL_ DATC SG_ 1171 CR_Bms_FanSpdStp 2000;
BA_REL_ "GenSigTimeoutTime" BU_SG_REL_ TMU SG_ 1171 CR_Bms_FanSpdStp 2000;
BA_REL_ "GenSigTimeoutTime" BU_SG_REL_ CGW SG_ 1171 CF_BMS_NormalChgForOBC 2000;
BA_REL_ "GenSigTimeoutTime" BU_SG_REL_ H_U SG_ 1171 CF_BMS_NormalChgForOBC 2000;
BA_REL_ "GenSigTimeoutTime" BU_SG_REL_ TMU SG_ 1171 CF_BMS_NormalChgForOBC 2000;
BA_REL_ "GenSigTimeoutTime" BU_SG_REL_ CGW SG_ 1171 CF_Bms_VCRM_Req 2000;
BA_REL_ "GenSigTimeoutTime" BU_SG_REL_ H_U SG_ 1171 CF_Bms_VCRM_Req 2000;
BA_REL_ "GenSigTimeoutTime" BU_SG_REL_ TMU SG_ 1171 CF_Bms_VCRM_Req 2000;
BA_REL_ "GenSigTimeoutTime" BU_SG_REL_ vBDM SG_ 1171 CF_Bms_VCRM_Req 2000;
BA_REL_ "GenSigTimeoutTime" BU_SG_REL_ TMU SG_ 1171 CF_Bms_Diag_Monitor 2000;
BA_REL_ "GenSigTimeoutTime" BU_SG_REL_ CGW SG_ 1171 CF_Bms_FstCha 2000;
BA_REL_ "GenSigTimeoutTime" BU_SG_REL_ H_U SG_ 1171 CF_Bms_FstCha 2000;
BA_REL_ "GenSigTimeoutTime" BU_SG_REL_ TMU SG_ 1171 CF_Bms_FstCha 2000;
BA_REL_ "GenSigTimeoutTime" BU_SG_REL_ TMU SG_ 1171 CF_Bms_QcRlyOnStatForQcs 2000;
BA_REL_ "GenSigTimeoutTime" BU_SG_REL_ TMU SG_ 1171 CF_BMS_QcsChgFinished 2000;
BA_REL_ "GenSigTimeoutTime" BU_SG_REL_ CGW SG_ 1171 CF_Bms_FstEvseFltAlram 2000;
BA_REL_ "GenSigTimeoutTime" BU_SG_REL_ TMU SG_ 1171 CF_Bms_FstEvseFltAlram 2000;
BA_REL_ "GenSigTimeoutTime" BU_SG_REL_ TMU SG_ 1171 CR_Bms_SWversion 2000;
BA_REL_ "GenSigTimeoutTime" BU_SG_REL_ VCU SG_ 1171 CR_Bms_SWversion 2000;
BA_REL_ "GenSigTimeoutTime" BU_SG_REL_ TMU SG_ 1171 CF_Bms_Chgfaultsubcode 2000;
BA_REL_ "GenSigTimeoutTime" BU_SG_REL_ CGW SG_ 1171 CR_Bms_ScChgRemainedTime_120V 2000;
BA_REL_ "GenSigTimeoutTime" BU_SG_REL_ H_U SG_ 1171 CR_Bms_ScChgRemainedTime_120V 2000;
BA_REL_ "GenSigTimeoutTime" BU_SG_REL_ TMU SG_ 1171 CR_Bms_ScChgRemainedTime_120V 2000;
BA_REL_ "GenSigTimeoutTime" BU_SG_REL_ CGW SG_ 1414 CF_Evp1_State 1500;
BA_REL_ "GenSigTimeoutTime" BU_SG_REL_ EVP2 SG_ 1414 CF_Evp1_State 1500;
BA_REL_ "GenSigTimeoutTime" BU_SG_REL_ iBAU SG_ 1414 CF_Evp1_State 1500;
BA_REL_ "GenSigTimeoutTime" BU_SG_REL_ EVP2 SG_ 1414 CF_Evp1_DefMode 1500;
BA_REL_ "GenSigTimeoutTime" BU_SG_REL_ EVP2 SG_ 1414 CF_Evp1_V_level 1500;
BA_REL_ "GenSigTimeoutTime" BU_SG_REL_ EVP2 SG_ 1414 CF_Evp1_RunCount 1500;
BA_REL_ "GenSigTimeoutTime" BU_SG_REL_ EVP2 SG_ 1414 CF_Evp1_RunChk 1500;
BA_REL_ "GenSigTimeoutTime" BU_SG_REL_ iBAU SG_ 1414 CF_Evp1_RunChk 1500;
BA_REL_ "GenSigTimeoutTime" BU_SG_REL_ VCU SG_ 765 FLAG_TQI_TCS 0;
BA_REL_ "GenSigTimeoutTime" BU_SG_REL_ VCU SG_ 765 FLAG_TQI_MSR 0;
BA_REL_ "GenSigTimeoutTime" BU_SG_REL_ VCU SG_ 765 FLAG_TQI_SLW_TCS 0;
BA_REL_ "GenSigTimeoutTime" BU_SG_REL_ AAF_Tester SG_ 1412 CF_Aaf_ActFlapStatus 1000;
BA_REL_ "GenSigTimeoutTime" BU_SG_REL_ EMS SG_ 1412 CF_Aaf_ActFlapStatus 1000;
BA_REL_ "GenSigTimeoutTime" BU_SG_REL_ TMU SG_ 1412 CF_Aaf_ActFlapStatus 1000;
BA_REL_ "GenSigTimeoutTime" BU_SG_REL_ AAF_Tester SG_ 1412 CF_Aaf_ModeStatus 1000;
BA_REL_ "GenSigTimeoutTime" BU_SG_REL_ TMU SG_ 1412 CF_Aaf_ModeStatus 1000;
BA_REL_ "GenSigTimeoutTime" BU_SG_REL_ CGW SG_ 1412 CF_Aaf_WrnLamp 5000;
BA_REL_ "GenSigTimeoutTime" BU_SG_REL_ H_U SG_ 1412 CF_Aaf_WrnLamp 5000;
BA_REL_ "GenSigTimeoutTime" BU_SG_REL_ TMU SG_ 1412 CF_Aaf_WrnLamp 5000;
BA_REL_ "GenSigTimeoutTime" BU_SG_REL_ vBDM SG_ 1412 CF_Aaf_WrnLamp 5000;
BA_REL_ "GenSigTimeoutTime" BU_SG_REL_ AAF_Tester SG_ 1412 CF_Aaf_ErrStatus 1000;
BA_REL_ "GenSigTimeoutTime" BU_SG_REL_ EMS SG_ 1412 CF_Aaf_ErrStatus 1000;
BA_REL_ "GenSigTimeoutTime" BU_SG_REL_ TMU SG_ 1412 CF_Aaf_ErrStatus 1000;
BA_REL_ "GenSigTimeoutTime" BU_SG_REL_ AAF_Tester SG_ 1412 CF_Aaf_OpenRqSysAct 1000;
BA_REL_ "GenSigTimeoutTime" BU_SG_REL_ TMU SG_ 1412 CF_Aaf_OpenRqSysAct 1000;
BA_REL_ "GenSigTimeoutTime" BU_SG_REL_ AAF_Tester SG_ 1412 CF_Aaf_PStatus 1000;
BA_REL_ "GenSigTimeoutTime" BU_SG_REL_ TMU SG_ 1412 CF_Aaf_PStatus 1000;
BA_REL_ "GenSigTimeoutTime" BU_SG_REL_ AAF_Tester SG_ 1412 CF_Aaf_PStatusSub 1000;
BA_REL_ "GenSigTimeoutTime" BU_SG_REL_ TMU SG_ 1412 CF_Aaf_PStatusSub 1000;
BA_REL_ "GenSigTimeoutTime" BU_SG_REL_ EMS SG_ 1412 CF_Aaf_MilOnReq 1000;
BA_REL_ "GenSigTimeoutTime" BU_SG_REL_ TMU SG_ 1412 CF_Aaf_MilOnReq 1000;
BA_REL_ "GenSigTimeoutTime" BU_SG_REL_ AAF_2 SG_ 1412 CF_Aaf_ActFlapTarget 1000;
BA_REL_ "GenSigTimeoutTime" BU_SG_REL_ AAF_3 SG_ 1412 CF_Aaf_ActFlapTarget 1000;
BA_REL_ "GenSigTimeoutTime" BU_SG_REL_ AAF_Tester SG_ 1412 CF_Aaf_ActFlapTarget 1000;
BA_REL_ "GenSigTimeoutTime" BU_SG_REL_ TMU SG_ 1412 CF_Aaf_ActFlapTarget 1000;
BA_REL_ "GenSigTimeoutTime" BU_SG_REL_ AAF_2 SG_ 1412 CF_Aaf_ActFlapTarget_2 1000;
BA_REL_ "GenSigTimeoutTime" BU_SG_REL_ AAF_3 SG_ 1412 CF_Aaf_ActFlapTarget_2 1000;
BA_REL_ "GenSigTimeoutTime" BU_SG_REL_ AAF_Tester SG_ 1412 CF_Aaf_ActFlapTarget_2 1000;
BA_REL_ "GenSigTimeoutTime" BU_SG_REL_ TMU SG_ 1412 CF_Aaf_ActFlapTarget_2 1000;
BA_REL_ "GenSigTimeoutTime" BU_SG_REL_ Dummy SG_ 1175 CR_Bms_HeaderID_Slave 20000;
BA_REL_ "GenSigTimeoutTime" BU_SG_REL_ CGW SG_ 1175 CR_Bms_Valve_order1 20000;
BA_REL_ "GenSigTimeoutTime" BU_SG_REL_ Dummy SG_ 1175 CR_Bms_Valve_order1 20000;
BA_REL_ "GenSigTimeoutTime" BU_SG_REL_ vBDM SG_ 1175 CR_Bms_Valve_order1 20000;
BA_REL_ "GenSigTimeoutTime" BU_SG_REL_ Dummy SG_ 1175 CR_Bms_Valve1_orderFB 20000;
BA_REL_ "GenSigTimeoutTime" BU_SG_REL_ Dummy SG_ 1175 CR_Bms_Valve_order2 20000;
BA_REL_ "GenSigTimeoutTime" BU_SG_REL_ Dummy SG_ 1175 CR_Bms_Valve2_orderFB 20000;
BA_REL_ "GenSigTimeoutTime" BU_SG_REL_ Dummy SG_ 1175 CF_Valve1_Checksum_Fault 20000;
BA_REL_ "GenSigTimeoutTime" BU_SG_REL_ Dummy SG_ 1175 CF_Valve2_Checksum_Fault 20000;
BA_REL_ "GenSigTimeoutTime" BU_SG_REL_ Dummy SG_ 1175 CF_EWP1_Checksum_Fault 20000;
BA_REL_ "GenSigTimeoutTime" BU_SG_REL_ Dummy SG_ 1176 CR_Valve1_HWversion 20000;
BA_REL_ "GenSigTimeoutTime" BU_SG_REL_ Dummy SG_ 1176 CR_Valve1_SWversion 20000;
BA_REL_ "GenSigTimeoutTime" BU_SG_REL_ Dummy SG_ 1176 CR_Valve1_AuxVolt 20000;
BA_REL_ "GenSigTimeoutTime" BU_SG_REL_ Dummy SG_ 1176 CR_Valve1_OperAngle 20000;
BA_REL_ "GenSigTimeoutTime" BU_SG_REL_ CGW SG_ 1176 CR_Valve1_Status 20000;
BA_REL_ "GenSigTimeoutTime" BU_SG_REL_ DATC SG_ 1176 CR_Valve1_Status 20000;
BA_REL_ "GenSigTimeoutTime" BU_SG_REL_ Dummy SG_ 1176 CR_Valve1_Status 20000;
BA_REL_ "GenSigTimeoutTime" BU_SG_REL_ vBDM SG_ 1176 CR_Valve1_Status 20000;
BA_REL_ "GenSigTimeoutTime" BU_SG_REL_ Dummy SG_ 1176 CR_Valve1_FaultCode 20000;
BA_REL_ "GenSigTimeoutTime" BU_SG_REL_ Dummy SG_ 1176 CF_Bms_Checksum1_Fault 20000;
BA_REL_ "GenSigTimeoutTime" BU_SG_REL_ Dummy SG_ 1176 CR_Valve2_HWversion 20000;
BA_REL_ "GenSigTimeoutTime" BU_SG_REL_ Dummy SG_ 1176 CR_Valve2_SWversion 20000;
BA_REL_ "GenSigTimeoutTime" BU_SG_REL_ Dummy SG_ 1176 CR_Valve2_AuxVolt 20000;
BA_REL_ "GenSigTimeoutTime" BU_SG_REL_ Dummy SG_ 1176 CR_Valve2_OperAngle 20000;
BA_REL_ "GenSigTimeoutTime" BU_SG_REL_ DATC SG_ 1176 CR_Valve2_Status 20000;
BA_REL_ "GenSigTimeoutTime" BU_SG_REL_ Dummy SG_ 1176 CR_Valve2_Status 20000;
BA_REL_ "GenSigTimeoutTime" BU_SG_REL_ Dummy SG_ 1176 CR_Valve2_FaultCode 20000;
BA_REL_ "GenSigTimeoutTime" BU_SG_REL_ Dummy SG_ 1176 CF_Bms_Checksum2_Fault 20000;
BA_REL_ "GenSigTimeoutTime" BU_SG_REL_ VCU SG_ 1418 Msg_Group_Num6 2000;
BA_REL_ "GenSigTimeoutTime" BU_SG_REL_ VCU SG_ 1418 CurPosTraffic 2000;
BA_REL_ "GenSigTimeoutTime" BU_SG_REL_ VCU SG_ 1418 CurTrafLength 2000;
BA_REL_ "GenSigTimeoutTime" BU_SG_REL_ VCU SG_ 1418 NextTrafDistance 2000;
BA_REL_ "GenSigTimeoutTime" BU_SG_REL_ VCU SG_ 1418 NextPosTraffic 2000;
BA_REL_ "GenSigTimeoutTime" BU_SG_REL_ DATC SG_ 1178 Navi_AirConditionType 1500;
BA_REL_ "GenSigTimeoutTime" BU_SG_REL_ DATC SG_ 1178 Navi_AirConditionWarning 1500;
BA_REL_ "GenSigTimeoutTime" BU_SG_REL_ CGW SG_ 1179 MUTETIMER_FL 2000;
BA_REL_ "GenSigTimeoutTime" BU_SG_REL_ CGW SG_ 1179 MUTETIMER_FR 2000;
BA_REL_ "GenSigTimeoutTime" BU_SG_REL_ CGW SG_ 1179 MUTETIMER_RL 2000;
BA_REL_ "GenSigTimeoutTime" BU_SG_REL_ CGW SG_ 1179 MUTETIMER_RR 2000;
BA_REL_ "GenSigTimeoutTime" BU_SG_REL_ MCU SG_ 1423 CF_Ldc_MainState 2000;
BA_REL_ "GenSigTimeoutTime" BU_SG_REL_ MCU SG_ 1423 CF_Ldc_SubState 2000;
BA_REL_ "GenSigTimeoutTime" BU_SG_REL_ MCU SG_ 1423 CR_Ldc_VolCmd_LS_V 2000;
BA_REL_ "GenSigTimeoutTime" BU_SG_REL_ CGW SG_ 1423 CR_LDC_LoadPwrSum 2000;
BA_REL_ "GenSigTimeoutTime" BU_SG_REL_ MCU SG_ 1423 CR_Ldc_ActVol_HS_V 2000;
BA_REL_ "GenSigTimeoutTime" BU_SG_REL_ MCU SG_ 1423 CF_Ldc_TmpLmt 2000;
BA_REL_ "GenSigTimeoutTime" BU_SG_REL_ MCU SG_ 1423 CF_Ldc_CurLmt 2000;
BA_REL_ "GenSigTimeoutTime" BU_SG_REL_ MCU SG_ 1423 CF_Vb_UV 2000;
BA_REL_ "GenSigTimeoutTime" BU_SG_REL_ MCU SG_ 1423 CF_Vb_OV 2000;
BA_REL_ "GenSigTimeoutTime" BU_SG_REL_ MCU SG_ 1423 CF_Ldc_CurChaMode 2000;
BA_REL_ "GenSigTimeoutTime" BU_SG_REL_ MCU SG_ 1423 CF_Ldc_BmsMsgLost 2000;
BA_REL_ "GenSigTimeoutTime" BU_SG_REL_ MCU SG_ 1423 CF_Ldc_McuMsgLost 2000;
BA_REL_ "GenSigTimeoutTime" BU_SG_REL_ MCU SG_ 1423 CF_Ldc_VCUMsgLost 2000;
BA_REL_ "GenSigTimeoutTime" BU_SG_REL_ BMS SG_ 1422 CF_OBC_InfoCode 2000;
BA_REL_ "GenSigTimeoutTime" BU_SG_REL_ CGW SG_ 1422 CF_OBC_InfoCode 2000;
BA_REL_ "GenSigTimeoutTime" BU_SG_REL_ TMU SG_ 1422 CF_OBC_InfoCode 2000;
BA_REL_ "GenSigTimeoutTime" BU_SG_REL_ vBDM SG_ 1422 CF_OBC_InfoCode 2000;
BA_REL_ "GenSigTimeoutTime" BU_SG_REL_ BMS SG_ 1422 CF_OBC_SeqState 2000;
BA_REL_ "GenSigTimeoutTime" BU_SG_REL_ TMU SG_ 1422 CF_OBC_SeqState 2000;
BA_REL_ "GenSigTimeoutTime" BU_SG_REL_ BMS SG_ 1422 CR_OBC_PwrEst 2000;
BA_REL_ "GenSigTimeoutTime" BU_SG_REL_ LDC SG_ 1422 CF_OBC_Asw_Num 2000;
BA_REL_ "GenSigTimeoutTime" BU_SG_REL_ LDC SG_ 1422 CF_OBC_Asw_DevStep 2000;
BA_REL_ "GenSigTimeoutTime" BU_SG_REL_ LDC SG_ 1422 CF_OBC_Asw_Mode 2000;
BA_REL_ "GenSigTimeoutTime" BU_SG_REL_ LDC SG_ 1422 CF_OBC_InletMode 2000;
BA_REL_ "GenSigTimeoutTime" BU_SG_REL_ LDC SG_ 1422 CF_OBC_InletPlugMode 2000;
BA_REL_ "GenSigTimeoutTime" BU_SG_REL_ LDC SG_ 1422 CF_OBC_InletSwMode 2000;
BA_REL_ "GenSigTimeoutTime" BU_SG_REL_ CGW SG_ 1422 CF_OBC_GPSChg_InCurMode 2000;
BA_REL_ "GenSigTimeoutTime" BU_SG_REL_ CGW SG_ 1422 CF_OBC_EVSE_InCurMode 2000;
BA_REL_ "GenSigTimeoutTime" BU_SG_REL_ CGW SG_ 1422 CF_OBC_ICCB_InCurMode 2000;
BA_REL_ "GenSigTimeoutTime" BU_SG_REL_ CGW SG_ 1422 CF_OBC_Plug_Type 2000;
BA_REL_ "GenSigTimeoutTime" BU_SG_REL_ LDC SG_ 1422 CF_OBC_Plug_Type 2000;
BA_REL_ "GenSigTimeoutTime" BU_SG_REL_ BMS SG_ 1422 CR_OBC_CP_DutyFloat 2000;
BA_REL_ "GenSigTimeoutTime" BU_SG_REL_ LDC SG_ 1422 CR_OBC_CP_DutyFloat 2000;
BA_REL_ "GenSigTimeoutTime" BU_SG_REL_ CGW SG_ 1422 CF_OBC_InletUnlock_Inh 2000;
BA_REL_ "GenSigTimeoutTime" BU_SG_REL_ TMU SG_ 1422 CF_OBC_InletUnlock_Inh 2000;
BA_REL_ "GenSigTimeoutTime" BU_SG_REL_ CGW SG_ 1422 CF_OBC_InletLock_Req 2000;
BA_REL_ "GenSigTimeoutTime" BU_SG_REL_ TMU SG_ 1422 CF_OBC_InletLock_Req 2000;
BA_REL_ "GenSigTimeoutTime" BU_SG_REL_ BMS SG_ 1422 CF_OBC_ChgLampOffReqForBMS 2000;
BA_REL_ "GenSigTimeoutTime" BU_SG_REL_ BMS SG_ 1422 CF_OBC_PLC_CP_FAULT 2000;
BA_REL_ "GenSigTimeoutTime" BU_SG_REL_ CDM SG_ 1422 CF_OBC_IG3RlyMd 2000;
BA_REL_ "GenSigTimeoutTime" BU_SG_REL_ TMU SG_ 1422 CF_OBC_IG3RlyMd 2000;
BA_REL_ "GenSigTimeoutTime" BU_SG_REL_ OBC SG_ 1182 CF_CDM_ChgDrSwFrt 2000;
BA_REL_ "GenSigTimeoutTime" BU_SG_REL_ VCU SG_ 1182 CF_CDM_ChgDrSwFrt 2000;
BA_REL_ "GenSigTimeoutTime" BU_SG_REL_ OBC SG_ 1182 CF_CDM_ImmeChgSw 2000;
BA_REL_ "GenSigTimeoutTime" BU_SG_REL_ VCU SG_ 1182 CF_CDM_ImmeChgSw 2000;
BA_REL_ "GenSigTimeoutTime" BU_SG_REL_ VCU SG_ 1459 C_EV_SpeedLimitOnOff 1500;
BA_REL_ "GenSigTimeoutTime" BU_SG_REL_ DATC SG_ 1459 C_EV_NormalClimateLimit 1500;
BA_REL_ "GenSigTimeoutTime" BU_SG_REL_ VCU SG_ 1459 C_EV_NormalClimateLimit 1500;
BA_REL_ "GenSigTimeoutTime" BU_SG_REL_ DATC SG_ 1459 C_EV_SportClimateLimit 1500;
BA_REL_ "GenSigTimeoutTime" BU_SG_REL_ VCU SG_ 1459 C_EV_SportClimateLimit 1500;
BA_REL_ "GenSigTimeoutTime" BU_SG_REL_ DATC SG_ 1459 C_EV_EcoClimateLimit 1500;
BA_REL_ "GenSigTimeoutTime" BU_SG_REL_ VCU SG_ 1459 C_EV_EcoClimateLimit 1500;
BA_REL_ "GenSigTimeoutTime" BU_SG_REL_ VCU SG_ 1459 C_EV_NormalRegenrationLevel 1500;
BA_REL_ "GenSigTimeoutTime" BU_SG_REL_ VCU SG_ 1459 C_EV_SportRegenrationLevel 1500;
BA_REL_ "GenSigTimeoutTime" BU_SG_REL_ VCU SG_ 1459 C_EV_EcoRegenrationLevel 1500;
BA_REL_ "GenSigTimeoutTime" BU_SG_REL_ VCU SG_ 1459 C_EV_ClimateScnOnOff 1500;
BA_REL_ "GenSigTimeoutTime" BU_SG_REL_ VCU SG_ 1459 C_EV_MaxSpeed 1500;
BA_REL_ "GenSigTimeoutTime" BU_SG_REL_ OBC SG_ 1459 CF_TMU_GPSChg_InCurModeState 1500;
BA_REL_ "GenSigTimeoutTime" BU_SG_REL_ BMS SG_ 1459 HU_EV_GpsSchedUpdateRes 1500;
BA_REL_ "GenSigTimeoutTime" BU_SG_REL_ OBC SG_ 1459 HU_EV_GpsSchedUpdateRes 1500;
BA_REL_ "GenSigTimeoutTime" BU_SG_REL_ VCU SG_ 1459 HU_EV_GpsSchedUpdateRes 1500;
BA_REL_ "GenSigTimeoutTime" BU_SG_REL_ BMS SG_ 1459 HU_EV_GpsSched_State 1500;
BA_REL_ "GenSigTimeoutTime" BU_SG_REL_ OBC SG_ 1459 HU_EV_GpsSched_State 1500;
BA_REL_ "GenSigTimeoutTime" BU_SG_REL_ VCU SG_ 1459 HU_EV_GpsSched_State 1500;
BA_REL_ "GenSigTimeoutTime" BU_SG_REL_ VCU SG_ 1459 HU_EV_GpsSched_ChgAir 1500;
BA_REL_ "GenSigTimeoutTime" BU_SG_REL_ VCU SG_ 1459 CF_AVN_EVReset 1500;
BA_REL_ "GenSigTimeoutTime" BU_SG_REL_ DATC SG_ 1460 HU_TempUnit 1500;
BA_REL_ "GenSigTimeoutTime" BU_SG_REL_ DATC SG_ 1460 CF_AVN_ProfileIDRValue 700;
BA_REL_ "GenSigTimeoutTime" BU_SG_REL_ OBC SG_ 1190 CF_AVN_CluUSMReset 0;
BA_REL_ "GenSigTimeoutTime" BU_SG_REL_ CGW SG_ 1464 C_FRSeatTumblerSW 1500;
BA_REL_ "GenSigTimeoutTime" BU_SG_REL_ IBU SG_ 1464 C_FRSeatTumblerSW 1500;
BA_REL_ "GenSigTimeoutTime" BU_SG_REL_ CGW SG_ 1464 C_FLSeatTumblerSW 1500;
BA_REL_ "GenSigTimeoutTime" BU_SG_REL_ IBU SG_ 1464 C_FLSeatTumblerSW 1500;
BA_REL_ "GenSigTimeoutTime" BU_SG_REL_ CGW SG_ 1464 DATC_FRWndShldHtSW 1500;
BA_REL_ "GenSigTimeoutTime" BU_SG_REL_ CGW SG_ 1464 DATC_WhistlelNoise 1500;
BA_REL_ "GenSigTimeoutTime" BU_SG_REL_ DATC SG_ 1193 CR_Datc_DRSeatHeat_USM_Set 1000;
BA_REL_ "GenSigTimeoutTime" BU_SG_REL_ TCU SG_ 1193 C_AutoLeverManualSW 0;
BA_REL_ "GenSigTimeoutTime" BU_SG_REL_ Dummy SG_ 1193 C_DiagnConnStatus 1500;
BA_REL_ "GenSigTimeoutTime" BU_SG_REL_ VCU SG_ 1193 C_DiagnConnStatus 1500;
BA_REL_ "GenSigTimeoutTime" BU_SG_REL_ DATC SG_ 1193 C_PTGMOpt 1500;
BA_REL_ "GenSigTimeoutTime" BU_SG_REL_ DATC SG_ 1193 C_PTGOpnClsState 1500;
BA_REL_ "GenSigTimeoutTime" BU_SG_REL_ DATC SG_ 1193 C_RKETeleEngineRunning 1500;
BA_REL_ "GenSigTimeoutTime" BU_SG_REL_ VCU SG_ 1466 CF_AVN_AuxBatChargeNValueSet 0;
BA_REL_ "GenSigTimeoutTime" BU_SG_REL_ VCU SG_ 1466 CF_AVN_SmartRegenNValueSet 0;
BA_REL_ "GenSigTimeoutTime" BU_SG_REL_ VCU SG_ 1466 CF_AVN_RestModeNValueSet 0;
BA_REL_ "GenSigTimeoutTime" BU_SG_REL_ CGW SG_ 1467 DATC_Beep1Mode 0;
BA_REL_ "GenSigTimeoutTime" BU_SG_REL_ IBU SG_ 1467 DATC_Beep1Mode 0;
BA_REL_ "GenSigTimeoutTime" BU_SG_REL_ CGW SG_ 1468 DATC_AMP_Beep1VolumeStep 0;
BA_REL_ "GenSigTimeoutTime" BU_SG_REL_ IBU SG_ 1468 DATC_AMP_Beep1VolumeStep 0;
BA_REL_ "GenSigTimeoutTime" BU_SG_REL_ CGW SG_ 1468 DATC_AMP_Beep1Frequency 0;
BA_REL_ "GenSigTimeoutTime" BU_SG_REL_ IBU SG_ 1468 DATC_AMP_Beep1Frequency 0;
BA_REL_ "GenSigTimeoutTime" BU_SG_REL_ CGW SG_ 1468 DATC_AMP_Beep1Ch_OutputMask 0;
BA_REL_ "GenSigTimeoutTime" BU_SG_REL_ IBU SG_ 1468 DATC_AMP_Beep1Ch_OutputMask 0;
BA_REL_ "GenSigTimeoutTime" BU_SG_REL_ CGW SG_ 1468 DATC_AMP_Beep1DurationOn 0;
BA_REL_ "GenSigTimeoutTime" BU_SG_REL_ IBU SG_ 1468 DATC_AMP_Beep1DurationOn 0;
BA_REL_ "GenSigTimeoutTime" BU_SG_REL_ CGW SG_ 1468 DATC_AMP_Beep1DurationOff 0;
BA_REL_ "GenSigTimeoutTime" BU_SG_REL_ IBU SG_ 1468 DATC_AMP_Beep1DurationOff 0;
BA_REL_ "GenSigTimeoutTime" BU_SG_REL_ CGW SG_ 1468 DATC_AMP_Beep1NumberOfCycles 0;
BA_REL_ "GenSigTimeoutTime" BU_SG_REL_ IBU SG_ 1468 DATC_AMP_Beep1NumberOfCycles 0;
BA_REL_ "GenSigTimeoutTime" BU_SG_REL_ DATC SG_ 1469 HU_DATC_Beep1VolumeStep 0;
BA_REL_ "GenSigTimeoutTime" BU_SG_REL_ DATC SG_ 1469 HU_DATC_Beep1Frequency 0;
BA_REL_ "GenSigTimeoutTime" BU_SG_REL_ DATC SG_ 1469 HU_DATC_Beep1Ch_OutputMask 0;
BA_REL_ "GenSigTimeoutTime" BU_SG_REL_ DATC SG_ 1469 HU_DATC_Beep1DurationOn 0;
BA_REL_ "GenSigTimeoutTime" BU_SG_REL_ DATC SG_ 1469 HU_DATC_Beep1DurationOff 0;
BA_REL_ "GenSigTimeoutTime" BU_SG_REL_ DATC SG_ 1469 HU_DATC_Beep1NumberOfCycles 0;
BA_REL_ "GenSigTimeoutTime" BU_SG_REL_ Dummy SG_ 1202 CF_AVN_FCANValueSet 0;
BA_REL_ "GenSigTimeoutTime" BU_SG_REL_ Dummy SG_ 1202 CF_AVN_PasSpkrLvNValueSet 0;
BA_REL_ "GenSigTimeoutTime" BU_SG_REL_ Dummy SG_ 1202 CF_AVN_SCCDrvModeNValueSet 0;
BA_REL_ "GenSigTimeoutTime" BU_SG_REL_ Dummy SG_ 1202 CF_AVN_DAWModeNValueSet 0;
BA_REL_ "GenSigTimeoutTime" BU_SG_REL_ Dummy SG_ 1202 CF_AVN_HDA_LFANValueSet 0;
BA_REL_ "GenSigTimeoutTime" BU_SG_REL_ Dummy SG_ 1202 CF_AVN_BCWNValueSet 0;
BA_REL_ "GenSigTimeoutTime" BU_SG_REL_ Dummy SG_ 1202 CF_AVN_SEANValueSet 0;
BA_REL_ "GenSigTimeoutTime" BU_SG_REL_ Dummy SG_ 1202 CF_AVN_NSCCCamNValueSet 0;
BA_REL_ "GenSigTimeoutTime" BU_SG_REL_ Dummy SG_ 1202 CF_AVN_BCANValueSet 0;
BA_REL_ "GenSigTimeoutTime" BU_SG_REL_ Dummy SG_ 1202 CF_AVN_ISLWNValueSet 0;
BA_REL_ "GenSigTimeoutTime" BU_SG_REL_ Dummy SG_ 1202 CF_AVN_WarningTimingNValueSet 0;
BA_REL_ "GenSigTimeoutTime" BU_SG_REL_ Dummy SG_ 1202 CF_AVN_NCC_USM_set 0;
BA_REL_ "GenSigTimeoutTime" BU_SG_REL_ IBU SG_ 1202 CF_AVN_TirePressUnitNValueSet 0;
BA_REL_ "GenSigTimeoutTime" BU_SG_REL_ Dummy SG_ 1202 CF_AVN_RCCANValueSet 0;
BA_REL_ "GenSigTimeoutTime" BU_SG_REL_ Dummy SG_ 1202 CF_AVN_NSCCCrvNValueSet 0;
BA_REL_ "GenSigTimeoutTime" BU_SG_REL_ Dummy SG_ 1202 CF_AVN_BCWSndWanNValueSet 0;
BA_REL_ "GenSigTimeoutTime" BU_SG_REL_ Dummy SG_ 1202 CF_AVN_RCCWNValueSet 0;
BA_REL_ "GenSigTimeoutTime" BU_SG_REL_ Dummy SG_ 1202 CF_AVN_LkaModeNValueSet 0;
BA_REL_ "GenSigTimeoutTime" BU_SG_REL_ BMS SG_ 1440 CF_Ods_IDRcv 5000;
BA_REL_ "GenSigTimeoutTime" BU_SG_REL_ ODS SG_ 1440 CF_Ods_IDRcv 5000;
BA_REL_ "GenSigTimeoutTime" BU_SG_REL_ CGW SG_ 1440 CF_PasBkl_FltStat 5000;
BA_REL_ "GenSigTimeoutTime" BU_SG_REL_ ODS SG_ 1440 CF_PasBkl_FltStat 5000;
BA_REL_ "GenSigTimeoutTime" BU_SG_REL_ PSB SG_ 1440 CF_PasBkl_FltStat 5000;
BA_REL_ "GenSigTimeoutTime" BU_SG_REL_ CGW SG_ 1440 CF_DriBkl_FltStat 5000;
BA_REL_ "GenSigTimeoutTime" BU_SG_REL_ ODS SG_ 1440 CF_DriBkl_FltStat 5000;
BA_REL_ "GenSigTimeoutTime" BU_SG_REL_ PSB SG_ 1440 CF_DriBkl_FltStat 5000;
BA_REL_ "GenSigTimeoutTime" BU_SG_REL_ BMS SG_ 1440 CF_PasBkl_Stat 5000;
BA_REL_ "GenSigTimeoutTime" BU_SG_REL_ CGW SG_ 1440 CF_PasBkl_Stat 5000;
BA_REL_ "GenSigTimeoutTime" BU_SG_REL_ H_U SG_ 1440 CF_PasBkl_Stat 5000;
BA_REL_ "GenSigTimeoutTime" BU_SG_REL_ ODS SG_ 1440 CF_PasBkl_Stat 5000;
BA_REL_ "GenSigTimeoutTime" BU_SG_REL_ TMU SG_ 1440 CF_PasBkl_Stat 5000;
BA_REL_ "GenSigTimeoutTime" BU_SG_REL_ VCU SG_ 1440 CF_PasBkl_Stat 5000;
BA_REL_ "GenSigTimeoutTime" BU_SG_REL_ CGW SG_ 1440 CF_DriBkl_Stat 5000;
BA_REL_ "GenSigTimeoutTime" BU_SG_REL_ H_U SG_ 1440 CF_DriBkl_Stat 5000;
BA_REL_ "GenSigTimeoutTime" BU_SG_REL_ IBOX SG_ 1440 CF_DriBkl_Stat 5000;
BA_REL_ "GenSigTimeoutTime" BU_SG_REL_ ODS SG_ 1440 CF_DriBkl_Stat 5000;
BA_REL_ "GenSigTimeoutTime" BU_SG_REL_ PSB SG_ 1440 CF_DriBkl_Stat 5000;
BA_REL_ "GenSigTimeoutTime" BU_SG_REL_ vDCM SG_ 1440 CF_DriBkl_Stat 5000;
BA_REL_ "GenSigTimeoutTime" BU_SG_REL_ BMS SG_ 1440 CF_SWL_Ind 5000;
BA_REL_ "GenSigTimeoutTime" BU_SG_REL_ CGW SG_ 1440 CF_SWL_Ind 5000;
BA_REL_ "GenSigTimeoutTime" BU_SG_REL_ H_U SG_ 1440 CF_SWL_Ind 5000;
BA_REL_ "GenSigTimeoutTime" BU_SG_REL_ TMU SG_ 1440 CF_SWL_Ind 5000;
BA_REL_ "GenSigTimeoutTime" BU_SG_REL_ eCall SG_ 1440 CF_SWL_Ind 5000;
BA_REL_ "GenSigTimeoutTime" BU_SG_REL_ iBAU SG_ 1440 CF_SWL_Ind 5000;
BA_REL_ "GenSigTimeoutTime" BU_SG_REL_ vBDM SG_ 1440 CF_SWL_Ind 5000;
BA_REL_ "GenSigTimeoutTime" BU_SG_REL_ BMS SG_ 1440 CF_Acu_FltStat 5000;
BA_REL_ "GenSigTimeoutTime" BU_SG_REL_ CGW SG_ 1440 CF_Acu_FltStat 5000;
BA_REL_ "GenSigTimeoutTime" BU_SG_REL_ H_U SG_ 1440 CF_Acu_FltStat 5000;
BA_REL_ "GenSigTimeoutTime" BU_SG_REL_ TMU SG_ 1440 CF_Acu_FltStat 5000;
BA_REL_ "GenSigTimeoutTime" BU_SG_REL_ eCall SG_ 1440 CF_Acu_FltStat 5000;
BA_REL_ "GenSigTimeoutTime" BU_SG_REL_ CGW SG_ 1440 CF_Acu_ExtOfSab 5000;
BA_REL_ "GenSigTimeoutTime" BU_SG_REL_ BMS SG_ 1440 CF_Acu_Dtc 5000;
BA_REL_ "GenSigTimeoutTime" BU_SG_REL_ CGW SG_ 1440 CF_Acu_Dtc 5000;
BA_REL_ "GenSigTimeoutTime" BU_SG_REL_ H_U SG_ 1440 CF_Acu_Dtc 5000;
BA_REL_ "GenSigTimeoutTime" BU_SG_REL_ TMU SG_ 1440 CF_Acu_Dtc 5000;
BA_REL_ "GenSigTimeoutTime" BU_SG_REL_ eCall SG_ 1440 CF_Acu_Dtc 5000;
BA_REL_ "GenSigTimeoutTime" BU_SG_REL_ iBAU SG_ 1440 CF_Acu_Dtc 5000;
BA_REL_ "GenSigTimeoutTime" BU_SG_REL_ BMS SG_ 1440 CF_Acu_NumOfFlt 5000;
BA_REL_ "GenSigTimeoutTime" BU_SG_REL_ CGW SG_ 1440 CF_Acu_NumOfFlt 5000;
BA_REL_ "GenSigTimeoutTime" BU_SG_REL_ H_U SG_ 1440 CF_Acu_NumOfFlt 5000;
BA_REL_ "GenSigTimeoutTime" BU_SG_REL_ TMU SG_ 1440 CF_Acu_NumOfFlt 5000;
BA_REL_ "GenSigTimeoutTime" BU_SG_REL_ eCall SG_ 1440 CF_Acu_NumOfFlt 5000;
BA_REL_ "GenSigTimeoutTime" BU_SG_REL_ iBAU SG_ 1440 CF_Acu_NumOfFlt 5000;
BA_REL_ "GenSigTimeoutTime" BU_SG_REL_ CCM SG_ 1443 CR_Bms_EVTransferType 2000;
BA_REL_ "GenSigTimeoutTime" BU_SG_REL_ CGW SG_ 1443 CR_Bms_EVTransferType 2000;
BA_REL_ "GenSigTimeoutTime" BU_SG_REL_ vBDM SG_ 1443 CR_Bms_EVTransferType 2000;
BA_REL_ "GenSigTimeoutTime" BU_SG_REL_ OBC SG_ 1443 CF_Bms_Combo_InletLock_Req 1000;
BA_REL_ "GenSigTimeoutTime" BU_SG_REL_ CCM SG_ 1443 CF_Bms_MainRlyOnStat 2000;
BA_REL_ "GenSigTimeoutTime" BU_SG_REL_ CCM SG_ 1443 CR_Bms_EvEnergyReq 2000;
BA_REL_ "GenSigTimeoutTime" BU_SG_REL_ CCM SG_ 1443 CR_Bms_PLCChgFaultSubCode 0;
BA_REL_ "GenSigTimeoutTime" BU_SG_REL_ OBC SG_ 1443 CR_Bms_PLCChgFaultSubCode 0;
BA_REL_ "GenSigTimeoutTime" BU_SG_REL_ VCU SG_ 1443 CR_Bms_ScChgEnergy_TargetSOC 2000;
BA_REL_ "GenSigTimeoutTime" BU_SG_REL_ VCU SG_ 1443 CR_Bms_QcChgEnergy_TargetSOC 2000;
BA_REL_ "GenSigTimeoutTime" BU_SG_REL_ DATC SG_ 1205 CF_AVN_CluUSMReset 0;
BA_REL_ "GenSigTimeoutTime" BU_SG_REL_ IBU SG_ 1205 CF_AVN_CluUSMReset 0;
BA_REL_ "GenSigTimeoutTime" BU_SG_REL_ VCU SG_ 1205 CF_AVN_CluUSMReset 0;
BA_REL_ "GenSigTimeoutTime" BU_SG_REL_ DATC SG_ 1205 CF_AVN_UnitReset 0;
BA_REL_ "GenSigTimeoutTime" BU_SG_REL_ IBU SG_ 1205 CF_AVN_UnitReset 0;
VAL_ 1250 CR_Bms_3wayVav_CtrlMode 0 "Separate mode" 1 "Series mode" ;
VAL_ 1250 CR_Bms_3WayVav_CtrlMode2 0 "Control mode 1" 1 "Control mode 2" ;
VAL_ 1250 CF_Bms_WCS_HeaterRlyOnStat 0 "Relay Off" 1 "Relay On" ;
VAL_ 1250 CF_Bms_BTMSdiag_flag 0 "normal state" 1 "abnormal  state" ;
VAL_ 1262 CF_OBC_Lamp_Req 0 "No Request" 1 "Lamp Request" ;
VAL_ 1262 CF_OBC_EVSE_RDY_STATE 0 "Not Wake up" 1 "Wake up" ;
VAL_ 1262 CF_EVSE_FAULT_FLAG 0 "Normal" 1 "Fault" ;
VAL_ 1262 CR_OBC_DiagInfoGrp 0 "Normal" 1 "OBC Fault" 2 "Abnormal Grid" 3 "Fail Safe" 4 "Not Used" 5 "Not Used" 6 "Not Used" 7 "Error Indicator" ;
VAL_ 916 BrakeLight 0 "No request" 1 "Activate brake lights" ;
VAL_ 916 DCEnable 0 "Disable deceleration control" 1 "Enable deceleration control" ;
VAL_ 916 Pre_TCS_CTL 0 "-" 1 "Pre TCS Active" ;
VAL_ 916 EBA_ACK 0 "Not valid" 1 "EBA function valid" ;
VAL_ 916 FCA_ACK 0 "Not valid" 1 "All FCA  function valid" ;
VAL_ 916 DF_BF_STAT 0 "Differential braking available without error" 1 "Differential braking disable" 2 "Differential braking is activated" 3 "Reserved" ;
VAL_ 916 SCCReqLim 0 "No request" 1 "Limited No Limitation" 2 "Acceleration Limited" 3 "Deceleration Limited" ;
VAL_ 916 SCCEnable 0 "SCC enabled" 1 "SCC disabled reversible" 2 "SCC disabled irreversible" 3 "SCC disabled irreversible due to communication error" ;
VAL_ 916 DriverOverride 0 "No override" 1 "Override by acceleration pedal" 2 "Override by deceleration" 3 "Not defined" ;
VAL_ 916 StandStill 0 "No stand still detected" 1 "stand still detected" ;
VAL_ 916 SCC_EQUIP 0 "SCC is not equipped" 1 "SCC is equipped" ;
VAL_ 916 PBRAKE_ACT 0 "Parking brake is not activated" 1 "Parking brake is activated" ;
VAL_ 916 SCC_REQ 0 "No request" 1 "Enable SCC torque request" ;
VAL_ 916 DriverBraking 0 "Brake pedal not pressed" 1 "Brake pedal pressed" ;
VAL_ 916 DBS_ACK 0 "DBS control inactive" 1 "DBS control active" ;
VAL_ 916 CF_VSM_Avail 0 "Available" 1 "Temporarily not available" 2 "Permanently not available" 3 "AEB Communication Error" ;
VAL_ 916 FCA_CODED_STAT 0 "Not Coded" 1 "Coding Completed" ;
VAL_ 916 SCC_CODED_STAT 0 "Not Coded" 1 "Coding Completed" ;
VAL_ 916 ESC_BcaRPlusSta 0 "BcaRPlus available" 1 "BcaRPlus Brake Started" 2 "BcaRPlus Braking is Ended" 3 "BcaRPlus Braking Error" ;
VAL_ 916 FCA_EQUIP 0 "FCA is not equipped" 1 "FCA is equipped" ;
VAL_ 1528 CR_Fatc_Cooldown 0 "Initial" 1 "Cooldown" ;
VAL_ 1528 CR_Fatc_MildCooldown 0 "Initial" 1 "Mild Cooldown" ;
VAL_ 1528 CR_Fatc_Warmup 0 "Initial" 1 "warmup" ;
VAL_ 1528 CR_Fatc_MildWarmup 0 "Initial" 1 "Mild Warmup" ;
VAL_ 1528 CF_Fatc_BlowerStatus 0 "Blower Off" 1 "Auto" 2 "Manual" 3 "invalid" ;
VAL_ 1528 CF_Fatc_DriverOnly 0 "Driver only Off" 1 "Driver only On" 2 "invalid" 3 "reserved" ;
VAL_ 1529 DATC_BlowerLevel 0 "Off" 1 "0 level" 2 "1 level" 3 "2 level" 4 "3 level" 5 "4 level" 6 "5 level" 7 "6 level" 8 "7 level" 9 "8 level" 10 "not used" 15 "invalid" ;
VAL_ 1529 CF_Fatc_AAFOpenReq 0 "Not-request" 1 "Open reqest" 2 "Not Used" 3 "Invalid" ;
VAL_ 1529 CF_Fatc_BatEwpOperReq 0 "not request" 1 "request" 3 "not used" ;
VAL_ 2015 FRM_FORMAT 2 "Single frame and should analyze next two data of this message" ;
VAL_ 2015 SID 40 "Disable transmission of normal CAN messages. (Stop normal CAN communication)" 41 "Enable transmission of normal CAN messages. (Resume normal CAN communication)" ;
VAL_ 2015 REQ_RESPONSE 0 "Reserved" 1 "Response required" 2 "No response required" ;
VAL_ 1530 CR_Wcs_ClassStat 1 "Class1" 2 "Class2" 4 "Indeterminate" ;
VAL_ 1510 CF_Ccm_LogicalNetwork 0 "False" 1 "True" ;
VAL_ 1510 CF_Ccm_CommClose 0 "False" 1 "True" ;
VAL_ 1510 CF_Ccm_PwmCheck 0 "False" 1 "True" ;
VAL_ 1510 CF_Ccm_EvseProc 0 "Finished" 1 "Ongoing" ;
VAL_ 1510 CF_Ccm_EvseVoltLimit 0 "False" 1 "True" ;
VAL_ 1510 CF_Ccm_EvsePoweLimit 0 "False" 1 "True" ;
VAL_ 1510 CF_Ccm_EvseCurrLimit 0 "False" 1 "True" ;
VAL_ 1510 CF_Ccm_EvseTransferPower 0 "False" 1 "True" ;
VAL_ 1510 CR_Ccm_EvseNoti 0 "None" 1 "StopCharging" 2 "ReNegotiation" ;
VAL_ 1510 CR_Ccm_EvseIsolStat 0 "Invalid" 1 "Safe" 2 "Warning" 3 "Fault" ;
VAL_ 1510 CR_Ccm_EvseTransferType 0 "AC_single_phase_core" 1 "AC_three_phase_core" 2 "DC_core" 3 "DC_extented" 4 "DC_combo_core" 5 "DC_dual" 6 "AC_core1p_DC_extended" 7 "AC_single_DC_core" 8 "AC_single_phase_three_phase_core_DC_extended" 9 "AC_core3p_DC_extended" 15 "Default" ;
VAL_ 1507 CR_VCU_EcoLvl 0 "Nomal (not display)" 1 "Fail (repair display)" ;
VAL_ 903 WHL_DIR_FL 0 "Unknown (Wheel moving stop state or Not applied wheel sensor for direction)" 1 "Forward direction" 2 "Backward direction" 3 "Error identifier" ;
VAL_ 903 WHL_DIR_FR 0 "Unknown (Wheel moving stop state or Not applied wheel sensor for direction)" 1 "Forward direction" 2 "Backward direction" 3 "Error identifier" ;
VAL_ 903 WHL_DIR_RL 0 "Unknown (Wheel moving stop state or Not applied wheel sensor for direction)" 1 "Forward direction" 2 "Backward direction" 3 "Error identifier" ;
VAL_ 903 WHL_DIR_RR 0 "Unknown (Wheel moving stop state or Not applied wheel sensor for direction)" 1 "Forward direction" 2 "Backward direction" 3 "Error identifier" ;
VAL_ 1278 POS_RangeAvgSpeed 0 "0x0~0xFE:Range camera average speed" 254 "0x0~0xFE:Range camera average speed" 255 "0xFF~0x1FE:Reserved" 510 "0xFF~0x1FE:Reserved" 255 "Invalid" ;
VAL_ 1278 POS_CurrentLane 0 "Unknown" 1 "Energy lane" 2 "Single lane road" 3 "Left most lane" 4 "Right most lane" 5 "One of middle over three lane" 6 "Reserved" 7 "Invalid" ;
VAL_ 1278 POS_PositionConfidence 0 "Highest confidence" 1 "Position confidence" 2 "Position confidence" 3 "Position confidence" 4 "Position confidence" 5 "Position confidence" 6 "Lowest confidence" 7 "Invalid" ;
VAL_ 1278 POS_PositionIndex 0 "Most probable position" 1 "Second candidate" 2 "Third candidate" 3 "Invalid" ;
VAL_ 1278 POS_PathIndex 0 "Unkown" 1 "Reserved" 2 "Reserved" 3 "Reserved" 4 "Reserved" 5 "Reserved" 6 "Reserved" 7 "Reserved" 8 "General path index" 9 "General path index" 10 "General path index" 11 "General path index" 12 "General path index" 13 "General path index" 14 "General path index" 15 "General path index" 16 "General path index" 17 "General path index" 18 "General path index" 19 "General path index" 20 "General path index" 21 "General path index" 22 "General path index" 23 "General path index" 24 "General path index" 25 "General path index" 26 "General path index" 27 "General path index" 28 "General path index" 29 "General path index" 30 "General path index" 31 "General path index" 32 "General path index" 33 "General path index" 34 "General path index" 35 "General path index" 36 "General path index" 37 "General path index" 38 "General path index" 39 "General path index" 40 "General path index" 41 "General path index" 42 "General path index" 43 "General path index" 44 "General path index" 45 "General path index" 46 "General path index" 47 "General path index" 48 "General path index" 49 "General path index" 50 "General path index" 51 "General path index" 52 "General path index" 53 "General path index" 54 "General path index" 55 "General path index" 56 "General path index" 57 "General path index" 58 "General path index" 59 "General path index" 60 "General path index" 61 "General path index" 62 "General path index" 63 "General path index" ;
VAL_ 1278 POS_CyclicCounter 0 "Cyclic counter" 1 "Cyclic counter" 2 "Cyclic counter" 3 "Cyclic counter" ;
VAL_ 1278 POS_Offset 0 "0x0~0x1FFE:Distance" 8190 "0x0~0x1FFE:Distance" 8191 "Invalid" ;
VAL_ 1278 POS_MessageType 0 "Reserved" 1 "Position" 2 "Segment" 3 "Stub" 4 "Profile Short" 5 "Profile Long" 6 "Meta Data" 7 "Invalid" ;
VAL_ 1516 C_InletLockStatus 0 "Unlock" 1 "Lock" ;
VAL_ 1516 C_Ign3Rly 0 "Off" 1 "On" ;
VAL_ 1516 C_InletFailStatus 0 "Normal" 1 "Error" ;
VAL_ 1516 C_CtrDrLockRly 0 "Off" 1 "Lock" ;
VAL_ 1516 C_CtrDrUnlockRly 0 "Off" 1 "Unlock" ;
VAL_ 1516 C_DrvDrUnlockRly 0 "Off" 1 "Unlock" ;
VAL_ 1516 C_Inlet_ServiceLamp_Req 0 "Off" 1 "On" ;
VAL_ 1516 C_FRECOState 0 "None" 1 "Set" ;
VAL_ 1516 C_DHVSeatOperationFB 0 "Init" 1 "Unused" 2 "DRV_Heat&Vent_OFF" 3 "DRV_Vent_Low" 4 "DRV_Vent_Mid" 5 "DRV_Vent_High" 6 "DRV_Heat_Low" 7 "DRV_Heat_Mid" 8 "DRV_Heat_High" 15 "Invalid" ;
VAL_ 1516 C_AHVSeatOperationFB 0 "Init" 1 "Unused" 2 "PASS_Heat&Vent_OFF" 3 "PASS_Vent_Low" 4 "PASS_Vent_Mid" 5 "PASS_Vent_High" 6 "PASS_Heat_Low" 7 "PASS_Heat_Mid" 8 "PASS_Heat_High" 15 "Invalid" ;
VAL_ 1516 C_RLHVSeatOperationFB 0 "Init" 1 "Unused" 2 "RLH_Heat&Vent_OFF" 3 "RLH_Vent_Low" 4 "RLH_Vent_Mid" 5 "RLH_Vent_High" 6 "RLH_Heat_Low" 7 "RLH_Heat_Mid" 8 "RLH_Heat_High" 15 "Invalid" ;
VAL_ 1516 C_RRHSeatOperationFB 0 "Init" 1 "Unused" 2 "RRH_Heat&Vent_OFF" 3 "RRH_Vent_Low" 4 "RRH_Vent_Mid" 5 "RRH_Vent_High" 6 "RRH_Heat_Low" 7 "RRH_Heat_Mid" 8 "RRH_Heat_High" 15 "Invalid" ;
VAL_ 1516 C_RRECOState 0 "None" 1 "Set" ;
VAL_ 1516 C_StrgWhlHeatedState 0 "Off" 1 "On" ;
VAL_ 1516 C_SBRMatSw 0 "Off (UnSeated)" 1 "On (Seated)" ;
VAL_ 1276 CF_Aaf31_ActFlapStatus 1 "CLOSE" 2 "OPEN" 3 "Unknown" ;
VAL_ 1277 CF_Aaf21_ActFlapStatus 1 "CLOSE" 2 "OPEN" 3 "Unknown" ;
VAL_ 1513 CF_CCM_ChgParamFlg 0 "False" 1 "True" ;
VAL_ 1513 CF_CCM_CableChkFlg 0 "False" 1 "True" ;
VAL_ 1513 CF_CCM_PreChgFlg 0 "False" 1 "True" ;
VAL_ 1513 CF_CCM_PwrDeliOnFlg 0 "False" 1 "True" ;
VAL_ 1513 CF_CCM_CurDemFlg 0 "False" 1 "True" ;
VAL_ 1513 CF_CCM_PwrDeliOffFlg 0 "False" 1 "True" ;
VAL_ 1513 CF_CCM_WeldDetectFlg 0 "False" 1 "True" ;
VAL_ 1512 CF_Ccm_EvseStatus 0 "EVSE_NotReady" 1 "EVSE_Ready" 2 "EVSE_Shutdown" 3 "EVSE_UtilityInterruptEvent" 4 "EVSE_IsolationMonitoringActive" 5 "EVSE_EmergencyShutdown" 6 "EVSE_Malfunction" 7 "Reserved 8-C" ;
VAL_ 1512 CF_Ccm_Error 0 "NO_ERROR" 1 "PLC_MAL_FUNCTION" 2 "SLAC_CNF_TIMEOUT" 3 "SLAC_ATTEN_FAILED" 4 "SDP_RSP_FAILED" 5 "V2G_MSG_TIMEOUT" 6 "V2G_COMMSETUP_TIMEOUT" 7 "V2G_CABLECHK_TIMEOUT" 8 "V2G_PRECHG_TIMEOUT" 9 "V2G_ONGOING_TIMEOUT" 10 "V2G_CAN_TIMEOUT" 11 "V2G_RSP_CODE_ERR" 12 "EVSE_STATUS_ERR" ;
VAL_ 1512 CF_Ccm_ChgFinished 0 "False" 1 "True" ;
VAL_ 1512 CF_Evse_ChgFinished 0 "False" 1 "True" ;
VAL_ 1426 CF_Vcu_DefrostCtr 0 "Deactivate defrost mode" 1 "Activate defrost mode" ;
VAL_ 1426 CF_Vcu_LowSocLp 0 "Lamp Off" 1 "Lamp On" ;
VAL_ 1426 CF_Vcu_DteOff 0 "None" 1 "DTE Off('---' Display)" ;
VAL_ 1426 CF_Vcu_SerLamp 0 "None" 1 "Service Lamp On" ;
VAL_ 1426 CF_Vcu_ChrgAlert 0 "Not display" 1 "Display" ;
VAL_ 1426 CF_Vcu_PwrDnMode 0 "None" 1 "Set" ;
VAL_ 1426 CF_Vcu_CruOnLamp 0 "Lamp Off" 1 "Lamp On" ;
VAL_ 1426 CF_Vcu_CruSetLamp 0 "Lamp Off" 1 "Lamp On" ;
VAL_ 1426 CF_Vcu_ThiBatTir 0 "Thin" 1 "Thick" ;
VAL_ 1426 CF_Vcu_LdcMod 0 "Charge Mode A" 1 "Charge Mode for Power Efficiency B" 2 "Discharge Mode for Power Efficiency C" ;
VAL_ 1426 CF_Vcu_ACnChr 0 "None" 1 "Permission" ;
VAL_ 1426 CF_Vcu_LdcInh 0 "None" 1 "LDC Off Request" ;
VAL_ 1426 CF_Vcu_BrkLpReq 0 "None" 1 "Lamp On Request" ;
VAL_ 1426 CF_Vcu_EvMod 0 "None" 1 "Vehicle Stop" 2 "EV Propulsion" 3 "Not used" 4 "Not used" 5 "Not used" 6 "Regeneration" 7 "Not used" 8 "Not used" 9 "Not used" ;
VAL_ 1427 TPMS_W_LAMP 0 "TPMS Malfunction Warning lamp OFF" 1 "TPMS Malfunction Warning lamp ON" 2 "TPMS Malfunction Warning lamp BLINKING(2Hz)" 3 "Reserved" ;
VAL_ 1427 TREAD_W_LAMP 0 "TREAD Warning lamp OFF" 1 "TREAD Warning lamp ON" 2 "TREAD Warning lamp BLINKING(2Hz)" 3 "Reserved" ;
VAL_ 1427 POS_FL_W_LAMP 0 "FL POSITION Warning lamp OFF" 1 "FL POSITION Warning lamp ON" ;
VAL_ 1427 POS_FR_W_LAMP 0 "FR POSITION Warning lamp OFF" 1 "FR POSITION Warning lamp ON" ;
VAL_ 1427 POS_RL_W_LAMP 0 "RL POSITION Warning lamp OFF" 1 "RL POSITION Warning lamp ON" ;
VAL_ 1427 POS_RR_W_LAMP 0 "RR POSITION Warning lamp OFF" 1 "RR POSITION Warning lamp ON" ;
VAL_ 1427 STATUS_TPMS 0 "inactive" 1 "active" 2 "reserved" 3 "reserved" 4 "reserved" 5 "reserved" 6 "reserved" 7 "reserved" ;
VAL_ 1427 UNIT 0 "psi" 1 "kpa" 2 "bar" 3 "reserved" ;
VAL_ 1424 CF_Ldc_Rdy 0 "Not Ready" 1 "Ready" ;
VAL_ 1424 CF_Ldc_Controllable 0 "Not Controllable" 1 "Controllable" ;
VAL_ 1424 CF_Ldc_12VCharge 0 "PWM off" 1 "PWM on" ;
VAL_ 1424 CF_Ldc_Pd_Stat 0 "-" 1 "LDC Power Derating Status" ;
VAL_ 1424 CF_Ldc_AuxBatWrnLamp 0 "Aux Bat warning lamp off" 1 "Aux Bat warning lamp request" ;
VAL_ 1424 CF_Ldc_AuxBatWrnAlarm 0 "Aux Bat warning alarm off" 1 "Aux Bat warning alarm request" ;
VAL_ 1424 CF_Ldc_AuxBatCharge_Rqst 0 "No Request" 1 "Aux Bat Charge request" ;
VAL_ 1424 CF_Ldc_AuxBatCharge_Reset 0 "No Request" 1 "IG3 Wake up Reset" ;
VAL_ 1424 CF_Ldc_Srvlamp_Rqst 0 "Normal status" 1 "Service lamp request" ;
VAL_ 1424 CF_Ldc_Flt 0 "Normal status" 1 "Fault status" ;
VAL_ 1424 CF_Ldc_AuxBatChg_State 0 "Default" 1 "Aux Bat Charge Activated" 2 "Aux Bat Charge Completed" 3 "Aux Bat Charge Inhibited" ;
VAL_ 1424 CF_Ldc_RadFanCnt 0 "Radiator FAN off" 1 "Radiator FAN on" ;
VAL_ 1424 CF_Ldc_Bat_dischrg 0 "Flag OFF" 1 "Flag ON" ;
VAL_ 1019 CF_Cms_PDStatus 0 "Connector Open" 1 "S3 Switch Off" 2 "PD Normal Status" 3 "PD Circuit Fault Status" ;
VAL_ 1019 CF_Cms_ChgFinished 0 "Not Finish" 1 "Finished" ;
VAL_ 1019 CF_Cms_EvseRdyState 0 "Not Wake up" 1 "Wake up" ;
VAL_ 1019 CF_Cms_Wrn 0 "No Warning" 1 "Warning" ;
VAL_ 1019 CF_Cms_Flt 0 "Normal" 1 "VCMS Fault Status" ;
VAL_ 1019 CF_Cms_Rdy 0 "Not Wake up" 1 "Wake up" ;
VAL_ 1019 CF_Cms_IG3DrvStat 0 "IG3 Relay Off" 1 "IG3 Relay On" ;
VAL_ 1019 CF_Cms_PlugConnect 0 "AC/DC Plug Disconnected" 1 "AC/DC Plug Connected" ;
VAL_ 1019 CF_Cms_S2SWOnStat 0 "S2 Switch Off" 1 "S2 Switch On" ;
VAL_ 1019 CF_Cms_ForcedDischReq 0 "Forced Discharge Off" 1 "Forced Discharge On" ;
VAL_ 1019 CF_Cms_MILReq 0 "MIL Off" 1 "MIL On" ;
VAL_ 1019 CF_Cms_VCRM_Req 0 "No request" 1 "Ser./MIL Lamp" 2 "Warning" 3 "reserved" ;
VAL_ 1019 CF_Cms_ServiceLampReq 0 "OFF" 1 "ON" ;
VAL_ 1019 CF_Cms_EvseFltStat 0 "Normal" 1 "Fault" ;
VAL_ 1019 CF_Cms_DCChargingStat 0 "Initial Value" 1 "DC Charging Status" ;
VAL_ 1019 CF_Cms_ACChargingStat 0 "Initial Value" 1 "AC Charging Status" ;
VAL_ 1019 CF_Cms_ImmeChgSwState 0 "Switch Off" 1 "Switch On" ;
VAL_ 1019 CF_Cms_ChargeInit 0 "Default" 1 "Initialize DC Charging Sequence" ;
VAL_ 1019 CF_Cms_ChargingCycle 0 "Charging Cycle Off" 1 "Charging Cycle On" ;
VAL_ 1020 CF_Cms_ChgStopAlarm 0 "Initial Value(Normal)" 1 "Check EVSE/Grid" 2 "Check Charge Cable Connection" 3 "Reserved" 4 "Reserved" 5 "Reserved" 6 "Reserved" 7 "Reserved" ;
VAL_ 1020 CF_Cms_PlcCpFlt 0 "No Fault" 1 "CP Fault" ;
VAL_ 1021 ESC_LVACtrl 0 "Inactive" 1 "Active" 2 "Reserved" 3 "Reserved" ;
VAL_ 1021 LVA_CLU 0 "No Display" 1 "Brake Boost Defected" 2 "Reserved" 3 "Reserved" 4 "Reserved" 5 "Reserved" 6 "Reserved" 7 "Reserved" ;
VAL_ 1431 CF_BMS_RdyForOBC 0 "Not Wake-up" 1 "Wake-up" ;
VAL_ 1431 CF_BMS_FltForOBC 0 "Not Fault" 1 "Fault" ;
VAL_ 1431 CF_BMS_MainRlyONstatForOBC 0 "Off" 1 "On" ;
VAL_ 1431 CF_BMS_ChgFinishedForOBC 0 "Normal" 1 "Charge Finish" ;
VAL_ 1431 CF_BMS_ChgFullForOBC 0 "Charging or emergency off" 1 "normal charging complete" ;
VAL_ 1431 CF_Bms_TargetSocFullChg 0 "Normal" 1 "Charge Finished" ;
VAL_ 1431 CF_Bms_NormalOperFlg 0 "Normal Operation 0" 1 "Normal Operation 1" ;
VAL_ 1431 CF_Bms_ChgLamp 0 "Normal" 1 "Main Rly On Status On" 2 "SOC 0~35" 3 "SOC 35~65" 4 "SOC 65~" 5 "Chargnig Complete" 6 "Charging Fail" 7 "Reservation Charging" ;
VAL_ 1431 CF_Bms_SupplyChg 0 "Normal" 1 "Supplementary Charging On" ;
VAL_ 1431 CF_BMS_NormalChgForOBC 0 "Normal" 1 "Abnormal Finish By OBC" 2 "Abnormal Finish By BMS" 3 "Abnormal Finish By Others" ;
VAL_ 1431 CF_Bms_IG3RlyOffEnable 0 "Normal" 1 "IG3 Rly Off Enable" ;
VAL_ 1022 CR_Cms_CpFltStat 0 "Init" 1 "Normal" 2 "Fault" ;
VAL_ 1428 CF_Bms_LowtempStatus 0 "Noraml" 1 "Low temperature" ;
VAL_ 1428 CF_Bms_ServiceLamp 0 "Off" 1 "Service Lamp On" ;
VAL_ 1428 CF_Bms_MainRlyOnStat 0 "Off" 1 "On" ;
VAL_ 1428 CF_Bms_Rly_Off_Req 0 "Noraml" 1 "Rly_Off_Req receive" ;
VAL_ 1428 CF_Bms_Flt 0 "Noraml" 1 "Fault" ;
VAL_ 1428 CF_Bms_Wrn 0 "Noraml" 1 "Warning" ;
VAL_ 1428 CF_Bms_Ctrb 0 "Uncontrollabel" 1 "Controllable" ;
VAL_ 1428 CF_Bms_Rdy 0 "Not Ready" 1 "BMS Control Board Ready" ;
VAL_ 1428 CF_Bms_SupplyChgStat 0 "Not operating" 1 "operation" 2 "complete" 3 "fail" ;
VAL_ 1428 CR_Bms_WinterMode 0 "Installed & Off" 1 "Installed & On" 2 "Uninstalled (No Heater Vehicle)" 3 "Invalid" ;
VAL_ 1428 CF_Bms_CshActFromAcu 0 "Normal" 1 "crash active signal set  from ACU" ;
VAL_ 1428 CF_Bms_HighTempStatus 0 "Normal" 1 "High Temp Status" ;
VAL_ 1428 CF_Bms_HvIntlockReq 0 "Not Request" 1 "Request" ;
VAL_ 1428 CF_Bms_RlyWeld 0 "None" 1 "relay welding" ;
VAL_ 1428 CF_Bms_LdcInh 0 "Noraml" 1 "LDC Inhibit" ;
VAL_ 1428 CF_Bms_FulChgSts 0 "None" 1 "Fully Charged" ;
VAL_ 1428 CF_Bms_ChgSts 0 "None" 1 "Charging" ;
VAL_ 1429 CF_BMS_PrechgStatus 0 "None" 1 "Precharging" ;
VAL_ 1429 CF_Bms_StdCha 0 "None" 1 "Standard Charging" ;
VAL_ 1429 CF_Bms_FstCha 0 "None" 1 "Fast Charging" ;
VAL_ 1429 CF_Bms_StdCha_120V 0 "None" 1 "Standard Charging By 120V" ;
VAL_ 1429 CR_Bms_FanSpdStp 0 "None" 1 "1step" 2 "2step" 3 "3step" 4 "4step" 5 "5step" 6 "6step" 7 "7step" 8 "8step" 9 "9step" ;
VAL_ 1432 CF_Bms_LowOutTempStatus 0 "default" 1 "Flag set" ;
VAL_ 1432 CF_Bms_MotPwmOnReq 0 "Normal" 1 "Motor Pwm On Request" ;
VAL_ 1432 CF_Bms_IsolDetectOper 0 "Normal" 1 "Isolation Detect Operation" ;
VAL_ 1432 CF_Bms_QuickChgStartFlag 0 "None" 1 "Charging" ;
VAL_ 1432 CF_Bms_ClimateOffReq 0 "Default" 1 "Flag set" ;
VAL_ 1432 CF_Bms_PwrderatingFlg 0 "Normal" 1 "Flag set" ;
VAL_ 1432 CF_Bms_ChgStopFlag 0 "Normal" 1 "Excess of CV Voltage" 2 "Low target SOC" 3 "Reserved" ;
VAL_ 1433 CF_Bms_EvReady 0 "Not ready" 1 "Ready" ;
VAL_ 1433 CF_Bms_CabinConditioning 0 "Normal" 1 "Cabin Conditioning" ;
VAL_ 1433 CF_Bms_BatHeatStat 0 "Normal" 1 "Heat Operation" ;
VAL_ 1433 CF_Bms_NoError 0 "Error" 1 "No Error" ;
VAL_ 1433 CF_Bms_Fail_Temp 0 "Normal" 1 "Fail" ;
VAL_ 1433 CF_Bms_FAILED_EVShiftPosition 0 "Normal" 1 "Fail" ;
VAL_ 1433 CF_Bms_Fail_Conlock 0 "Normal" 1 "Fail" ;
VAL_ 1433 CF_Bms_Fail_Evmalf 0 "Normal" 1 "Fail" ;
VAL_ 1433 CF_Bms_Fail_CurrDiff 0 "Normal" 1 "Fail" ;
VAL_ 1433 CF_Bms_Fail_VoltRange 0 "Normal" 1 "Fail" ;
VAL_ 1433 CF_Bms_Fail_ChgSysIncom 0 "Normal" 1 "Fail" ;
VAL_ 1433 CF_Bms_NoData 0 "Normal" 1 "No Data" ;
VAL_ 1433 CF_Bms_ReadyToCharge 0 "Normal" 1 "Ready To Charge" ;
VAL_ 1433 CF_Bms_BulkChgComplete 0 "Normal" 1 "Quick Charging Complete" ;
VAL_ 1433 CF_Bms_ChgComplete 0 "Normal" 1 "Standard Charging Complete" ;
VAL_ 1433 CF_Bms_ChgFinished 0 "Normal" 1 "Charge finish" ;
VAL_ 1433 CF_Bms_PreparationStatusForPLC 0 "Normal" 1 "Ready For PLC" ;
VAL_ 1433 CF_Bms_ReadyForCurDem 0 "Normal" 1 "Ready For Current Demand" ;
VAL_ 1433 CF_Bms_RlyWeldDetectionReq 0 "False" 1 "True" ;
VAL_ 1014 BLA_CTL 0 "No request" 1 "Activate brake lights" 2 "Reserved" 3 "Reserved" ;
VAL_ 1167 HU_DATC_ADSOnOffSet 0 "Function Off" 1 "Function On" 2 "reserved" 3 "Invalid" ;
VAL_ 1168 EPB_I_LAMP 0 "Release State (EPB/ AVH)" 1 "Apply State (EPB)" 2 "Dynamic Braking (EPB) or Driver Action Requested" ;
VAL_ 1168 EPB_F_LAMP 0 "No failure" 1 "Failure detected or in diagnosis mode" 2 "EOL configuration not done or Emergency released" 3 "Reserved" ;
VAL_ 1168 EPB_ALARM 0 "Off" 1 "Comfortable tone (Sound once)" 2 "Uncomfortable tone" 3 "Reserved" ;
VAL_ 1168 EPB_CLU 0 "Off" 1 "EPB is in maintenance mode" 2 "Driver tries to DAR but safety condition is not satisfied" 3 "EPB applies by ESC request" ;
VAL_ 1168 EPB_SWITCH 0 "Neutral position" 1 "Apply position (pull)" 2 "Release position (push)" 3 "Switch failure" ;
VAL_ 1168 EPB_RBL 0 "No request" 1 "Request to turn on rear brake lights" ;
VAL_ 1168 EPB_STATUS 0 "See details in EPB_FRC_ERR" 1 "Released" 2 "Clamped" 3 "Clamping in progress without switch" 4 "Releasing in progress without switch" 5 "Dynamic braking via EPB" 6 "Releasing in progress by switch" 7 "Clamping in progress by switch" ;
VAL_ 1168 EPB_FRC_ERR 0 "No failure" 1 "Clamp position not reached" 2 "Emergency release" 3 "Force not measurable (e.g. sensor failure)" ;
VAL_ 1168 EPB_DBF_STAT 0 "EPB_DBF_REQ signal is valid" 1 "EPB_DBF_REQ signal is invalid" ;
VAL_ 1168 ESP_ACK 0 "Idle / No acknowledge" 1 "Acknowledge for external ESC request" ;
VAL_ 1168 EPB_DBF_REQ 0 "No Request" 1 "Dynamic braking request" ;
VAL_ 1168 EPB_FAIL 0 "Not valid" 1 "EPB No failure" 2 "EPB Initialization State" 3 "EPB Diagnostic" 4 "EPB Temporarily Not Available" 5 "EPB Permanently Not Available" ;
VAL_ 1168 EPB_FORCE 0 "EPB Fully released" ;
VAL_ 1410 CF_OLdc_AuxBatWrnLamp 0 "Aux Bat warning lamp off" 1 "Aux Bat warning lamp request" ;
VAL_ 1410 CF_OLdc_AuxBatWrnAlarm 0 "Aux Bat warning alarm off" 1 "Aux Bat warning alarm request" ;
VAL_ 1410 CR_OLdc_LoadPwrSum 255 "Error" ;
VAL_ 1169 CF_Bms_ChgLamp 0 "Normal" 1 "Main Rly On Status On" 2 "SOC 0~35" 3 "SOC 35~65" 4 "SOC 65~" 5 "Chargnig Complete" 6 "Charging Fail" 7 "Reservation Charging" ;
VAL_ 1171 CR_Bms_FanSpdStp 0 "None" 1 "1step" 2 "2step" 3 "3step" 4 "4step" 5 "5step" 6 "6step" 7 "7step" 8 "8step" 9 "9step" ;
VAL_ 1171 CF_BMS_NormalChgForOBC 0 "Normal" 1 "Abnormal Finish By OBC" 2 "Abnormal Finish By BMS" 3 "Abnormal Finish By Others" ;
VAL_ 1171 CF_Bms_VCRM_Req 0 "Normal" 1 "Service Lamp On" 2 "Low SOC" 3 "reserved" ;
VAL_ 1171 CF_Bms_FstCha 0 "None" 1 "Fast Charging" ;
VAL_ 1171 CF_Bms_QcRlyOnStatForQcs 0 "Off" 1 "On" ;
VAL_ 1171 CF_BMS_QcsChgFinished 0 "Normal" 1 "Charge Finish" ;
VAL_ 1171 CF_Bms_FstEvseFltAlram 0 "Normal" 1 "Alraming By QCS Fault" ;
VAL_ 1414 CF_Evp1_State 0 "EVP is not defective" 1 "EVP is defective" ;
VAL_ 1414 CF_Evp1_DefMode 0 "Nomal" 1 "Under Vacuum" 2 "Over Current" 3 "Low Current" 4 "Motor Short" 5 "Overrun" 6 "Reserved" 7 "Reserved" ;
VAL_ 1414 CF_Evp1_RunChk 0 "None" 1 "Master Running" 2 "Slave Running" 3 "Dual Running" 4 "Reserved" 5 "Reserved" 6 "Reserved" 7 "Reserved" ;
VAL_ 765 FLAG_TQI_TCS 0 "Positive" 1 "Negative" ;
VAL_ 765 FLAG_TQI_MSR 0 "Positive" 1 "Negative" ;
VAL_ 765 FLAG_TQI_SLW_TCS 0 "Positive" 1 "Negative" ;
VAL_ 765 TCS_REQ 0 "Passive" 1 "TCS/ESC control active" ;
VAL_ 765 MSR_C_REQ 0 "Passive or TCS function" 1 "MSR control active" ;
VAL_ 765 TCS_MFRN 0 "Using both TQI_TCS and TQI_SLW_TCS" 1 "Using TQI_TCS only (Not using TQI_SLW_TCS)" ;
VAL_ 765 TCS_GSC 0 "passive (gear change allowed)" 1 "active (gear change not allowed)" ;
VAL_ 1412 CF_Aaf_ActFlapStatus 1 "CLOSE" 2 "OPEN" 3 "Unknown" ;
VAL_ 1412 CF_Aaf_ModeStatus 0 "Normal Mode" 1 "High Speed Mode" 2 "High Performance Mode" 3 "HS & HP Mode" 4 "Coast Down Mode" 5 "Fail Safety Mode" 6 "Safe Mode" 7 "Reserved" ;
VAL_ 1412 CF_Aaf_WrnLamp 0 "Warning Lamp/Message Off" 1 "Warning Lamp/Message On" ;
VAL_ 1412 CF_Aaf_MilOnReq 0 "MIL OFF" 1 "MIL ON" ;
VAL_ 1412 CF_Aaf_ActFlapTarget 0 "Target Close" 1 "Target Open" ;
VAL_ 1412 CF_Aaf_ActFlapTarget_2 0 "Target Close" 1 "Target Open (25%)" 2 "Target Open (50%)" 3 "Target Open (100%)" ;
VAL_ 1175 CR_Bms_HeaderID_Slave 17 "Valve1 Request (BMS)" 18 "Valve1 Response1 (Battery)" 19 "Valve2 Request (BMS)" 20 "Valve2 Response1 (PE)" 21 "EWP1 Request (BMS)" 22 "EWP1 Response1 (Battery)" 23 "Reserved" 34 "Valve1 Response2 (Battery)" 36 "Valve2 Response2 (PE)" 38 "EWP1 Response2 (Battery)" ;
VAL_ 1175 CF_Valve1_Checksum_Fault 0 "Normal" 1 "Response1 Check Error" 2 "Response2 Check Error" 3 "All Responses Check Error" ;
VAL_ 1175 CF_Valve2_Checksum_Fault 0 "Normal" 1 "Response1 Check Error" 2 "Response2 Check Error" 3 "All Responses Check Error" ;
VAL_ 1175 CF_EWP1_Checksum_Fault 0 "Normal" 1 "Response1 Check Error" 2 "Response2 Check Error" 3 "All Responses Check Error" ;
VAL_ 1176 CR_Valve1_Status 0 "Ready" 1 "Act" 2 "Complete" 3 "Stop" 7 "Fault" ;
VAL_ 1176 CR_Valve1_FaultCode 0 "Normal" 1 "Low Voltage Fail" 2 "Over Voltage Fail" 3 "HallSenor Fail" 4 "Sensing Fail" 5 "Motor Lock/Short Fail" 6 "Motor Open" 7 "LIN Communucation Fail" 8 "Motor OverCurrent Fail" ;
VAL_ 1176 CR_Valve2_Status 0 "Ready" 1 "Act" 2 "Complete" 3 "Stop" 7 "Fault" ;
VAL_ 1176 CR_Valve2_FaultCode 0 "Normal" 1 "Low Voltage Fail" 2 "Over Voltage Fail" 3 "Hall Sensor Fail" 4 "Sensing Fail" 5 "Motor Lock/Short" 6 "Motor Open" 7 "LIN Communication Fail" 8 "Motor OverCurrent Fail" ;
VAL_ 1418 Msg_Group_Num6 0 "Cyclic count every 1 frame" 1 "Cyclic count every 1 frame" 2 "Cyclic count every 1 frame" 3 "Cyclic count every 1 frame" 4 "Cyclic count every 1 frame" 5 "Cyclic count every 1 frame" 6 "Time out" 7 "Invalid" ;
VAL_ 1418 CurPosTraffic 0 "No data" 1 "Congested" 2 "Delayed" 3 "Light" 4 "Reserved" 5 "Reserved" 6 "Reserved" 7 "Reserved" 8 "Reserved" 9 "Reserved" 10 "Reserved" 11 "Reserved" 12 "Reserved" 13 "Reserved" 14 "Reserved" 15 "Invalid" ;
VAL_ 1418 CurTrafLength 0 "0x000~0x1388:Distance" 5000 "0x000~0x1388:Distance" 16383 "Invalid" ;
VAL_ 1418 NextTrafDistance 0 "0x000~0x1388:Distance" 5000 "0x000~0x1388:Distance" 5001 "0x1389~0x3FFE:Reserved" 16382 "0x1389~0x3FFE:Reserved" 16383 "Invalid" ;
VAL_ 1418 NextPosTraffic 0 "No data" 1 "Congested" 2 "Delayed" 3 "Light" 4 "Reserved" 5 "Reserved" 6 "Reserved" 7 "Reserved" 8 "Reserved" 9 "Reserved" 10 "Reserved" 11 "Reserved" 12 "Reserved" 13 "Reserved" 14 "Reserved" 15 "Invalid" ;
VAL_ 1178 Navi_AirConditionType 0 "None" 1 "Defined Value" 2 "Defined Value" 3 "Defined Value" 4 "Defined Value" 5 "Defined Value" 6 "Defined Value" 7 "Defined Value" 8 "Defined Value" 9 "Defined Value" 10 "Defined Value" 11 "Defined Value" 12 "Defined Value" 13 "Defined Value" 14 "Defined Value" 15 "Defined Value" 16 "Defined Value" 17 "Defined Value" 18 "Defined Value" 19 "Defined Value" 20 "Defined Value" 21 "Defined Value" 22 "Defined Value" 23 "Defined Value" 24 "Defined Value" 25 "Defined Value" 26 "Defined Value" 27 "Defined Value" 28 "Defined Value" 29 "Defined Value" 30 "Defined Value" 31 "Defined Value" 32 "Defined Value" 33 "Defined Value" 34 "Defined Value" 35 "Defined Value" 36 "Defined Value" 37 "Defined Value" 38 "Defined Value" 39 "Defined Value" 40 "Defined Value" 41 "Defined Value" 42 "Defined Value" 43 "Defined Value" 44 "Defined Value" 45 "Defined Value" 46 "Defined Value" 47 "Defined Value" 48 "Defined Value" 49 "Defined Value" 50 "Defined Value" 51 "Defined Value" 52 "Defined Value" 53 "Defined Value" 54 "Defined Value" 55 "Defined Value" 56 "Defined Value" 57 "Defined Value" 58 "Defined Value" 59 "Defined Value" 60 "Defined Value" 61 "Defined Value" 62 "Defined Value" 63 "Invalid" ;
VAL_ 1178 Navi_AirConditionWarning 0 "Unknown" 1 "On(Close)" 2 "Off" 3 "Invalid" ;
VAL_ 1179 MUTETIMER_FL 0 "0min" 1 "2min" 2 "4min" 3 "6min" 4 "8min" 5 "10min" 6 "12min" 7 "14min" 8 "16min" 9 "18min" 10 "RF Mute On" 11 "Reserved" 12 "Reserved" 13 "Reserved" 14 "Reserved" 15 "Error" ;
VAL_ 1179 MUTETIMER_FR 0 "0min" 1 "2min" 2 "4min" 3 "6min" 4 "8min" 5 "10min" 6 "12min" 7 "14min" 8 "16min" 9 "18min" 10 "RF Mute On" 11 "Reserved" 12 "Reserved" 13 "Reserved" 14 "Reserved" 15 "Error" ;
VAL_ 1179 MUTETIMER_RL 0 "0min" 1 "2min" 2 "4min" 3 "6min" 4 "8min" 5 "10min" 6 "12min" 7 "14min" 8 "16min" 9 "18min" 10 "RF Mute On" 11 "Reserved" 12 "Reserved" 13 "Reserved" 14 "Reserved" 15 "Error" ;
VAL_ 1179 MUTETIMER_RR 0 "0min" 1 "2min" 2 "4min" 3 "6min" 4 "8min" 5 "10min" 6 "12min" 7 "14min" 8 "16min" 9 "18min" 10 "RF Mute On" 11 "Reserved" 12 "Reserved" 13 "Reserved" 14 "Reserved" 15 "Error" ;
VAL_ 1423 CR_LDC_LoadPwrSum 255 "Error" ;
VAL_ 1423 CF_Ldc_TmpLmt 0 "-" 1 "LDC temperature Limit Status" ;
VAL_ 1423 CF_Ldc_CurLmt 0 "-" 1 "LDC Current Limit Status" ;
VAL_ 1423 CF_Vb_UV 0 "-" 1 "Vb under voltage Status" ;
VAL_ 1423 CF_Vb_OV 0 "-" 1 "Vb over voltage Status" ;
VAL_ 1423 CF_Ldc_CurChaMode 0 "A Mode" 1 "B Mode" 2 "C Mode" 3 "13.9V Static Voltage Control" ;
VAL_ 1423 CF_Ldc_BmsMsgLost 0 "Normal status" 1 "BMS Message lost" ;
VAL_ 1423 CF_Ldc_McuMsgLost 0 "Normal status" 1 "MCU Message lost" ;
VAL_ 1423 CF_Ldc_VCUMsgLost 0 "Normal status" 1 "VCU Message lost" ;
VAL_ 1422 CF_OBC_Asw_DevStep 1 "T-CAR" 2 "Proto" 3 "P1" 4 "P2" 5 "SOP" ;
VAL_ 1422 CF_OBC_Asw_Mode 0 "Test Rom" 1 "Formal Rom" ;
VAL_ 1422 CF_OBC_InletMode 0 "UNLOCK" 1 "LOCK" 2 "AUTOLOCK" 3 "UNLOCK_REQ" 4 "LOCK_REQ" 5 "FAULT" ;
VAL_ 1422 CF_OBC_InletPlugMode 0 "Init" 1 "UnPlugged" 2 "Plugged" ;
VAL_ 1422 CF_OBC_InletSwMode 0 "Auto Mode" 1 "Lock Mode" ;
VAL_ 1422 CF_OBC_GPSChg_InCurMode 0 "Max" 1 "Decreasing" 2 "Min" ;
VAL_ 1422 CF_OBC_EVSE_InCurMode 0 "Max" 1 "Decreasing" 2 "Min" ;
VAL_ 1422 CF_OBC_ICCB_InCurMode 0 "Max" 1 "Decreasing" 2 "Min" ;
VAL_ 1422 CF_OBC_Plug_Type 0 "Default" 1 "Domestic/USA" 2 "Europe" 3 "China" ;
VAL_ 1422 CF_OBC_InletUnlock_Inh 0 "None" 1 "Inhit" ;
VAL_ 1422 CF_OBC_InletLock_Req 0 "Unlock Confirm Status" 1 "Lock Confirm Status" 2 "Unlock Req" 3 "Lock Req" ;
VAL_ 1422 CF_OBC_ChgLampOffReqForBMS 0 "Not request" 1 "ChgLampOff Reqest" ;
VAL_ 1422 CF_OBC_PLC_CP_FAULT 0 "CLEAR" 1 "SET" ;
VAL_ 1422 CF_OBC_IG3RlyMd 0 "Wake Init" 1 "WAKEUP_CP" 2 "WAKEUP_OBC_IG3 (IG on)" 3 "WAKEUP_SJB_IG3 (Door Open)" 4 "WAKEUP_VCU_IG3" 5 "WAKEUP_TMU_IG3" 6 "WAKEUP_OTHER_IG3" 7 "WAKEUP_OTHER_IG3OFF" ;
VAL_ 1182 CF_CDM_ChgDrSwFrt 0 "Default" 1 "Close" 2 "Open" 3 "Invalid" ;
VAL_ 1182 CF_CDM_ImmeChgSw 0 "Default" 1 "Off" 2 "On" 3 "Invalid" ;
VAL_ 1459 C_EV_SpeedLimitOnOff 0 "Off(Default)" 1 "On" 2 "reserved" 3 "invalid" ;
VAL_ 1459 C_EV_NormalClimateLimit 0 "Off(Default)" 1 "ClimateLimitOn" 2 "reserved" 3 "invalid" ;
VAL_ 1459 C_EV_SportClimateLimit 0 "Off(Default)" 1 "ClimateLimitOn" 2 "reserved" 3 "invalid" ;
VAL_ 1459 C_EV_EcoClimateLimit 0 "Off(Default)" 1 "ClimateLimitOn" 2 "reserved" 3 "invalid" ;
VAL_ 1459 C_EV_NormalRegenrationLevel 0 "Low" 1 "Standard" 2 "High" 3 "Invalid" ;
VAL_ 1459 C_EV_SportRegenrationLevel 0 "Low" 1 "Standard" 2 "High" 3 "Invalid" ;
VAL_ 1459 C_EV_EcoRegenrationLevel 0 "Low" 1 "Standard" 2 "High" 3 "Invalid" ;
VAL_ 1459 C_EV_ClimateScnOnOff 0 "Off(Default)" 1 "ClimateScreenOn" 2 "reserved" 3 "invalid" ;
VAL_ 1459 C_EV_MaxSpeed 0 "0x0~0xFE:Speed Value" 254 "0x0~0xFE:Speed Value" 255 "invalid" ;
VAL_ 1459 CF_TMU_GPSChg_InCurModeState 0 "Max" 1 "Decreasing" 2 "Min" 3 "Invalid" ;
VAL_ 1459 HU_EV_GpsSchedUpdateRes 0 "non-Matching" 1 "Matching" 2 "Reserved" 3 "Invalid" ;
VAL_ 1459 HU_EV_GpsSched_State 0 "OFF" 1 "ON" 2 "Reserved" 3 "Invalid" ;
VAL_ 1459 HU_EV_GpsSched_ChgAir 0 "Not Use (Off)" 1 "Use (On)" 2 "Reserved" 3 "Invalid" ;
VAL_ 1459 CF_AVN_EVReset 0 "Default" 1 "USM Reset" 2 "Reserved" 3 "Invalid" ;
VAL_ 1460 HU_TempUnit 0 "off" 1 "¡É (Centigrade)" 2 "¢µ (Fahrenheit)" 3 "Invalid" ;
VAL_ 1460 CF_AVN_ProfileIDRValue 0 "Default" 1 "Guest" 2 "Profile 1" 3 "Profile 2" 4 "reserved" 5 "reserved" 6 "reserved" 7 "reserved" 8 "reserved" 9 "reserved" 10 "reserved" 11 "reserved" 12 "reserved" 13 "reserved" 14 "reserved" 5 "Invalid" ;
VAL_ 1190 CF_AVN_CluUSMReset 0 "Defualt" 1 "Reset" ;
VAL_ 1462 CF_Gway_RrLftSeatBeltSw 0 "Unbelted" 1 "Belted" ;
VAL_ 1462 CF_Gway_RrCtrSeatBeltSw 0 "Unbelted" 1 "Belted" ;
VAL_ 1462 CF_Gway_RrRtSeatBeltSw 0 "Unbelted" 1 "Belted" ;
VAL_ 1464 C_FRSeatTumblerSW 0 "Default" 1 "Up" 2 "Down" 3 "Invalid" ;
VAL_ 1464 C_FLSeatTumblerSW 0 "Default" 1 "Up" 2 "Down" 3 "Invalid" ;
VAL_ 1464 DATC_FRWndShldHtSW 0 "Off" 1 "On" ;
VAL_ 1464 DATC_WhistlelNoise 0 "Off (Default)" 1 "On (Whistle Noise Prevent)" ;
VAL_ 1193 CR_Datc_DRSeatHeat_USM_Set 0 "Default" 1 "Off" 2 "On" 3 "Invalid" ;
VAL_ 1193 C_AutoLeverManualSW 0 "Not Manual" 1 "Manual" 2 "Manual +" 3 "Manual -" ;
VAL_ 1193 C_DiagnConnStatus 0 "Default" 1 "DiagMsgNotExist" 2 "DiagMsgExist" 3 "Error" ;
VAL_ 1193 C_PTGMOpt 0 "Off" 1 "On(PTG Option)" ;
VAL_ 1193 C_PTGOpnClsState 0 "Default" 1 "Closing Operation" ;
VAL_ 1193 C_RKETeleEngineRunning 0 "Off" 1 "RKE Tele Running" ;
VAL_ 1466 CF_AVN_AuxBatChargeNValueSet 0 "Default" 1 "Disable" 2 "Enable" 3 "Invalid" ;
VAL_ 1466 CF_AVN_SmartRegenNValueSet 0 "Default" 1 "Disabled(Off)" 2 "Enabled(On)" 3 "Invalid" ;
VAL_ 1466 CF_AVN_RestModeNValueSet 0 "Default" 1 "Disabled(Off)" 2 "Enabled(On)" 3 "Invalid" ;
VAL_ 1467 DATC_Beep1Mode 0 "Beep1 mode Off" 1 "Beep1 mode On" 2 "Unused" 3 "Invalid" ;
VAL_ 1468 DATC_AMP_Beep1VolumeStep 0 "0x0~0xFD:Beep1 Volume" 253 "0x0~0xFD:Beep1 Volume" 254 "Req.amp.Beep1 settings" 255 "Invalid" ;
VAL_ 1468 DATC_AMP_Beep1Frequency 0 "0x0~0xFFFE:Beep1 Frequency" 65534 "0x0~0xFFFE:Beep1 Frequency" 65535 "Invalid" ;
VAL_ 1468 DATC_AMP_Beep1Ch_OutputMask 65535 "Invalid" ;
VAL_ 1468 DATC_AMP_Beep1DurationOn 0 "0x0~0xFE:Beep1 On-time" 254 "0x0~0xFE:Beep1 On-time" 255 "Invalid" ;
VAL_ 1468 DATC_AMP_Beep1DurationOff 0 "0x0~0xFE:Beep1 OFF-time" 254 "0x0~0xFE:Beep1 OFF-time" 255 "Invalid" ;
VAL_ 1468 DATC_AMP_Beep1NumberOfCycles 0 "0x0~0xFE:Beep1 Cycle Number" 254 "0x0~0xFE:Beep1 Cycle Number" 255 "Invalid" ;
VAL_ 1469 HU_DATC_Beep1VolumeStep 0 "0x0~0xFD:Beep1 Volume" 253 "0x0~0xFD:Beep1 Volume" 254 "Req.amp.Beep1 settings" 255 "Invalid" ;
VAL_ 1469 HU_DATC_Beep1Frequency 0 "0x0~0xFFFE:Beep1 Frequency" 65534 "0x0~0xFFFE:Beep1 Frequency" 65535 "Invalid" ;
VAL_ 1469 HU_DATC_Beep1Ch_OutputMask 65535 "Invalid" ;
VAL_ 1469 HU_DATC_Beep1DurationOn 0 "0x0~0xFE:Beep1 On-time" 254 "0x0~0xFE:Beep1 On-time" 255 "Invalid" ;
VAL_ 1469 HU_DATC_Beep1DurationOff 0 "0x0~0xFE:Beep1 Off-time" 254 "0x0~0xFE:Beep1 Off-time" 255 "Invalid" ;
VAL_ 1469 HU_DATC_Beep1NumberOfCycles 0 "0x0~0xFE:Beep1 Cycle Number" 254 "0x0~0xFE:Beep1 Cycle Number" 255 "Invalid" ;
VAL_ 1202 CF_AVN_FCANValueSet 0 "Default(NoneFCA)" 1 "Off" 2 "Warning" 3 "Assist" 4 "Reserved" 5 "Reserved" 6 "Reserved" 7 "Invalid" ;
VAL_ 1202 CF_AVN_PasSpkrLvNValueSet 0 "Default" 1 "Level1" 2 "Level2" 3 "Level3" 4 "Reserved" 5 "Reserved" 6 "Reserved" 7 "Invalid" ;
VAL_ 1202 CF_AVN_SCCDrvModeNValueSet 0 "Default" 1 "Comfort" 2 "Normal" 3 "Dynamic" 4 "Reserved" 5 "Reserved" 6 "Reserved" 7 "Invalid" ;
VAL_ 1202 CF_AVN_DAWModeNValueSet 0 "Default" 1 "Off" 2 "Reserved" 3 "Normal" 4 "Early" 5 "Reserved" 6 "Reserved" 7 "Invalid" ;
VAL_ 1202 CF_AVN_HDA_LFANValueSet 0 "Default" 1 "Function Off" 2 "Function On" 3 "Invalid(Fail)" ;
VAL_ 1202 CF_AVN_BCWNValueSet 0 "Default" 1 "Off" 2 "Warning" 3 "Invalid" ;
VAL_ 1202 CF_AVN_SEANValueSet 0 "Default" 1 "Disable" 2 "Enable" 3 "Invalid" ;
VAL_ 1202 CF_AVN_NSCCCamNValueSet 0 "Default" 1 "Disable" 2 "Enable" 3 "Invalid" ;
VAL_ 1202 CF_AVN_BCANValueSet 0 "Default" 1 "Off" 2 "Warning" 3 "Assist" 4 "Reserved" 5 "Reserved" 6 "Reserved" 7 "Invalid" ;
VAL_ 1202 CF_AVN_ISLWNValueSet 0 "Default" 1 "Disable" 2 "Enable" 3 "Invalid" ;
VAL_ 1202 CF_AVN_WarningTimingNValueSet 0 "Default" 1 "Late" 2 "Normal" 3 "Reserved" 4 "Reserved" 5 "Reserved" 6 "Reserved" 7 "Invliad" ;
VAL_ 1202 CF_AVN_NCC_USM_set 0 "Default" 1 "On" 2 "Off" 3 "Invalid" ;
VAL_ 1202 CF_AVN_TirePressUnitNValueSet 0 "Default" 1 "psi" 2 "kpa" 3 "bar" 4 "reserved" 5 "reserved" 6 "reserved" 7 "Invalid" ;
VAL_ 1202 CF_AVN_RCCANValueSet 0 "Default" 1 "Off" 2 "Warning" 3 "Assist" 4 "Reserved" 5 "Reserved" 6 "Reserved" 7 "Invalid" ;
VAL_ 1202 CF_AVN_NSCCCrvNValueSet 0 "Default" 1 "Disable" 2 "Enable" 3 "Invalid" ;
VAL_ 1202 CF_AVN_BCWSndWanNValueSet 0 "Off" 1 "Disable" 2 "Enable" 3 "Invalid" ;
VAL_ 1202 CF_AVN_RCCWNValueSet 0 "Default" 1 "Off" 2 "Warning" 3 "Invalid" ;
VAL_ 1202 CF_AVN_LkaModeNValueSet 0 "Default" 1 "LDW mode" 2 "LKA" 4 "Reserved" 5 "Reserved" 6 "Reserved" 7 "Invalid" ;
VAL_ 1440 CF_Ods_IDRcv 0 "Request to send ODS Identifier" 1 "Acknowledgement for the Correct ODS Identifier Received" ;
VAL_ 1440 CF_PasBkl_FltStat 0 "No Fault" 1 "Fault condition exists" ;
VAL_ 1440 CF_DriBkl_FltStat 0 "No Fault" 1 "Fault condition exists" ;
VAL_ 1440 CF_PasBkl_Stat 0 "Passenger Seat Belt Not Latched" 1 "Passenger Seat Belt Latched" ;
VAL_ 1440 CF_DriBkl_Stat 0 "Driver Seat Belt Not Latched" 1 "Driver Seat Belt Latched" ;
VAL_ 1440 CF_SWL_Ind 0 "Warning Lamp on" 1 "Warning Lamp off" 2 "Warning Lamp flash" 3 "Not used" ;
VAL_ 1440 CF_Acu_FltStat 0 "Fault status is active" 1 "Fault status is historic" 2 "Fault does not exist" 3 "Not used" ;
VAL_ 1440 CF_Acu_ExtOfSab 0 "ACU EOL Programming Mode" 1 "Side(or Side/Curtain) Airbag doesn't exist." 2 "Side(or Side/Curtain) Airbag exists." 3 "Not used" ;
VAL_ 1443 CR_Bms_EVTransferType 0 "AC_single_phase_core" 1 "AC_three_phase_core" 2 "DC_core" 3 "DC_extented" 4 "DC_combo_core" 5 "DC_dual" 6 "AC_core1p_DC_extended" 7 "AC_single_DC_core" 8 "AC_single_phase_three_phase_core_DC_extended" 9 "AC_core3p_DC_extended" ;
VAL_ 1443 CF_Bms_Combo_InletLock_Req 0 "Unlock Command" 1 "Lock Command" ;
VAL_ 1443 CF_Bms_MainRlyOnStat 0 "Off" 1 "On" ;
VAL_ 1205 CF_AVN_CluUSMReset 0 "Default" 1 "USM Reset" 2 "Reserved" 3 "Invalid" ;
VAL_ 1205 CF_AVN_UnitReset 0 "Default" 1 "Unit Reset" 2 "Reserved" 3 "Invalid" ;
